VERSION "created by canmatrix"

NS_ :

BS_:

BU_: IPD

BO_ 591 ICBVC_BKPCANFD_50ms_FrP55: 12 Vector__XXX
 SG_ DrvrFtgLvl : 15|3@0+ (1,0) [0|7] "null" IPD
 SG_ ICMEyeOnRoad : 20|3@0+ (1,0) [0|7] "null" IPD
 SG_ DrvrDstrctnSts : 31|3@0+ (1,0) [0|7] "null" IPD
 SG_ ICMDrvrDstcnSts : 35|3@0+ (1,0) [0|7] "null" IPD
 SG_ ICMDrvrPrst : 60|3@0+ (1,0) [0|7] "null" IPD
 SG_ ICMDrvrFtgLvl : 63|3@0+ (1,0) [0|7] "null" IPD

BO_ 728 ICBVC_BKPCANFD_Event_FrS138: 24 Vector__XXX
 SG_ AIParkngReqICB : 183|8@0+ (1,0) [0|255] "null" IPD

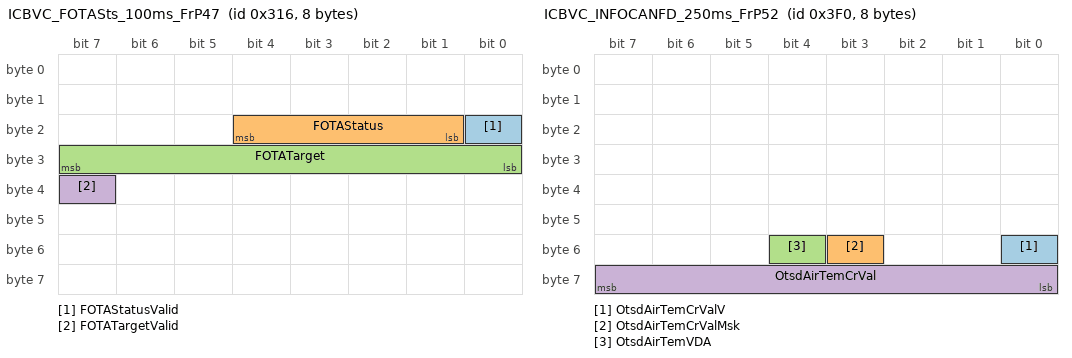
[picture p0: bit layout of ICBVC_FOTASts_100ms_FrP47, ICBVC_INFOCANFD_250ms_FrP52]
BO_ 790 ICBVC_FOTASts_100ms_FrP47: 8 Vector__XXX
 SG_ FOTAStatusValid : 16|1@0+ (1,0) [0|1] "null" IPD
 SG_ FOTAStatus : 20|4@0+ (1,0) [0|15] "null" IPD
 SG_ FOTATarget : 31|8@0+ (1,0) [0|255] "null" IPD
 SG_ FOTATargetValid : 39|1@0+ (1,0) [0|1] "null" IPD

BO_ 1008 ICBVC_INFOCANFD_250ms_FrP52: 8 Vector__XXX
 SG_ OtsdAirTemCrValV : 48|1@0+ (1,0) [0|1] "null" IPD
 SG_ OtsdAirTemCrValMsk : 51|1@0+ (1,0) [0|1] "null" IPD
 SG_ OtsdAirTemVDA : 52|1@0+ (1,0) [0|1] "null" Vector__XXX
 SG_ OtsdAirTemCrVal : 63|8@0+ (0.5,-40) [-40|87.5] "degreeCelsius" IPD

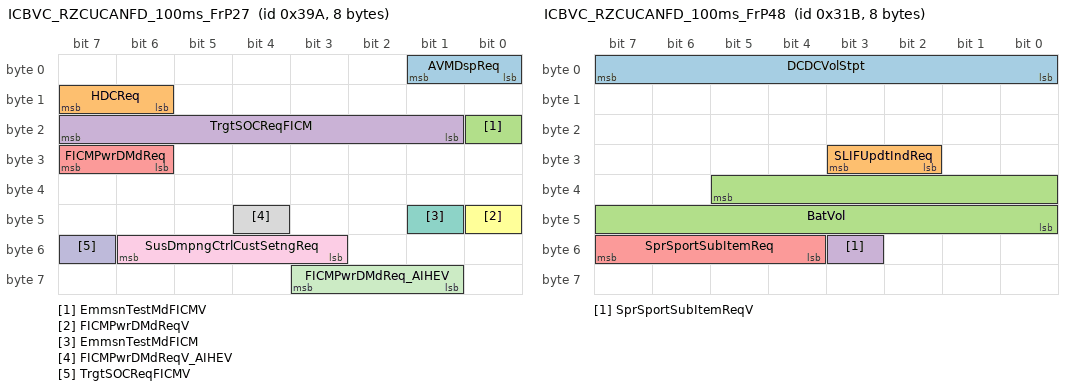
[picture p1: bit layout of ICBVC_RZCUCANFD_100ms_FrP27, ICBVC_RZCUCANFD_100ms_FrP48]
BO_ 922 ICBVC_RZCUCANFD_100ms_FrP27: 8 Vector__XXX
 SG_ AVMDspReq : 1|2@0+ (1,0) [0|3] "null" IPD
 SG_ HDCReq : 15|2@0+ (1,0) [0|3] "null" Vector__XXX
 SG_ EmmsnTestMdFICMV : 16|1@0+ (1,0) [0|1] "null" Vector__XXX
 SG_ TrgtSOCReqFICM : 23|7@0+ (1,0) [0|127] "null" Vector__XXX
 SG_ FICMPwrDMdReq : 31|2@0+ (1,0) [0|3] "null" Vector__XXX
 SG_ FICMPwrDMdReqV : 40|1@0+ (1,0) [0|1] "null" Vector__XXX
 SG_ EmmsnTestMdFICM : 41|1@0+ (1,0) [0|1] "null" Vector__XXX
 SG_ FICMPwrDMdReqV_AIHEV : 44|1@0+ (1,0) [0|1] "null" Vector__XXX
 SG_ SusDmpngCtrlCustSetngReq : 54|4@0+ (1,0) [0|15] "null" Vector__XXX
 SG_ TrgtSOCReqFICMV : 55|1@0+ (1,0) [0|1] "null" Vector__XXX
 SG_ FICMPwrDMdReq_AIHEV : 59|3@0+ (1,0) [0|7] "null" Vector__XXX

BO_ 795 ICBVC_RZCUCANFD_100ms_FrP48: 8 Vector__XXX
 SG_ DCDCVolStpt : 7|8@0+ (0.03125,8.5) [8.50000|16.46875] "V" Vector__XXX
 SG_ SLIFUpdtIndReq : 27|2@0+ (1,0) [0|3] "null" IPD
 SG_ BatVol : 37|14@0+ (0.00097656,3) [3.00000000|18.99898248] "V" Vector__XXX
 SG_ SprSportSubItemReqV : 51|1@0+ (1,0) [0|1] "null" Vector__XXX
 SG_ SprSportSubItemReq : 55|4@0+ (1,0) [0|15] "null" Vector__XXX

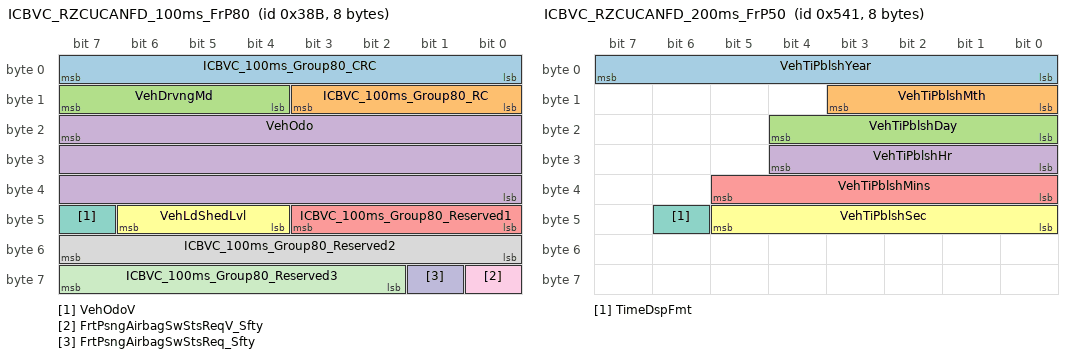
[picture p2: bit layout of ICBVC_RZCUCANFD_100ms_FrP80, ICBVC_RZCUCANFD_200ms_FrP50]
BO_ 907 ICBVC_RZCUCANFD_100ms_FrP80: 8 Vector__XXX
 SG_ ICBVC_100ms_Group80_CRC : 7|8@0+ (1,0) [0|255] "null" IPD
 SG_ ICBVC_100ms_Group80_RC : 11|4@0+ (1,0) [0|15] "null" IPD
 SG_ VehDrvngMd : 15|4@0+ (1,0) [0|15] "null" IPD
 SG_ VehOdo : 23|24@0+ (1,0) [0|16777215] "null" IPD
 SG_ ICBVC_100ms_Group80_Reserved1 : 43|4@0+ (1,0) [0|15] "null" IPD
 SG_ VehLdShedLvl : 46|3@0+ (1,0) [0|7] "null" IPD
 SG_ VehOdoV : 47|1@0+ (1,0) [0|1] "null" IPD
 SG_ ICBVC_100ms_Group80_Reserved2 : 55|8@0+ (1,0) [0|255] "null" IPD
 SG_ FrtPsngAirbagSwStsReqV_Sfty : 56|1@0+ (1,0) [0|1] "null" IPD
 SG_ FrtPsngAirbagSwStsReq_Sfty : 57|1@0+ (1,0) [0|1] "null" IPD
 SG_ ICBVC_100ms_Group80_Reserved3 : 63|6@0+ (1,0) [0|63] "null" IPD

BO_ 1345 ICBVC_RZCUCANFD_200ms_FrP50: 8 Vector__XXX
 SG_ VehTiPblshYear : 7|8@0+ (1,2000) [2000|2255] "year" IPD
 SG_ VehTiPblshMth : 11|4@0+ (1,0) [0|15] "null" IPD
 SG_ VehTiPblshDay : 20|5@0+ (1,0) [0|31] "days" IPD
 SG_ VehTiPblshHr : 28|5@0+ (1,0) [0|31] "hour" IPD
 SG_ VehTiPblshMins : 37|6@0+ (1,0) [0|63] "minute" IPD
 SG_ VehTiPblshSec : 45|6@0+ (1,0) [0|63] "second" IPD
 SG_ TimeDspFmt : 46|1@0+ (1,0) [0|1] "null" Vector__XXX

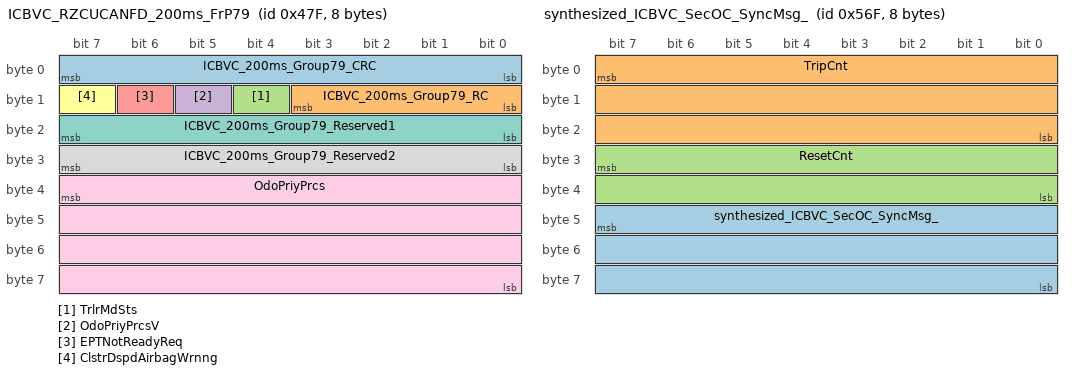
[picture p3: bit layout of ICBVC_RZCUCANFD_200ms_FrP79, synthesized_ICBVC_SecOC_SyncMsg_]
BO_ 1151 ICBVC_RZCUCANFD_200ms_FrP79: 8 Vector__XXX
 SG_ ICBVC_200ms_Group79_CRC : 7|8@0+ (1,0) [0|255] "null" IPD
 SG_ ICBVC_200ms_Group79_RC : 11|4@0+ (1,0) [0|15] "null" IPD
 SG_ TrlrMdSts : 12|1@0+ (1,0) [0|1] "null" IPD
 SG_ OdoPriyPrcsV : 13|1@0+ (1,0) [0|1] "null" IPD
 SG_ EPTNotReadyReq : 14|1@0+ (1,0) [0|1] "null" IPD
 SG_ ClstrDspdAirbagWrnng : 15|1@0+ (1,0) [0|1] "null" IPD
 SG_ ICBVC_200ms_Group79_Reserved1 : 23|8@0+ (1,0) [0|255] "null" IPD
 SG_ ICBVC_200ms_Group79_Reserved2 : 31|8@0+ (1,0) [0|255] "null" IPD
 SG_ OdoPriyPrcs : 39|32@0+ (0.1,0) [0|429496729.5] "null" IPD

BO_ 361 ICBVC_RZCUCANFD_20ms_FrP00: 8 Vector__XXX
 SG_ NFCAMAvlbly : 2|1@0+ (1,0) [0|1] "null" Vector__XXX
 SG_ SASAvlbly : 4|1@0+ (1,0) [0|1] "null" Vector__XXX
 SG_ SDMAvlbly : 5|1@0+ (1,0) [0|1] "null" IPD
 SG_ RHZCUAvlbly : 6|1@0+ (1,0) [0|1] "null" IPD
 SG_ LHZCUAvlbly : 7|1@0+ (1,0) [0|1] "null" IPD
 SG_ TC_ExtdAvlbly : 8|1@0+ (1,0) [0|1] "null" Vector__XXX
 SG_ IBS_SFAvlbly : 9|1@0+ (1,0) [0|1] "null" Vector__XXX
 SG_ EPSAvlbly : 10|1@0+ (1,0) [0|1] "null" IPD
 SG_ TC_PTAvlbly : 12|1@0+ (1,0) [0|1] "null" Vector__XXX
 SG_ PICU_PTAvlbly : 13|1@0+ (1,0) [0|1] "null" IPD
 SG_ LVBM_PTAvlbly : 14|1@0+ (1,0) [0|1] "null" Vector__XXX
 SG_ PEU_PTAvlbly : 16|1@0+ (1,0) [0|1] "null" Vector__XXX
 SG_ PEU_ERAvlbly : 17|1@0+ (1,0) [0|1] "null" Vector__XXX
 SG_ PICU_ExtdAvlbly : 18|1@0+ (1,0) [0|1] "null" Vector__XXX
 SG_ LHRDAAvlbly : 19|1@0+ (1,0) [0|1] "null" Vector__XXX
 SG_ IPD_PTAvlbly : 20|1@0+ (1,0) [0|1] "null" Vector__XXX
 SG_ RHMPWCAvlbly : 21|1@0+ (1,0) [0|1] "null" Vector__XXX
 SG_ ESS_PTAvlbly : 22|1@0+ (1,0) [0|1] "null" Vector__XXX
 SG_ CCU_ExtdAvlbly : 23|1@0+ (1,0) [0|1] "null" Vector__XXX
 SG_ ESS_ExtdAvlbly : 24|1@0+ (1,0) [0|1] "null" Vector__XXX
 SG_ CCU_PTAvlbly : 25|1@0+ (1,0) [0|1] "null" Vector__XXX
 SG_ IAMAvlbly : 26|1@0+ (1,0) [0|1] "null" IPD
 SG_ EAC_Avlbly : 27|1@0+ (1,0) [0|1] "null" Vector__XXX
 SG_ PEU_SFAvlbly : 30|1@0+ (1,0) [0|1] "null" Vector__XXX
 SG_ PEU_ExtdAvlbly : 31|1@0+ (1,0) [0|1] "null" Vector__XXX
 SG_ TDMAvlbly : 32|1@0+ (1,0) [0|1] "null" IPD
 SG_ IPD_SFAvlbly : 33|1@0+ (1,0) [0|1] "null" Vector__XXX
 SG_ SAC_ExtdAvlbly : 35|1@0+ (1,0) [0|1] "null" Vector__XXX
 SG_ SAC_PTAvlbly : 36|1@0+ (1,0) [0|1] "null" Vector__XXX
 SG_ CCEOPAvlbly : 38|1@0+ (1,0) [0|1] "null" Vector__XXX
 SG_ RZCU_BKBCANFDAvlbly : 39|1@0+ (1,0) [0|1] "null" IPD
 SG_ IPD_BKPCANFDAvlbly : 40|1@0+ (1,0) [0|1] "null" Vector__XXX
 SG_ IPD_CHCANFDAvlbly : 41|1@0+ (1,0) [0|1] "null" Vector__XXX
 SG_ IBS_CHAvlbly : 43|1@0+ (1,0) [0|1] "null" IPD
 SG_ FDRAvlbly : 44|1@0+ (1,0) [0|1] "null" Vector__XXX
 SG_ RHRDAAvlbly : 49|1@0+ (1,0) [0|1] "null" Vector__XXX
 SG_ FVCMAvlbly : 51|1@0+ (1,0) [0|1] "null" Vector__XXX
 SG_ TPMSAvlbly : 63|1@0+ (1,0) [0|1] "null" Vector__XXX

BO_ 497 ICBVC_RZCUCANFD_20ms_FrP03: 8 Vector__XXX
 SG_ ICBVC_20ms_Group03_CRC : 7|8@0+ (1,0) [0|255] "null" IPD
 SG_ ICBVC_20ms_Group03_RC : 11|4@0+ (1,0) [0|15] "null" IPD
 SG_ AMRPrtensonReq : 15|4@0+ (1,0) [0|15] "null" IPD
 SG_ ICBVC_20ms_Group03_Reserved2 : 19|4@0+ (1,0) [0|15] "null" IPD
 SG_ SysVolMdV : 20|1@0+ (1,0) [0|1] "null" IPD
 SG_ ICBVC_20ms_Group03_Reserved1 : 23|3@0+ (1,0) [0|7] "null" IPD
 SG_ ICBVC_20ms_Group03_Reserved3 : 27|4@0+ (1,0) [0|15] "null" IPD
 SG_ VehMd : 31|4@0+ (1,0) [0|15] "null" IPD
 SG_ SysVolV : 32|1@0+ (1,0) [0|1] "null" IPD
 SG_ SysPwrMdV : 33|1@0+ (1,0) [0|1] "null" IPD
 SG_ VehMdV : 34|1@0+ (1,0) [0|1] "null" IPD
 SG_ UsgMdV : 35|1@0+ (1,0) [0|1] "null" IPD
 SG_ UsgMd : 39|4@0+ (1,0) [0|15] "null" IPD
 SG_ SysVol : 47|8@0+ (0.1,3) [3|28.5] "V" IPD
 SG_ PwrMdMstrRunCrkA : 48|1@0+ (1,0) [0|1] "null" IPD
 SG_ SysPwrMd : 50|2@0+ (1,0) [0|3] "null" IPD
 SG_ PwrMdMstrAccryA : 51|1@0+ (1,0) [0|1] "null" IPD
 SG_ SysOpnlMd : 55|4@0+ (1,0) [0|15] "null" IPD
 SG_ ICBVC_20ms_Group03_Reserved4 : 60|5@0+ (1,0) [0|31] "null" IPD
 SG_ BPMMstrAvlbly : 61|1@0+ (1,0) [0|1] "null" IPD
 SG_ SysVolMd : 63|2@0+ (1,0) [0|3] "null" IPD

BO_ 60 ICBVC_SecOC_ComKeyReq: 8 Vector__XXX
 SG_ TripCntResetReq : 6|1@0+ (1,0) [0|1] "null" IPD
 SG_ ComKeyEnbReq : 7|1@0+ (1,0) [0|1] "null" IPD

BO_ 1391 synthesized_ICBVC_SecOC_SyncMsg_: 8 Vector__XXX
 SG_ synthesized_ICBVC_SecOC_SyncMsg_ : 47|24@0+ (1,0) [0|16777215] "Unitless" Vector__XXX
 SG_ TripCnt : 7|24@0+ (1,0) [0|16777215] "null" IPD
 SG_ ResetCnt : 31|16@0+ (1,0) [0|65535] "null" IPD

BO_ 815 ICB_BKBCANFD_100ms_FrP146: 8 Vector__XXX
 SG_ EMCLPwrSts : 12|1@0+ (1,0) [0|1] "null" Vector__XXX
 SG_ IMMPwrSts : 14|1@0+ (1,0) [0|1] "null" Vector__XXX
 SG_ ESCLPwrSts : 20|1@0+ (1,0) [0|1] "null" IPD
 SG_ BPEPSPwrSts : 25|1@0+ (1,0) [0|1] "null" Vector__XXX
 SG_ ARHUDPwrSts : 29|1@0+ (1,0) [0|1] "null" Vector__XXX
 SG_ LHAmbtLampPwrSts : 30|1@0+ (1,0) [0|1] "null" Vector__XXX
 SG_ OHCPwrSts : 31|1@0+ (1,0) [0|1] "null" Vector__XXX
 SG_ CnsoDspPwrSts : 33|1@0+ (1,0) [0|1] "null" Vector__XXX
 SG_ FLVntngMotPwrSts : 34|1@0+ (1,0) [0|1] "null" Vector__XXX
 SG_ FLSLMMPwrSts : 35|1@0+ (1,0) [0|1] "null" Vector__XXX
 SG_ USBHubPwrSts : 36|1@0+ (1,0) [0|1] "null" Vector__XXX
 SG_ DrvrDspPwrSts : 37|1@0+ (1,0) [0|1] "null" Vector__XXX
 SG_ SWSPwrSts : 38|1@0+ (1,0) [0|1] "null" Vector__XXX
 SG_ BrkSwPwrSts : 39|1@0+ (1,0) [0|1] "null" Vector__XXX
 SG_ HODMPwrSts : 40|1@0+ (1,0) [0|1] "null" Vector__XXX
 SG_ RLSSPwrSts : 42|1@0+ (1,0) [0|1] "null" Vector__XXX
 SG_ ETCMPwrSts : 43|1@0+ (1,0) [0|1] "null" Vector__XXX
 SG_ LHSWPwrSts : 44|1@0+ (1,0) [0|1] "null" IPD
 SG_ NFCAMPwrSts : 45|1@0+ (1,0) [0|1] "null" Vector__XXX
 SG_ NFCSMPwrSts : 46|1@0+ (1,0) [0|1] "null" Vector__XXX
 SG_ SACPwrSts : 49|1@0+ (1,0) [0|1] "null" Vector__XXX
 SG_ CnsoUSBPwrSts : 50|1@0+ (1,0) [0|1] "null" Vector__XXX
 SG_ RrPDCPwrSts : 51|1@0+ (1,0) [0|1] "null" Vector__XXX
 SG_ FrtPDCPwrSts : 52|1@0+ (1,0) [0|1] "null" Vector__XXX
 SG_ FVCMPwrSts : 55|1@0+ (1,0) [0|1] "null" Vector__XXX
 SG_ TPMSPwrSts : 57|1@0+ (1,0) [0|1] "null" Vector__XXX
 SG_ AIBOTPwrSts : 59|1@0+ (1,0) [0|1] "null" Vector__XXX
 SG_ IterMirPwrSts : 60|1@0+ (1,0) [0|1] "null" Vector__XXX
 SG_ IMSPwrSts : 61|1@0+ (1,0) [0|1] "null" Vector__XXX
 SG_ CPDPwrSts : 62|1@0+ (1,0) [0|1] "null" Vector__XXX
 SG_ DABMPwrSts : 63|1@0+ (1,0) [0|1] "null" Vector__XXX

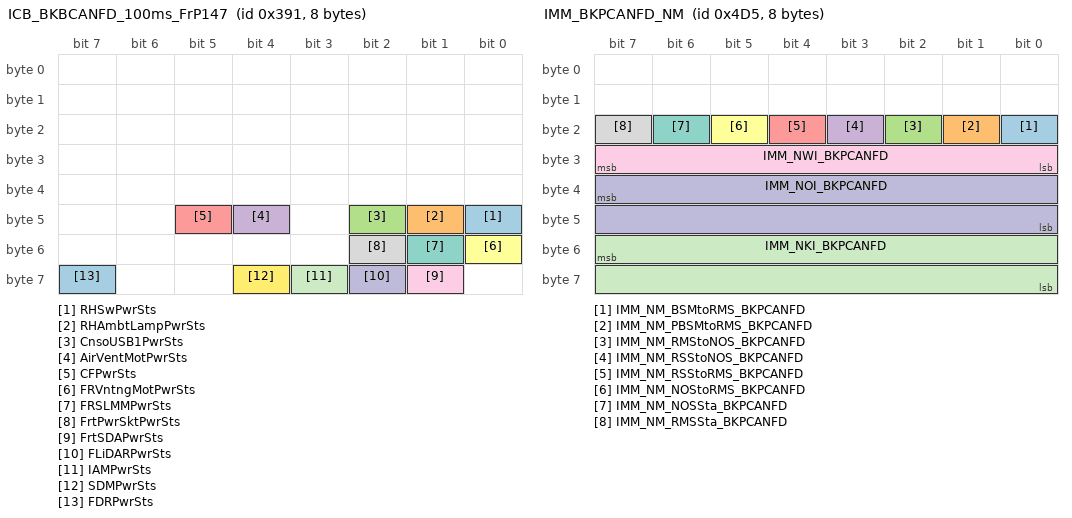
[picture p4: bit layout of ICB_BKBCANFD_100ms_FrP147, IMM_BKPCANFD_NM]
BO_ 913 ICB_BKBCANFD_100ms_FrP147: 8 Vector__XXX
 SG_ RHSwPwrSts : 40|1@0+ (1,0) [0|1] "null" Vector__XXX
 SG_ RHAmbtLampPwrSts : 41|1@0+ (1,0) [0|1] "null" Vector__XXX
 SG_ CnsoUSB1PwrSts : 42|1@0+ (1,0) [0|1] "null" Vector__XXX
 SG_ AirVentMotPwrSts : 44|1@0+ (1,0) [0|1] "null" Vector__XXX
 SG_ CFPwrSts : 45|1@0+ (1,0) [0|1] "null" Vector__XXX
 SG_ FRVntngMotPwrSts : 48|1@0+ (1,0) [0|1] "null" Vector__XXX
 SG_ FRSLMMPwrSts : 49|1@0+ (1,0) [0|1] "null" Vector__XXX
 SG_ FrtPwrSktPwrSts : 50|1@0+ (1,0) [0|1] "null" Vector__XXX
 SG_ FrtSDAPwrSts : 57|1@0+ (1,0) [0|1] "null" Vector__XXX
 SG_ FLiDARPwrSts : 58|1@0+ (1,0) [0|1] "null" IPD
 SG_ IAMPwrSts : 59|1@0+ (1,0) [0|1] "null" Vector__XXX
 SG_ SDMPwrSts : 60|1@0+ (1,0) [0|1] "null" Vector__XXX
 SG_ FDRPwrSts : 63|1@0+ (1,0) [0|1] "null" IPD

BO_ 902 ICB_BKBCANFD_100ms_FrP221: 24 Vector__XXX
 SG_ AVPMapRutMgIDtReq : 71|10@0+ (1,0) [0|1023] "null" IPD
 SG_ IPDPowerFailSwReq : 97|2@0+ (1,0) [0|3] "null" IPD
 SG_ RACtlReq : 111|3@0+ (1,0) [0|7] "null" IPD
 SG_ ShwrmComprEnbReq : 125|1@0+ (1,0) [0|1] "null" Vector__XXX
 SG_ SrfOpenSts : 140|3@0+ (1,0) [0|7] "null" Vector__XXX
 SG_ RainClsWndAppMsg : 183|3@0+ (1,0) [0|7] "null" Vector__XXX

BO_ 955 ICB_BKPCANFD_100ms_FrP159: 64 Vector__XXX
 SG_ ClstrDspdVehSpd_mph : 7|8@0+ (1,0) [0|255] "kph" IPD
 SG_ RrSsdPosCtrl : 15|8@0+ (1,0) [0|255] "null" Vector__XXX
 SG_ ACCTJAMdSwReq : 18|3@0+ (1,0) [0|7] "null" IPD
 SG_ FICMACLTemReq : 23|5@0+ (0.5,15.5) [15.5|31] "null" Vector__XXX
 SG_ SpdLmtOfstSetReq : 31|6@0+ (1,-20) [-20|43] "null" IPD
 SG_ ACCStsSwReq : 33|2@0+ (1,0) [0|3] "null" IPD
 SG_ ACCSpdLimtSwReq : 35|2@0+ (1,0) [0|3] "null" IPD
 SG_ ACCCurveSpdSwReq : 37|2@0+ (1,0) [0|3] "null" IPD
 SG_ ACCConfmSwReq : 39|2@0+ (1,0) [0|3] "null" IPD
 SG_ ACUserCustEcoSetngReqV : 40|1@0+ (1,0) [0|1] "null" Vector__XXX
 SG_ ACUserCustEcoSetngReq : 42|2@0+ (1,0) [0|3] "null" Vector__XXX
 SG_ ACUserCustAutoMdBlwrReqV : 43|1@0+ (1,0) [0|1] "null" Vector__XXX
 SG_ ACUserCustAutoMdBlwrReq : 45|2@0+ (1,0) [0|3] "null" Vector__XXX
 SG_ ACUserCustAftRunOnOffReqV : 46|1@0+ (1,0) [0|1] "null" Vector__XXX
 SG_ ACUserCustAftRunOnOffR : 47|1@0+ (1,0) [0|1] "null" Vector__XXX
 SG_ FICMACFrtBlwrSpdDecSwR : 49|2@0+ (1,0) [0|3] "null" Vector__XXX
 SG_ FICMACAutoSwReq : 51|2@0+ (1,0) [0|3] "null" Vector__XXX
 SG_ ADAudioSWReq : 55|2@0+ (1,0) [0|3] "null" IPD
 SG_ FICMACLTemDecSwReq : 57|2@0+ (1,0) [0|3] "null" Vector__XXX
 SG_ FICMACFrtBlwrSpdIncSwR : 59|2@0+ (1,0) [0|3] "null" Vector__XXX
 SG_ FICMACFrtBlwrLvlReq : 63|4@0+ (1,0) [0|15] "null" Vector__XXX
 SG_ FICMACOnOffSwReq : 65|2@0+ (1,0) [0|3] "null" Vector__XXX
 SG_ FICMACLTemIncSwReq : 67|2@0+ (1,0) [0|3] "null" Vector__XXX
 SG_ FICMACLAirMdReqV : 68|1@0+ (1,0) [0|1] "null" Vector__XXX
 SG_ FICMACLAirMdReq : 71|3@0+ (1,0) [0|7] "null" Vector__XXX
 SG_ FICMComprOnOffSwReq : 73|2@0+ (1,0) [0|3] "null" Vector__XXX
 SG_ FICMACSemiAutoSwReq : 75|2@0+ (1,0) [0|3] "null" Vector__XXX
 SG_ FICMACRcctnSwReq : 77|2@0+ (1,0) [0|3] "null" Vector__XXX
 SG_ FICMACRcctnMdReq : 79|2@0+ (1,0) [0|3] "null" Vector__XXX
 SG_ FICMHtdRrWndSwReq : 81|2@0+ (1,0) [0|3] "null" Vector__XXX
 SG_ FICMDfstOnSwReq : 83|2@0+ (1,0) [0|3] "null" Vector__XXX
 SG_ FICMACLTemV : 87|1@0+ (1,0) [0|1] "null" Vector__XXX
 SG_ TLRMdSwReq : 90|3@0+ (1,0) [0|7] "null" IPD
 SG_ TSRSwReq : 97|2@0+ (1,0) [0|3] "null" IPD
 SG_ NonDirectDMSSwReq : 99|2@0+ (1,0) [0|3] "null" IPD
 SG_ SpdLmtOfstSetNumReq : 103|4@0+ (1,0) [0|15] "null" IPD
 SG_ ILCSwReq : 108|2@0+ (1,0) [0|3] "null" IPD
 SG_ ASSInhBtnA : 109|1@0+ (1,0) [0|1] "null" Vector__XXX
 SG_ ClstrElecCsumpUnit : 114|3@0+ (1,0) [0|7] "null" Vector__XXX
 SG_ SpdLmtOfstSetPercReq : 127|3@0+ (1,0) [0|7] "null" IPD
 SG_ EBSBatSOFVol1 : 143|8@0+ (0.0625,0) [0.0000|15.9375] "null" Vector__XXX
 SG_ EBSBatSOFVol2 : 151|8@0+ (0.0625,0) [0.0000|15.9375] "null" Vector__XXX
 SG_ EBSBatSOFVol2Sts : 153|2@0+ (1,0) [0|3] "null" Vector__XXX
 SG_ GenrExctnCrnt : 159|6@0+ (0.125,0) [0.000|7.875] "null" Vector__XXX
 SG_ ASSStsFICM : 160|1@0+ (1,0) [0|1] "null" Vector__XXX
 SG_ EBSBatSOFVol1Sts : 162|2@0+ (1,0) [0|3] "null" Vector__XXX
 SG_ GenrExctnDutyCyc : 167|5@0+ (3.333,0) [0.000|103.323] "null" Vector__XXX
 SG_ IACCPreSpdLimtSwReq : 169|2@0+ (1,0) [0|3] "null" IPD
 SG_ PMDCIlgclIdficn : 170|1@0+ (1,0) [0|1] "null" Vector__XXX
 SG_ EBSBatIncnstncyFlag : 171|1@0+ (1,0) [0|1] "null" Vector__XXX
 SG_ ASSStsFICMV : 172|1@0+ (1,0) [0|1] "null" Vector__XXX
 SG_ PMDCIlgclCal : 173|1@0+ (1,0) [0|1] "null" Vector__XXX
 SG_ IdleBstLvl : 175|2@0+ (1,0) [0|3] "null" Vector__XXX
 SG_ ExtnlTstrDet : 176|1@0+ (1,0) [0|1] "null" Vector__XXX
 SG_ TiltSnsrSetngReq : 178|2@0+ (1,0) [0|3] "null" Vector__XXX
 SG_ RrSsdAppCtrl : 180|2@0+ (1,0) [0|3] "null" Vector__XXX
 SG_ IACCOvTSuppresSwReq : 183|3@0+ (1,0) [0|7] "null" IPD
 SG_ TrgtSOCReqAI : 185|10@0+ (0.1,0) [0|102.3] "null" Vector__XXX
 SG_ DMSHapticWrnngReq : 187|2@0+ (1,0) [0|3] "null" Vector__XXX
 SG_ DMSAdoWrnngReq : 189|2@0+ (1,0) [0|3] "null" Vector__XXX
 SG_ VolmcSnsrSetngReq : 191|2@0+ (1,0) [0|3] "null" Vector__XXX
 SG_ DMSDstrctnHptWrnngReq : 201|2@0+ (1,0) [0|3] "null" Vector__XXX
 SG_ DMSDstrctnAdoWrnngReq : 203|2@0+ (1,0) [0|3] "null" Vector__XXX
 SG_ DMSDstrctnSwReq : 205|2@0+ (1,0) [0|3] "null" Vector__XXX
 SG_ DMSSwReq : 207|2@0+ (1,0) [0|3] "null" Vector__XXX
 SG_ FICMInnrDschrgReq : 212|1@0+ (1,0) [0|1] "null" Vector__XXX
 SG_ OMSSwReq : 214|2@0+ (1,0) [0|3] "null" Vector__XXX
 SG_ TrgtSOCReqAIV : 215|1@0+ (1,0) [0|1] "null" Vector__XXX
 SG_ OMSBabyCareReq : 241|2@0+ (1,0) [0|3] "null" Vector__XXX
 SG_ OmsGesDetSwReq : 243|2@0+ (1,0) [0|3] "null" Vector__XXX
 SG_ OmsIlbRemSwReq : 245|2@0+ (1,0) [0|3] "null" Vector__XXX
 SG_ AIParkngSSPLotSw : 247|2@0+ (1,0) [0|3] "null" IPD
 SG_ TakeKeyOutRmndrPersSetReq : 322|2@0+ (1,0) [0|3] "null" Vector__XXX
 SG_ CmftUnlckPersSetReq : 324|2@0+ (1,0) [0|3] "null" Vector__XXX
 SG_ CmftLckPersSetReq : 326|2@0+ (1,0) [0|3] "null" Vector__XXX

BO_ 746 ICB_BKPCANFD_100ms_FrP82: 8 Vector__XXX
 SG_ FCTSysSelReq : 13|2@0+ (1,0) [0|3] "null" IPD

BO_ 1297 ICB_BKPCANFD_500ms_FrP229: 20 Vector__XXX
 SG_ NavCtryCode_ISO : 23|10@0+ (1,0) [0|1023] "null" IPD

BO_ 368 ICB_BKPCANFD_50ms_FrP158: 16 Vector__XXX
 SG_ ICBVC_50ms_Group158_CRC : 7|8@0+ (1,0) [0|255] "null" IPD
 SG_ ICBVC_50ms_Group158_RC : 11|4@0+ (1,0) [0|15] "null" IPD
 SG_ CCSpdDecAndIncVcCmd : 13|2@0+ (1,0) [0|3] "null" IPD
 SG_ CCDisDecAndIncVcCmd : 15|2@0+ (1,0) [0|3] "null" IPD
 SG_ ICBVC_50ms_Group158_Reserved1 : 19|4@0+ (1,0) [0|15] "null" IPD
 SG_ CCSwStsSetSwA : 20|1@0+ (1,0) [0|1] "null" IPD
 SG_ CCSwStsCCASwA : 21|1@0+ (1,0) [0|1] "null" IPD
 SG_ CCSpdVcCmdSwReq : 23|2@0+ (1,0) [0|3] "null" IPD
 SG_ CCSpdVcCmd : 31|8@0+ (1,0) [0|255] "null" IPD
 SG_ ICBVC_50ms_Group158_Reserved2 : 39|8@0+ (1,0) [0|255] "null" IPD
 SG_ ICBVC_50ms_Group158_Reserved3 : 44|5@0+ (1,0) [0|31] "null" IPD
 SG_ CCDisAdjtVcCmd : 47|3@0+ (1,0) [0|7] "null" IPD
 SG_ ICBVC_50ms_Group158_Reserved4 : 55|8@0+ (1,0) [0|255] "null" IPD
 SG_ ICBVC_50ms_Group158_Reserved5 : 63|8@0+ (1,0) [0|255] "null" IPD
 SG_ ICBVC_50ms_Group158_Reserved6 : 71|8@0+ (1,0) [0|255] "null" IPD
 SG_ ICBVC_50ms_Group158_Reserved7 : 79|8@0+ (1,0) [0|255] "null" IPD
 SG_ ICBVC_50ms_Group158_Reserved8 : 87|8@0+ (1,0) [0|255] "null" IPD
 SG_ ICBVC_50ms_Group158_Reserved9 : 95|8@0+ (1,0) [0|255] "null" IPD
 SG_ ICBVC_50ms_Group158_Reserved10 : 103|8@0+ (1,0) [0|255] "null" IPD
 SG_ ICBVC_50ms_Group158_Reserved11 : 111|8@0+ (1,0) [0|255] "null" IPD
 SG_ ICBVC_50ms_Group158_Reserved12 : 119|8@0+ (1,0) [0|255] "null" IPD
 SG_ ICBVC_50ms_Group158_Reserved13 : 127|8@0+ (1,0) [0|255] "null" IPD

BO_ 1389 ICB_CONNCANFD_Event_FrS67: 16 Vector__XXX
 SG_ IdentityChlg : 71|64@0+ (1,0) [0|18446744073709551615] "null" IPD

BO_ 1111 ICB_ZONE_BDCAN_100ms_FrP00: 32 Vector__XXX
 SG_ ICCPCBTemp1 : 7|8@0+ (1,-40) [-40|215] "" Vector__XXX
 SG_ ICCPCBTemp2 : 15|8@0+ (1,-40) [-40|215] "" Vector__XXX
 SG_ ICCPCBTemp3 : 23|8@0+ (1,-40) [-40|215] "" Vector__XXX
 SG_ ICCPCBTemp4 : 31|8@0+ (1,-40) [-40|215] "" Vector__XXX
 SG_ ICCPCBTemp5 : 39|8@0+ (1,-40) [-40|215] "" Vector__XXX
 SG_ ICCThermalCoolingLvl : 47|4@0+ (1,0) [0|15] "null" Vector__XXX
 SG_ FICMV2XEnEnbReq : 81|2@0+ (1,0) [0|3] "null" Vector__XXX
 SG_ ElecPwrDistbnScene : 95|64@0+ (1,0) [0|18446744073709551615] "null" IPD
 SG_ AltngChrgCrntReq : 159|8@0+ (1,0) [0|255] "null" Vector__XXX
 SG_ DschrgTrgtSOCVal : 167|7@0+ (1,0) [0|127] "null" Vector__XXX

BO_ 527 IMM_BKPCANFD_50ms_FrP02: 24 Vector__XXX
 SG_ IMM_50ms_Group02_CRC : 7|8@0+ (1,0) [0|255] "null" IPD
 SG_ IMM_50ms_Group02_RC : 11|4@0+ (1,0) [0|15] "null" IPD
 SG_ IMM_50ms_Group02_Reserved1 : 15|4@0+ (1,0) [0|15] "null" IPD
 SG_ DrvrDstcnStsINST_IMM : 19|4@0+ (1,0) [0|15] "null" IPD
 SG_ ILBRReq_IMM : 23|4@0+ (1,0) [0|15] "null" IPD
 SG_ DrvrAbnormBehvor_IMM : 27|4@0+ (1,0) [0|15] "null" IPD
 SG_ DMSSts_IMM : 31|4@0+ (1,0) [0|15] "null" IPD
 SG_ IMM_50ms_Group02_Reserved2 : 33|2@0+ (1,0) [0|3] "null" IPD
 SG_ SpfngDet_IMM : 35|2@0+ (1,0) [0|3] "null" IPD
 SG_ DrvrDstcnSts_IMM : 39|4@0+ (1,0) [0|15] "null" IPD
 SG_ OMSSts_IMM : 42|3@0+ (1,0) [0|7] "null" IPD
 SG_ DrvrFtgLvlINST_IMM : 47|5@0+ (1,0) [0|31] "null" IPD
 SG_ IMM_50ms_Group02_Reserved3 : 50|3@0+ (1,0) [0|7] "null" IPD
 SG_ DrvrFtgLvl_IMM : 55|5@0+ (1,0) [0|31] "null" IPD
 SG_ DrvrPrst_IMM : 58|3@0+ (1,0) [0|7] "null" IPD
 SG_ DrvrGazeRgn_IMM : 63|5@0+ (1,0) [0|31] "null" IPD
 SG_ IMM_50ms_Group02_Reserved4 : 71|8@0+ (1,0) [0|255] "null" IPD
 SG_ EyeOpenStatus_IMM : 73|2@0+ (1,0) [0|3] "null" IPD
 SG_ IMM_50ms_Group02_Reserved5 : 79|6@0+ (1,0) [0|63] "null" IPD
 SG_ IMM_50ms_Group02_Reserved6 : 80|1@0+ (1,0) [0|1] "null" IPD
 SG_ RightEyeOccludeStatus_IMM : 82|2@0+ (1,0) [0|3] "null" IPD
 SG_ LeftEyeOccludeStatus_IMM : 84|2@0+ (1,0) [0|3] "null" IPD
 SG_ EyeOnRoad_IMM : 87|3@0+ (1,0) [0|7] "null" IPD
 SG_ DrvrFtgConf_IMM : 95|8@0+ (0.01,0) [0.00|2.55] "null" IPD
 SG_ DrvrDstcnConf_IMM : 103|8@0+ (0.01,0) [0.00|2.55] "null" IPD
 SG_ DrvrAbnormConf_IMM : 111|8@0+ (0.01,0) [0.00|2.55] "null" IPD
 SG_ EyeGazepitch_IMM : 119|8@0- (1,0) [-128|127] "null" IPD
 SG_ EyeGazeyaw_IMM : 127|8@0- (1,0) [-128|127] "null" IPD
 SG_ EyeOpenDegree_IMM : 135|8@0+ (0.01,0) [0.00|2.55] "null" IPD
 SG_ IMM_50ms_Group02_Reserved143 : 143|8@0+ (1,0) [0|255] "null" IPD
 SG_ IMM_50ms_Group02_Reserved151 : 151|8@0+ (1,0) [0|255] "null" IPD
 SG_ IMM_50ms_Group02_Reserved159 : 159|8@0+ (1,0) [0|255] "null" IPD
 SG_ IMM_50ms_Group02_Reserved7 : 163|4@0+ (1,0) [0|15] "null" IPD
 SG_ MouthOccludeStatus_IMM : 165|2@0+ (1,0) [0|3] "null" IPD
 SG_ YawnStatus_IMM : 167|2@0+ (1,0) [0|3] "null" IPD
 SG_ IMM_50ms_Group02_Reserved8 : 175|8@0+ (1,0) [0|255] "null" IPD
 SG_ IMM_50ms_Group02_Reserved9 : 183|8@0+ (1,0) [0|255] "null" IPD
 SG_ IMM_50ms_Group02_Reserved10 : 191|8@0+ (1,0) [0|255] "null" IPD

BO_ 657 IMM_BKPCANFD_50ms_FrP04: 64 Vector__XXX
 SG_ DMSCameraFps_IMM : 7|8@0+ (1,0) [0|255] "null" IPD

BO_ 1237 IMM_BKPCANFD_NM: 8 Vector__XXX
 SG_ IMM_NM_BSMtoRMS_BKPCANFD : 16|1@0+ (1,0) [0|1] "null" Vector__XXX
 SG_ IMM_NM_PBSMtoRMS_BKPCANFD : 17|1@0+ (1,0) [0|1] "null" Vector__XXX
 SG_ IMM_NM_RMStoNOS_BKPCANFD : 18|1@0+ (1,0) [0|1] "null" Vector__XXX
 SG_ IMM_NM_RSStoNOS_BKPCANFD : 19|1@0+ (1,0) [0|1] "null" Vector__XXX
 SG_ IMM_NM_RSStoRMS_BKPCANFD : 20|1@0+ (1,0) [0|1] "null" Vector__XXX
 SG_ IMM_NM_NOStoRMS_BKPCANFD : 21|1@0+ (1,0) [0|1] "null" Vector__XXX
 SG_ IMM_NM_NOSSta_BKPCANFD : 22|1@0+ (1,0) [0|1] "null" Vector__XXX
 SG_ IMM_NM_RMSSta_BKPCANFD : 23|1@0+ (1,0) [0|1] "null" Vector__XXX
 SG_ IMM_NWI_BKPCANFD : 31|8@0+ (1,0) [0|255] "null" Vector__XXX
 SG_ IMM_NOI_BKPCANFD : 39|16@0+ (1,0) [0|65535] "null" Vector__XXX
 SG_ IMM_NKI_BKPCANFD : 55|16@0+ (1,0) [0|65535] "null" Vector__XXX

BO_ 1767 IPD_BKBCANFD_EvtInfo: 64 IPD
 SG_ EvtPotclSigIPD1 : 7|64@0+ (1,0) [0|18446744073709551615] "null" Vector__XXX
 SG_ EvtPotclSigIPD2 : 71|64@0+ (1,0) [0|18446744073709551615] "null" Vector__XXX
 SG_ EvtPotclSigIPD3 : 135|64@0+ (1,0) [0|18446744073709551615] "null" Vector__XXX
 SG_ EvtPotclSigIPD4 : 199|64@0+ (1,0) [0|18446744073709551615] "null" Vector__XXX
 SG_ EvtPotclSigIPD5 : 263|64@0+ (1,0) [0|18446744073709551615] "null" Vector__XXX
 SG_ EvtPotclSigIPD6 : 327|64@0+ (1,0) [0|18446744073709551615] "null" Vector__XXX
 SG_ EvtPotclSigIPD7 : 391|64@0+ (1,0) [0|18446744073709551615] "null" Vector__XXX
 SG_ EvtPotclSigIPD8 : 455|64@0+ (1,0) [0|18446744073709551615] "null" Vector__XXX

CM_ SG_ 1391 synthesized_ICBVC_SecOC_SyncMsg_ "Truncated Auth-Info";

BA_DEF_ BO_ "FrameTriggeringName" STRING;
BA_DEF_ BO_ "GenMsgCycleTime" INT 0 65535;
BA_DEF_ BO_ "GenMsgDelayTime" INT 0 65535;
BA_DEF_ BO_ "GenMsgSendType" ENUM  "cyclicX","spontanX","cyclicIfActiveX","spontanWithDelay","cyclicAndSpontanX","cyclicAndSpontanWithDelay","spontanWithRepitition","cyclicIfActiveAndSpontanWD","cyclicIfActiveFast","cyclicWithRepeatOnDemand","none";
BA_DEF_ BO_ "GenMsgStartValue" STRING;
BA_DEF_ BO_ "PduName" STRING;
BA_DEF_ BO_ "SystemMessageLongSymbol" STRING;
BA_DEF_ BO_ "VFrameFormat" ENUM  "StandardCAN","ExtendedCAN","reserved","reserved","reserved","reserved","reserved","reserved","reserved","reserved","reserved","reserved","reserved","reserved","StandardCAN_FD","ExtendedCAN_FD";
BA_DEF_ SG_ "CompuMethodName" STRING;
BA_DEF_ SG_ "GenSigStartValue" FLOAT 0 100000000000;
BA_DEF_ SG_ "ISignalName" STRING;
BA_DEF_ SG_ "LongName" STRING;
BA_DEF_ SG_ "SysSignalName" STRING;
BA_DEF_ SG_ "SystemSignalLongSymbol" STRING;
BA_ "FrameTriggeringName" BO_ 591 "ICBVC_BKPCANFD_50ms_FrP55";
BA_ "GenMsgCycleTime" BO_ 591 50;
BA_ "GenMsgSendType" BO_ 591 0;
BA_ "GenMsgStartValue" BO_ 591 "000000000000000000000000";
BA_ "PduName" BO_ 591 "ICBVC_50ms_PDU55";
BA_ "VFrameFormat" BO_ 591 14;
BA_ "FrameTriggeringName" BO_ 728 "ICBVC_BKPCANFD_Event_FrS138";
BA_ "GenMsgSendType" BO_ 728 1;
BA_ "GenMsgStartValue" BO_ 728 "000000000000000000000000000000000000000000000000";
BA_ "PduName" BO_ 728 "ICBVC_Sporadic_PDU138";
BA_ "VFrameFormat" BO_ 728 14;
BA_ "FrameTriggeringName" BO_ 790 "ICBVC_FOTASts_100ms_FrP47";
BA_ "GenMsgCycleTime" BO_ 790 100;
BA_ "GenMsgSendType" BO_ 790 0;
BA_ "GenMsgStartValue" BO_ 790 "0000010080000000";
BA_ "PduName" BO_ 790 "ICBVC_100ms_PDU47";
BA_ "VFrameFormat" BO_ 790 14;
BA_ "FrameTriggeringName" BO_ 1008 "ICBVC_INFOCANFD_250ms_FrP52";
BA_ "GenMsgCycleTime" BO_ 1008 250;
BA_ "GenMsgSendType" BO_ 1008 0;
BA_ "GenMsgStartValue" BO_ 1008 "0000000000000100";
BA_ "PduName" BO_ 1008 "ICBVC_250ms_PDU52";
BA_ "VFrameFormat" BO_ 1008 14;
BA_ "FrameTriggeringName" BO_ 922 "ICBVC_RZCUCANFD_100ms_FrP27";
BA_ "GenMsgCycleTime" BO_ 922 100;
BA_ "GenMsgSendType" BO_ 922 0;
BA_ "GenMsgStartValue" BO_ 922 "0000010000110000";
BA_ "PduName" BO_ 922 "ICBVC_100ms_PDU27";
BA_ "VFrameFormat" BO_ 922 14;
BA_ "FrameTriggeringName" BO_ 795 "ICBVC_RZCUCANFD_100ms_FrP48";
BA_ "GenMsgCycleTime" BO_ 795 100;
BA_ "GenMsgSendType" BO_ 795 0;
BA_ "GenMsgStartValue" BO_ 795 "fe00000000000000";
BA_ "PduName" BO_ 795 "ICBVC_100ms_PDU48";
BA_ "VFrameFormat" BO_ 795 14;
BA_ "FrameTriggeringName" BO_ 907 "ICBVC_RZCUCANFD_100ms_FrP80";
BA_ "GenMsgCycleTime" BO_ 907 100;
BA_ "GenMsgSendType" BO_ 907 0;
BA_ "GenMsgStartValue" BO_ 907 "00300000008ffffc";
BA_ "PduName" BO_ 907 "ICBVC_100ms_PDU80";
BA_ "VFrameFormat" BO_ 907 14;
BA_ "FrameTriggeringName" BO_ 1345 "ICBVC_RZCUCANFD_200ms_FrP50";
BA_ "GenMsgCycleTime" BO_ 1345 200;
BA_ "GenMsgSendType" BO_ 1345 0;
BA_ "GenMsgStartValue" BO_ 1345 "1300000000000000";
BA_ "PduName" BO_ 1345 "ICBVC_200ms_PDU50";
BA_ "VFrameFormat" BO_ 1345 14;
BA_ "FrameTriggeringName" BO_ 1151 "ICBVC_RZCUCANFD_200ms_FrP79";
BA_ "GenMsgCycleTime" BO_ 1151 200;
BA_ "GenMsgSendType" BO_ 1151 0;
BA_ "GenMsgStartValue" BO_ 1151 "0020ffff00000000";
BA_ "PduName" BO_ 1151 "ICBVC_200ms_PDU79";
BA_ "VFrameFormat" BO_ 1151 14;
BA_ "FrameTriggeringName" BO_ 361 "ICBVC_RZCUCANFD_20ms_FrP00";
BA_ "GenMsgCycleTime" BO_ 361 20;
BA_ "GenMsgSendType" BO_ 361 0;
BA_ "GenMsgStartValue" BO_ 361 "0000000000000000";
BA_ "PduName" BO_ 361 "ICBVC_20ms_PDU00";
BA_ "VFrameFormat" BO_ 361 14;
BA_ "FrameTriggeringName" BO_ 497 "ICBVC_RZCUCANFD_20ms_FrP03";
BA_ "GenMsgCycleTime" BO_ 497 20;
BA_ "GenMsgSendType" BO_ 497 0;
BA_ "GenMsgStartValue" BO_ 497 "0000ff0f1200001f";
BA_ "PduName" BO_ 497 "ICBVC_20ms_PDU03";
BA_ "VFrameFormat" BO_ 497 14;
BA_ "FrameTriggeringName" BO_ 60 "ICBVC_SecOC_ComKeyReq";
BA_ "GenMsgSendType" BO_ 60 1;
BA_ "GenMsgStartValue" BO_ 60 "0000000000000000";
BA_ "PduName" BO_ 60 "ICBVC_SecOCComKeyReq_PDU01";
BA_ "VFrameFormat" BO_ 60 14;
BA_ "FrameTriggeringName" BO_ 1391 "ICBVC_SecOC_SyncMsg";
BA_ "GenMsgDelayTime" BO_ 1391 5;
BA_ "GenMsgSendType" BO_ 1391 1;
BA_ "GenMsgStartValue" BO_ 1391 "0000010001000000";
BA_ "PduName" BO_ 1391 "ICBVC_SecOC_SyncMsg";
BA_ "SystemMessageLongSymbol" BO_ 1391 "synthesized_ICBVC_SecOC_SyncMsg_BKPCANFD";
BA_ "VFrameFormat" BO_ 1391 14;
BA_ "FrameTriggeringName" BO_ 815 "ICB_BKBCANFD_100ms_FrP146";
BA_ "GenMsgCycleTime" BO_ 815 100;
BA_ "GenMsgSendType" BO_ 815 0;
BA_ "GenMsgStartValue" BO_ 815 "0000000000000000";
BA_ "PduName" BO_ 815 "ICB_100ms_PDU146";
BA_ "VFrameFormat" BO_ 815 14;
BA_ "FrameTriggeringName" BO_ 913 "ICB_BKBCANFD_100ms_FrP147";
BA_ "GenMsgCycleTime" BO_ 913 100;
BA_ "GenMsgSendType" BO_ 913 0;
BA_ "GenMsgStartValue" BO_ 913 "0000000000000000";
BA_ "PduName" BO_ 913 "ICB_100ms_PDU147";
BA_ "VFrameFormat" BO_ 913 14;
BA_ "FrameTriggeringName" BO_ 902 "ICB_BKBCANFD_100ms_FrP221";
BA_ "GenMsgCycleTime" BO_ 902 100;
BA_ "GenMsgSendType" BO_ 902 0;
BA_ "GenMsgStartValue" BO_ 902 "000000000000000000000000000000000018000000000000";
BA_ "PduName" BO_ 902 "ICB_100ms_PDU221";
BA_ "VFrameFormat" BO_ 902 14;
BA_ "FrameTriggeringName" BO_ 955 "ICB_BKPCANFD_100ms_FrP159";
BA_ "GenMsgCycleTime" BO_ 955 100;
BA_ "GenMsgSendType" BO_ 955 0;
BA_ "GenMsgStartValue" BO_ 955 "00fff85000590000f0c0800000000000008898224c10000000008000000000000000000000000000000000000000000000000000000000000000000000000000";
BA_ "PduName" BO_ 955 "ICB_100ms_PDU159";
BA_ "VFrameFormat" BO_ 955 14;
BA_ "FrameTriggeringName" BO_ 746 "ICB_BKPCANFD_100ms_FrP82";
BA_ "GenMsgCycleTime" BO_ 746 100;
BA_ "GenMsgSendType" BO_ 746 0;
BA_ "GenMsgStartValue" BO_ 746 "0000000000000000";
BA_ "PduName" BO_ 746 "ICB_100ms_PDU82";
BA_ "VFrameFormat" BO_ 746 14;
BA_ "FrameTriggeringName" BO_ 1297 "ICB_BKPCANFD_500ms_FrP229";
BA_ "GenMsgCycleTime" BO_ 1297 500;
BA_ "GenMsgSendType" BO_ 1297 0;
BA_ "GenMsgStartValue" BO_ 1297 "0000000000000000000000000000000000000000";
BA_ "PduName" BO_ 1297 "ICB_500ms_PDU229";
BA_ "VFrameFormat" BO_ 1297 14;
BA_ "FrameTriggeringName" BO_ 368 "ICB_BKPCANFD_50ms_FrP158";
BA_ "GenMsgCycleTime" BO_ 368 50;
BA_ "GenMsgSendType" BO_ 368 0;
BA_ "GenMsgStartValue" BO_ 368 "00000f00ff1fffffffffffffffffffff";
BA_ "PduName" BO_ 368 "ICBVC_50ms_PDU158";
BA_ "VFrameFormat" BO_ 368 14;
BA_ "FrameTriggeringName" BO_ 1389 "ICB_CONNCANFD_Event_FrS67";
BA_ "GenMsgSendType" BO_ 1389 1;
BA_ "GenMsgStartValue" BO_ 1389 "00000000000000000000000000000000";
BA_ "PduName" BO_ 1389 "ICB_Sporadic_PDU67";
BA_ "VFrameFormat" BO_ 1389 14;
BA_ "FrameTriggeringName" BO_ 1111 "ICB_ZONE_BDCAN_100ms_FrP00";
BA_ "GenMsgCycleTime" BO_ 1111 100;
BA_ "GenMsgSendType" BO_ 1111 0;
BA_ "GenMsgStartValue" BO_ 1111 "ffffffffff100000000000000000000000000020000000000000000000000000";
BA_ "PduName" BO_ 1111 "ICB_ZONE_100ms_PDU00";
BA_ "VFrameFormat" BO_ 1111 14;
BA_ "FrameTriggeringName" BO_ 527 "IMM_BKPCANFD_50ms_FrP02";
BA_ "GenMsgCycleTime" BO_ 527 50;
BA_ "GenMsgSendType" BO_ 527 0;
BA_ "GenMsgStartValue" BO_ 527 "00f0000003000700fffc01000000000000ffffff0fffffff";
BA_ "PduName" BO_ 527 "IMM_50ms_PDU02";
BA_ "VFrameFormat" BO_ 527 14;
BA_ "FrameTriggeringName" BO_ 657 "IMM_BKPCANFD_50ms_FrP04";
BA_ "GenMsgCycleTime" BO_ 657 50;
BA_ "GenMsgSendType" BO_ 657 0;
BA_ "GenMsgStartValue" BO_ 657 "00000000000000000000000000000000000000000000000000000000000000000000000000000000000000000000000000000000000000000000000000000000";
BA_ "PduName" BO_ 657 "IMM_50ms_PDU04";
BA_ "VFrameFormat" BO_ 657 14;
BA_ "FrameTriggeringName" BO_ 1237 "IMM_BKPCANFD_NM";
BA_ "GenMsgSendType" BO_ 1237 1;
BA_ "GenMsgStartValue" BO_ 1237 "0000000000000000";
BA_ "PduName" BO_ 1237 "NmPDU_BKPCANFD_IMM";
BA_ "VFrameFormat" BO_ 1237 14;
BA_ "FrameTriggeringName" BO_ 1767 "IPD_BKBCANFD_EvtInfo";
BA_ "GenMsgSendType" BO_ 1767 1;
BA_ "GenMsgStartValue" BO_ 1767 "00000000000000000000000000000000000000000000000000000000000000000000000000000000000000000000000000000000000000000000000000000000";
BA_ "PduName" BO_ 1767 "IPD_BKBCANFD_EvtInfo";
BA_ "VFrameFormat" BO_ 1767 14;
BA_ "CompuMethodName" SG_ 591 DrvrFtgLvl "DrvrFtgLvl";
BA_ "ISignalName" SG_ 591 DrvrFtgLvl "IDrvrFtgLvl";
BA_ "SysSignalName" SG_ 591 DrvrFtgLvl "DrvrFtgLvl";
BA_ "CompuMethodName" SG_ 591 ICMEyeOnRoad "ICMEyeOnRoad";
BA_ "ISignalName" SG_ 591 ICMEyeOnRoad "IICMEyeOnRoad";
BA_ "SysSignalName" SG_ 591 ICMEyeOnRoad "ICMEyeOnRoad";
BA_ "CompuMethodName" SG_ 591 DrvrDstrctnSts "DrvrDstrctnSts";
BA_ "ISignalName" SG_ 591 DrvrDstrctnSts "IDrvrDstrctnSts";
BA_ "LongName" SG_ 591 DrvrDstrctnSts "Driver Distraction Status";
BA_ "SysSignalName" SG_ 591 DrvrDstrctnSts "DrvrDstrctnSts";
BA_ "CompuMethodName" SG_ 591 ICMDrvrDstcnSts "ICMDrvrDstcnSts";
BA_ "ISignalName" SG_ 591 ICMDrvrDstcnSts "IICMDrvrDstcnSts";
BA_ "SysSignalName" SG_ 591 ICMDrvrDstcnSts "ICMDrvrDstcnSts";
BA_ "CompuMethodName" SG_ 591 ICMDrvrPrst "ICMDrvrPrst";
BA_ "ISignalName" SG_ 591 ICMDrvrPrst "IICMDrvrPrst";
BA_ "SysSignalName" SG_ 591 ICMDrvrPrst "ICMDrvrPrst";
BA_ "CompuMethodName" SG_ 591 ICMDrvrFtgLvl "ICMDrvrFtgLvl";
BA_ "ISignalName" SG_ 591 ICMDrvrFtgLvl "IICMDrvrFtgLvl";
BA_ "SysSignalName" SG_ 591 ICMDrvrFtgLvl "ICMDrvrFtgLvl";
BA_ "CompuMethodName" SG_ 728 AIParkngReqICB "AIParkngReqICB";
BA_ "ISignalName" SG_ 728 AIParkngReqICB "IAIParkngReqICB";
BA_ "LongName" SG_ 728 AIParkngReqICB "AIParking Function Request";
BA_ "SysSignalName" SG_ 728 AIParkngReqICB "AIParkngReqICB";
BA_ "CompuMethodName" SG_ 790 FOTAStatusValid "FOTAStatusValid";
BA_ "GenSigStartValue" SG_ 790 FOTAStatusValid 1;
BA_ "ISignalName" SG_ 790 FOTAStatusValid "IFOTAStatusValid";
BA_ "LongName" SG_ 790 FOTAStatusValid "The Valid Of Firmware Over The Air Status";
BA_ "SysSignalName" SG_ 790 FOTAStatusValid "FOTAStatusValid";
BA_ "CompuMethodName" SG_ 790 FOTAStatus "FOTAStatus";
BA_ "ISignalName" SG_ 790 FOTAStatus "IFOTAStatus";
BA_ "LongName" SG_ 790 FOTAStatus "Firmware Over The Air Status";
BA_ "SysSignalName" SG_ 790 FOTAStatus "FOTAStatus";
BA_ "CompuMethodName" SG_ 790 FOTATarget "FOTATarget";
BA_ "ISignalName" SG_ 790 FOTATarget "IFOTATarget";
BA_ "LongName" SG_ 790 FOTATarget "Firmware Over The Air Target";
BA_ "SysSignalName" SG_ 790 FOTATarget "FOTATarget";
BA_ "CompuMethodName" SG_ 790 FOTATargetValid "FOTATargetValid";
BA_ "GenSigStartValue" SG_ 790 FOTATargetValid 1;
BA_ "ISignalName" SG_ 790 FOTATargetValid "IFOTATargetValid";
BA_ "LongName" SG_ 790 FOTATargetValid "The Target Valid Of Firmware Over The Air Status";
BA_ "SysSignalName" SG_ 790 FOTATargetValid "FOTATargetValid";
BA_ "CompuMethodName" SG_ 1008 OtsdAirTemCrValV "OtsdAirTemCrValV";
BA_ "GenSigStartValue" SG_ 1008 OtsdAirTemCrValV 1;
BA_ "ISignalName" SG_ 1008 OtsdAirTemCrValV "IOtsdAirTemCrValV";
BA_ "LongName" SG_ 1008 OtsdAirTemCrValV "Outside_Air_Temperature_Corrected_Value_Validity";
BA_ "SysSignalName" SG_ 1008 OtsdAirTemCrValV "OtsdAirTemCrValV";
BA_ "CompuMethodName" SG_ 1008 OtsdAirTemCrValMsk "OtsdAirTemCrValMsk";
BA_ "ISignalName" SG_ 1008 OtsdAirTemCrValMsk "IOtsdAirTemCrValMsk";
BA_ "LongName" SG_ 1008 OtsdAirTemCrValMsk "Outside_Air_Temperature_Corrected_Value_Mask";
BA_ "SysSignalName" SG_ 1008 OtsdAirTemCrValMsk "OtsdAirTemCrValMsk";
BA_ "CompuMethodName" SG_ 1008 OtsdAirTemVDA "OtsdAirTemVDA";
BA_ "ISignalName" SG_ 1008 OtsdAirTemVDA "IOtsdAirTemVDA";
BA_ "SysSignalName" SG_ 1008 OtsdAirTemVDA "OtsdAirTemVDA";
BA_ "CompuMethodName" SG_ 1008 OtsdAirTemCrVal "OtsdAirTemCrVal";
BA_ "ISignalName" SG_ 1008 OtsdAirTemCrVal "IOtsdAirTemCrVal";
BA_ "LongName" SG_ 1008 OtsdAirTemCrVal "Outside_Air_Temperature_Corrected_Value";
BA_ "SysSignalName" SG_ 1008 OtsdAirTemCrVal "OtsdAirTemCrVal";
BA_ "CompuMethodName" SG_ 922 AVMDspReq "AVMDspReq";
BA_ "ISignalName" SG_ 922 AVMDspReq "IAVMDspReq";
BA_ "LongName" SG_ 922 AVMDspReq "Around_View_Monitor_Display_Request";
BA_ "SysSignalName" SG_ 922 AVMDspReq "AVMDspReq";
BA_ "CompuMethodName" SG_ 922 HDCReq "HDCReq";
BA_ "ISignalName" SG_ 922 HDCReq "IHDCReq";
BA_ "LongName" SG_ 922 HDCReq "Hill Descent Control Request";
BA_ "SysSignalName" SG_ 922 HDCReq "HDCReq";
BA_ "CompuMethodName" SG_ 922 EmmsnTestMdFICMV "EmmsnTestMdFICMV";
BA_ "GenSigStartValue" SG_ 922 EmmsnTestMdFICMV 1;
BA_ "ISignalName" SG_ 922 EmmsnTestMdFICMV "IEmmsnTestMdFICMV";
BA_ "LongName" SG_ 922 EmmsnTestMdFICMV "Emission Test Mode Front Infotainment Control Module Valid";
BA_ "SysSignalName" SG_ 922 EmmsnTestMdFICMV "EmmsnTestMdFICMV";
BA_ "CompuMethodName" SG_ 922 TrgtSOCReqFICM "TrgtSOCReqFICM";
BA_ "ISignalName" SG_ 922 TrgtSOCReqFICM "ITrgtSOCReqFICM";
BA_ "LongName" SG_ 922 TrgtSOCReqFICM "Target Soc Request";
BA_ "SysSignalName" SG_ 922 TrgtSOCReqFICM "TrgtSOCReqFICM";
BA_ "CompuMethodName" SG_ 922 FICMPwrDMdReq "FICMPwrDMdReq";
BA_ "ISignalName" SG_ 922 FICMPwrDMdReq "IFICMPwrDMdReq";
BA_ "LongName" SG_ 922 FICMPwrDMdReq "Front Infotainment Control Module Power Distribution Mode Request";
BA_ "SysSignalName" SG_ 922 FICMPwrDMdReq "FICMPwrDMdReq";
BA_ "CompuMethodName" SG_ 922 FICMPwrDMdReqV "FICMPwrDMdReqV";
BA_ "GenSigStartValue" SG_ 922 FICMPwrDMdReqV 1;
BA_ "ISignalName" SG_ 922 FICMPwrDMdReqV "IFICMPwrDMdReqV";
BA_ "LongName" SG_ 922 FICMPwrDMdReqV "Front Infotainment Control Module Power Distribution Mode Request Validity";
BA_ "SysSignalName" SG_ 922 FICMPwrDMdReqV "FICMPwrDMdReqV";
BA_ "CompuMethodName" SG_ 922 EmmsnTestMdFICM "EmmsnTestMdFICM";
BA_ "ISignalName" SG_ 922 EmmsnTestMdFICM "IEmmsnTestMdFICM";
BA_ "LongName" SG_ 922 EmmsnTestMdFICM "Emission Test Mode Front Infotainment Control Module";
BA_ "SysSignalName" SG_ 922 EmmsnTestMdFICM "EmmsnTestMdFICM";
BA_ "CompuMethodName" SG_ 922 FICMPwrDMdReqV_AIHEV "FICMPwrDMdReqV_AIHEV";
BA_ "GenSigStartValue" SG_ 922 FICMPwrDMdReqV_AIHEV 1;
BA_ "ISignalName" SG_ 922 FICMPwrDMdReqV_AIHEV "IFICMPwrDMdReqV_AIHEV";
BA_ "LongName" SG_ 922 FICMPwrDMdReqV_AIHEV "Front Infotainment Control Module Power Distribution Mode Request Validity";
BA_ "SysSignalName" SG_ 922 FICMPwrDMdReqV_AIHEV "FICMPwrDMdReqV_AIHEV";
BA_ "CompuMethodName" SG_ 922 SusDmpngCtrlCustSetngReq "SusDmpngCtrlCustSetngReq";
BA_ "ISignalName" SG_ 922 SusDmpngCtrlCustSetngReq "ISusDmpngCtrlCustSetngReq";
BA_ "LongName" SG_ 922 SusDmpngCtrlCustSetngReq "Suspension Damping Control Customization Setting Request";
BA_ "SysSignalName" SG_ 922 SusDmpngCtrlCustSetngReq "SusDmpngCtrlCustSetngReq";
BA_ "CompuMethodName" SG_ 922 TrgtSOCReqFICMV "TrgtSOCReqFICMV";
BA_ "ISignalName" SG_ 922 TrgtSOCReqFICMV "ITrgtSOCReqFICMV";
BA_ "LongName" SG_ 922 TrgtSOCReqFICMV "Target Soc Request Valid";
BA_ "SysSignalName" SG_ 922 TrgtSOCReqFICMV "TrgtSOCReqFICMV";
BA_ "CompuMethodName" SG_ 922 FICMPwrDMdReq_AIHEV "FICMPwrDMdReq_AIHEV";
BA_ "ISignalName" SG_ 922 FICMPwrDMdReq_AIHEV "IFICMPwrDMdReq_AIHEV";
BA_ "LongName" SG_ 922 FICMPwrDMdReq_AIHEV "Front Infotainment Control Module Power Distribution Mode Request";
BA_ "SysSignalName" SG_ 922 FICMPwrDMdReq_AIHEV "FICMPwrDMdReq_AIHEV";
BA_ "CompuMethodName" SG_ 795 DCDCVolStpt "DCDCVolStpt";
BA_ "GenSigStartValue" SG_ 795 DCDCVolStpt 254;
BA_ "ISignalName" SG_ 795 DCDCVolStpt "IDCDCVolStpt";
BA_ "LongName" SG_ 795 DCDCVolStpt "Direct_Current_Direct_Current_Voltage_Setpoint";
BA_ "SysSignalName" SG_ 795 DCDCVolStpt "DCDCVolStpt";
BA_ "CompuMethodName" SG_ 795 SLIFUpdtIndReq "SLIFUpdtIndReq";
BA_ "ISignalName" SG_ 795 SLIFUpdtIndReq "ISLIFUpdtIndReq";
BA_ "LongName" SG_ 795 SLIFUpdtIndReq "Speed Limit Information Function Update Indication Request";
BA_ "SysSignalName" SG_ 795 SLIFUpdtIndReq "SLIFUpdtIndReq";
BA_ "CompuMethodName" SG_ 795 BatVol "BatVol";
BA_ "ISignalName" SG_ 795 BatVol "IBatVol";
BA_ "LongName" SG_ 795 BatVol "Battery Voltage";
BA_ "SysSignalName" SG_ 795 BatVol "BatVol";
BA_ "CompuMethodName" SG_ 795 SprSportSubItemReqV "SprSportSubItemReqV";
BA_ "ISignalName" SG_ 795 SprSportSubItemReqV "ISprSportSubItemReqV";
BA_ "SysSignalName" SG_ 795 SprSportSubItemReqV "SprSportSubItemReqV";
BA_ "CompuMethodName" SG_ 795 SprSportSubItemReq "SprSportSubItemReq";
BA_ "ISignalName" SG_ 795 SprSportSubItemReq "ISprSportSubItemReq";
BA_ "SysSignalName" SG_ 795 SprSportSubItemReq "SprSportSubItemReq";
BA_ "CompuMethodName" SG_ 907 ICBVC_100ms_Group80_CRC "ICBVC_100ms_Group80_CRC";
BA_ "ISignalName" SG_ 907 ICBVC_100ms_Group80_CRC "IICBVC_100ms_Group80_CRC";
BA_ "LongName" SG_ 907 ICBVC_100ms_Group80_CRC "ICBVC_100ms_Group80_CRC";
BA_ "SysSignalName" SG_ 907 ICBVC_100ms_Group80_CRC "ICBVC_100ms_Group80_CRC";
BA_ "CompuMethodName" SG_ 907 ICBVC_100ms_Group80_RC "ICBVC_100ms_Group80_RC";
BA_ "ISignalName" SG_ 907 ICBVC_100ms_Group80_RC "IICBVC_100ms_Group80_RC";
BA_ "LongName" SG_ 907 ICBVC_100ms_Group80_RC "ICBVC_100ms_Group80_RC";
BA_ "SysSignalName" SG_ 907 ICBVC_100ms_Group80_RC "ICBVC_100ms_Group80_RC";
BA_ "CompuMethodName" SG_ 907 VehDrvngMd "VehDrvngMd";
BA_ "GenSigStartValue" SG_ 907 VehDrvngMd 3;
BA_ "ISignalName" SG_ 907 VehDrvngMd "IVehDrvngMd";
BA_ "SysSignalName" SG_ 907 VehDrvngMd "VehDrvngMd";
BA_ "CompuMethodName" SG_ 907 VehOdo "VehOdo";
BA_ "ISignalName" SG_ 907 VehOdo "IVehOdo";
BA_ "LongName" SG_ 907 VehOdo "Vehicle_Odometer";
BA_ "SysSignalName" SG_ 907 VehOdo "VehOdo";
BA_ "CompuMethodName" SG_ 907 ICBVC_100ms_Group80_Reserved1 "ICBVC_100ms_Group80_Reserved1";
BA_ "GenSigStartValue" SG_ 907 ICBVC_100ms_Group80_Reserved1 15;
BA_ "ISignalName" SG_ 907 ICBVC_100ms_Group80_Reserved1 "IICBVC_100ms_Group80_Reserved1";
BA_ "SysSignalName" SG_ 907 ICBVC_100ms_Group80_Reserved1 "ICBVC_100ms_Group80_Reserved1";
BA_ "CompuMethodName" SG_ 907 VehLdShedLvl "VehLdShedLvl";
BA_ "ISignalName" SG_ 907 VehLdShedLvl "IVehLdShedLvl";
BA_ "LongName" SG_ 907 VehLdShedLvl "Vehicle_Load_Shed_Level";
BA_ "SysSignalName" SG_ 907 VehLdShedLvl "VehLdShedLvl";
BA_ "CompuMethodName" SG_ 907 VehOdoV "VehOdoV";
BA_ "GenSigStartValue" SG_ 907 VehOdoV 1;
BA_ "ISignalName" SG_ 907 VehOdoV "IVehOdoV";
BA_ "LongName" SG_ 907 VehOdoV "Vehicle_Odometer_Validity";
BA_ "SysSignalName" SG_ 907 VehOdoV "VehOdoV";
BA_ "CompuMethodName" SG_ 907 ICBVC_100ms_Group80_Reserved2 "ICBVC_100ms_Group80_Reserved2";
BA_ "GenSigStartValue" SG_ 907 ICBVC_100ms_Group80_Reserved2 255;
BA_ "ISignalName" SG_ 907 ICBVC_100ms_Group80_Reserved2 "IICBVC_100ms_Group80_Reserved2";
BA_ "SysSignalName" SG_ 907 ICBVC_100ms_Group80_Reserved2 "ICBVC_100ms_Group80_Reserved2";
BA_ "CompuMethodName" SG_ 907 FrtPsngAirbagSwStsReqV_Sfty "FrtPsngAirbagSwStsReqV_Sfty";
BA_ "ISignalName" SG_ 907 FrtPsngAirbagSwStsReqV_Sfty "IFrtPsngAirbagSwStsReqV_Sfty";
BA_ "LongName" SG_ 907 FrtPsngAirbagSwStsReqV_Sfty "Front Passenger Airbag Switch Status Request Validity";
BA_ "SysSignalName" SG_ 907 FrtPsngAirbagSwStsReqV_Sfty "FrtPsngAirbagSwStsReqV_Sfty";
BA_ "CompuMethodName" SG_ 907 FrtPsngAirbagSwStsReq_Sfty "FrtPsngAirbagSwStsReq_Sfty";
BA_ "ISignalName" SG_ 907 FrtPsngAirbagSwStsReq_Sfty "IFrtPsngAirbagSwStsReq_Sfty";
BA_ "LongName" SG_ 907 FrtPsngAirbagSwStsReq_Sfty "Front Passenger Airbag Switch Status Request";
BA_ "SysSignalName" SG_ 907 FrtPsngAirbagSwStsReq_Sfty "FrtPsngAirbagSwStsReq_Sfty";
BA_ "CompuMethodName" SG_ 907 ICBVC_100ms_Group80_Reserved3 "ICBVC_100ms_Group80_Reserved3";
BA_ "GenSigStartValue" SG_ 907 ICBVC_100ms_Group80_Reserved3 63;
BA_ "ISignalName" SG_ 907 ICBVC_100ms_Group80_Reserved3 "IICBVC_100ms_Group80_Reserved3";
BA_ "SysSignalName" SG_ 907 ICBVC_100ms_Group80_Reserved3 "ICBVC_100ms_Group80_Reserved3";
BA_ "CompuMethodName" SG_ 1345 VehTiPblshYear "VehTiPblshYear";
BA_ "GenSigStartValue" SG_ 1345 VehTiPblshYear 19;
BA_ "ISignalName" SG_ 1345 VehTiPblshYear "IVehTiPblshYear";
BA_ "LongName" SG_ 1345 VehTiPblshYear "Vehicle Time Publish Year";
BA_ "SysSignalName" SG_ 1345 VehTiPblshYear "VehTiPblshYear";
BA_ "CompuMethodName" SG_ 1345 VehTiPblshMth "VehTiPblshMth";
BA_ "ISignalName" SG_ 1345 VehTiPblshMth "IVehTiPblshMth";
BA_ "LongName" SG_ 1345 VehTiPblshMth "Vehicle Time Publish Month";
BA_ "SysSignalName" SG_ 1345 VehTiPblshMth "VehTiPblshMth";
BA_ "CompuMethodName" SG_ 1345 VehTiPblshDay "VehTiPblshDay";
BA_ "ISignalName" SG_ 1345 VehTiPblshDay "IVehTiPblshDay";
BA_ "LongName" SG_ 1345 VehTiPblshDay "Vehicle Time Publish Day";
BA_ "SysSignalName" SG_ 1345 VehTiPblshDay "VehTiPblshDay";
BA_ "CompuMethodName" SG_ 1345 VehTiPblshHr "VehTiPblshHr";
BA_ "ISignalName" SG_ 1345 VehTiPblshHr "IVehTiPblshHr";
BA_ "LongName" SG_ 1345 VehTiPblshHr "Vehicle Time Publish Hour";
BA_ "SysSignalName" SG_ 1345 VehTiPblshHr "VehTiPblshHr";
BA_ "CompuMethodName" SG_ 1345 VehTiPblshMins "VehTiPblshMins";
BA_ "ISignalName" SG_ 1345 VehTiPblshMins "IVehTiPblshMins";
BA_ "LongName" SG_ 1345 VehTiPblshMins "Vehicle Time Publish Minute";
BA_ "SysSignalName" SG_ 1345 VehTiPblshMins "VehTiPblshMins";
BA_ "CompuMethodName" SG_ 1345 VehTiPblshSec "VehTiPblshSec";
BA_ "ISignalName" SG_ 1345 VehTiPblshSec "IVehTiPblshSec";
BA_ "LongName" SG_ 1345 VehTiPblshSec "Vehicle Time Publish Second";
BA_ "SysSignalName" SG_ 1345 VehTiPblshSec "VehTiPblshSec";
BA_ "CompuMethodName" SG_ 1345 TimeDspFmt "TimeDspFmt";
BA_ "ISignalName" SG_ 1345 TimeDspFmt "ITimeDspFmt";
BA_ "SysSignalName" SG_ 1345 TimeDspFmt "TimeDspFmt";
BA_ "CompuMethodName" SG_ 1151 ICBVC_200ms_Group79_CRC "ICBVC_200ms_Group79_CRC";
BA_ "ISignalName" SG_ 1151 ICBVC_200ms_Group79_CRC "IICBVC_200ms_Group79_CRC";
BA_ "LongName" SG_ 1151 ICBVC_200ms_Group79_CRC "ICBVC_200ms_Group79_CRC";
BA_ "SysSignalName" SG_ 1151 ICBVC_200ms_Group79_CRC "ICBVC_200ms_Group79_CRC";
BA_ "CompuMethodName" SG_ 1151 ICBVC_200ms_Group79_RC "ICBVC_200ms_Group79_RC";
BA_ "ISignalName" SG_ 1151 ICBVC_200ms_Group79_RC "IICBVC_200ms_Group79_RC";
BA_ "LongName" SG_ 1151 ICBVC_200ms_Group79_RC "ICBVC_200ms_Group79_RC";
BA_ "SysSignalName" SG_ 1151 ICBVC_200ms_Group79_RC "ICBVC_200ms_Group79_RC";
BA_ "CompuMethodName" SG_ 1151 TrlrMdSts "TrlrMdSts";
BA_ "ISignalName" SG_ 1151 TrlrMdSts "ITrlrMdSts";
BA_ "SysSignalName" SG_ 1151 TrlrMdSts "TrlrMdSts";
BA_ "CompuMethodName" SG_ 1151 OdoPriyPrcsV "OdoPriyPrcsV";
BA_ "GenSigStartValue" SG_ 1151 OdoPriyPrcsV 1;
BA_ "ISignalName" SG_ 1151 OdoPriyPrcsV "IOdoPriyPrcsV";
BA_ "LongName" SG_ 1151 OdoPriyPrcsV "Odometer Primary Precision Validity";
BA_ "SysSignalName" SG_ 1151 OdoPriyPrcsV "OdoPriyPrcsV";
BA_ "CompuMethodName" SG_ 1151 EPTNotReadyReq "EPTNotReadyReq";
BA_ "ISignalName" SG_ 1151 EPTNotReadyReq "IEPTNotReadyReq";
BA_ "LongName" SG_ 1151 EPTNotReadyReq "Electric Powertrain Not Ready Request";
BA_ "SysSignalName" SG_ 1151 EPTNotReadyReq "EPTNotReadyReq";
BA_ "CompuMethodName" SG_ 1151 ClstrDspdAirbagWrnng "ClstrDspdAirbagWrnng";
BA_ "ISignalName" SG_ 1151 ClstrDspdAirbagWrnng "IClstrDspdAirbagWrnng";
BA_ "LongName" SG_ 1151 ClstrDspdAirbagWrnng "Cluster Displayed Airbag Warning";
BA_ "SysSignalName" SG_ 1151 ClstrDspdAirbagWrnng "ClstrDspdAirbagWrnng";
BA_ "CompuMethodName" SG_ 1151 ICBVC_200ms_Group79_Reserved1 "ICBVC_200ms_Group79_Reserved1";
BA_ "GenSigStartValue" SG_ 1151 ICBVC_200ms_Group79_Reserved1 255;
BA_ "ISignalName" SG_ 1151 ICBVC_200ms_Group79_Reserved1 "IICBVC_200ms_Group79_Reserved1";
BA_ "SysSignalName" SG_ 1151 ICBVC_200ms_Group79_Reserved1 "ICBVC_200ms_Group79_Reserved1";
BA_ "CompuMethodName" SG_ 1151 ICBVC_200ms_Group79_Reserved2 "ICBVC_200ms_Group79_Reserved2";
BA_ "GenSigStartValue" SG_ 1151 ICBVC_200ms_Group79_Reserved2 255;
BA_ "ISignalName" SG_ 1151 ICBVC_200ms_Group79_Reserved2 "IICBVC_200ms_Group79_Reserved2";
BA_ "SysSignalName" SG_ 1151 ICBVC_200ms_Group79_Reserved2 "ICBVC_200ms_Group79_Reserved2";
BA_ "CompuMethodName" SG_ 1151 OdoPriyPrcs "OdoPriyPrcs";
BA_ "ISignalName" SG_ 1151 OdoPriyPrcs "IOdoPriyPrcs";
BA_ "LongName" SG_ 1151 OdoPriyPrcs "Odometer Primary Precision";
BA_ "SysSignalName" SG_ 1151 OdoPriyPrcs "OdoPriyPrcs";
BA_ "CompuMethodName" SG_ 361 NFCAMAvlbly "NFCAMAvlbly";
BA_ "ISignalName" SG_ 361 NFCAMAvlbly "INFCAMAvlbly";
BA_ "LongName" SG_ 361 NFCAMAvlbly "NFCAM LHBDCANFD Availability";
BA_ "SysSignalName" SG_ 361 NFCAMAvlbly "NFCAMAvlbly";
BA_ "CompuMethodName" SG_ 361 SASAvlbly "SASAvlbly";
BA_ "ISignalName" SG_ 361 SASAvlbly "ISASAvlbly";
BA_ "SysSignalName" SG_ 361 SASAvlbly "SASAvlbly";
BA_ "CompuMethodName" SG_ 361 SDMAvlbly "SDMAvlbly";
BA_ "ISignalName" SG_ 361 SDMAvlbly "ISDMAvlbly";
BA_ "LongName" SG_ 361 SDMAvlbly "SDM CHCANFD Availability";
BA_ "SysSignalName" SG_ 361 SDMAvlbly "SDMAvlbly";
BA_ "CompuMethodName" SG_ 361 RHZCUAvlbly "RHZCUAvlbly";
BA_ "ISignalName" SG_ 361 RHZCUAvlbly "IRHZCUAvlbly";
BA_ "LongName" SG_ 361 RHZCUAvlbly "RHZCU BKBCANFD Availability";
BA_ "SysSignalName" SG_ 361 RHZCUAvlbly "RHZCUAvlbly";
BA_ "CompuMethodName" SG_ 361 LHZCUAvlbly "LHZCUAvlbly";
BA_ "ISignalName" SG_ 361 LHZCUAvlbly "ILHZCUAvlbly";
BA_ "LongName" SG_ 361 LHZCUAvlbly "LHZCU BKBCANFD Availability";
BA_ "SysSignalName" SG_ 361 LHZCUAvlbly "LHZCUAvlbly";
BA_ "CompuMethodName" SG_ 361 TC_ExtdAvlbly "TC_ExtdAvlbly";
BA_ "ISignalName" SG_ 361 TC_ExtdAvlbly "ITC_ExtdAvlbly";
BA_ "LongName" SG_ 361 TC_ExtdAvlbly "TC PTEXTDCAN Availability";
BA_ "SysSignalName" SG_ 361 TC_ExtdAvlbly "TC_ExtdAvlbly";
BA_ "CompuMethodName" SG_ 361 IBS_SFAvlbly "IBS_SFAvlbly";
BA_ "ISignalName" SG_ 361 IBS_SFAvlbly "IIBS_SFAvlbly";
BA_ "LongName" SG_ 361 IBS_SFAvlbly "IBS SFCANFD Availability";
BA_ "SysSignalName" SG_ 361 IBS_SFAvlbly "IBS_SFAvlbly";
BA_ "CompuMethodName" SG_ 361 EPSAvlbly "EPSAvlbly";
BA_ "ISignalName" SG_ 361 EPSAvlbly "IEPSAvlbly";
BA_ "LongName" SG_ 361 EPSAvlbly "EPS Availability";
BA_ "SysSignalName" SG_ 361 EPSAvlbly "EPSAvlbly";
BA_ "CompuMethodName" SG_ 361 TC_PTAvlbly "TC_PTAvlbly";
BA_ "ISignalName" SG_ 361 TC_PTAvlbly "ITC_PTAvlbly";
BA_ "LongName" SG_ 361 TC_PTAvlbly "TC PTCANFD Availability";
BA_ "SysSignalName" SG_ 361 TC_PTAvlbly "TC_PTAvlbly";
BA_ "CompuMethodName" SG_ 361 PICU_PTAvlbly "PICU_PTAvlbly";
BA_ "ISignalName" SG_ 361 PICU_PTAvlbly "IPICU_PTAvlbly";
BA_ "LongName" SG_ 361 PICU_PTAvlbly "PICU PTCANFD Availability";
BA_ "SysSignalName" SG_ 361 PICU_PTAvlbly "PICU_PTAvlbly";
BA_ "CompuMethodName" SG_ 361 LVBM_PTAvlbly "LVBM_PTAvlbly";
BA_ "ISignalName" SG_ 361 LVBM_PTAvlbly "ILVBM_PTAvlbly";
BA_ "LongName" SG_ 361 LVBM_PTAvlbly "LVBM PTCANFD Availability";
BA_ "SysSignalName" SG_ 361 LVBM_PTAvlbly "LVBM_PTAvlbly";
BA_ "CompuMethodName" SG_ 361 PEU_PTAvlbly "PEU_PTAvlbly";
BA_ "ISignalName" SG_ 361 PEU_PTAvlbly "IPEU_PTAvlbly";
BA_ "LongName" SG_ 361 PEU_PTAvlbly "PEU PTCANFD Availability";
BA_ "SysSignalName" SG_ 361 PEU_PTAvlbly "PEU_PTAvlbly";
BA_ "CompuMethodName" SG_ 361 PEU_ERAvlbly "PEU_ERAvlbly";
BA_ "ISignalName" SG_ 361 PEU_ERAvlbly "IPEU_ERAvlbly";
BA_ "LongName" SG_ 361 PEU_ERAvlbly "PEU ERCANFD Availability";
BA_ "SysSignalName" SG_ 361 PEU_ERAvlbly "PEU_ERAvlbly";
BA_ "CompuMethodName" SG_ 361 PICU_ExtdAvlbly "PICU_ExtdAvlbly";
BA_ "ISignalName" SG_ 361 PICU_ExtdAvlbly "IPICU_ExtdAvlbly";
BA_ "LongName" SG_ 361 PICU_ExtdAvlbly "PICU PTCANFD Availability";
BA_ "SysSignalName" SG_ 361 PICU_ExtdAvlbly "PICU_ExtdAvlbly";
BA_ "CompuMethodName" SG_ 361 LHRDAAvlbly "LHRDAAvlbly";
BA_ "ISignalName" SG_ 361 LHRDAAvlbly "ILHRDAAvlbly";
BA_ "LongName" SG_ 361 LHRDAAvlbly "LHRDA BKPCANFD Avlbly";
BA_ "SysSignalName" SG_ 361 LHRDAAvlbly "LHRDAAvlbly";
BA_ "CompuMethodName" SG_ 361 IPD_PTAvlbly "IPD_PTAvlbly";
BA_ "ISignalName" SG_ 361 IPD_PTAvlbly "IIPD_PTAvlbly";
BA_ "LongName" SG_ 361 IPD_PTAvlbly "IPD PTCANFD Availability";
BA_ "SysSignalName" SG_ 361 IPD_PTAvlbly "IPD_PTAvlbly";
BA_ "CompuMethodName" SG_ 361 RHMPWCAvlbly "RHMPWCAvlbly";
BA_ "ISignalName" SG_ 361 RHMPWCAvlbly "IRHMPWCAvlbly";
BA_ "LongName" SG_ 361 RHMPWCAvlbly "RHMPWC Availability";
BA_ "SysSignalName" SG_ 361 RHMPWCAvlbly "RHMPWCAvlbly";
BA_ "CompuMethodName" SG_ 361 ESS_PTAvlbly "ESS_PTAvlbly";
BA_ "ISignalName" SG_ 361 ESS_PTAvlbly "IESS_PTAvlbly";
BA_ "LongName" SG_ 361 ESS_PTAvlbly "ESS Availability";
BA_ "SysSignalName" SG_ 361 ESS_PTAvlbly "ESS_PTAvlbly";
BA_ "CompuMethodName" SG_ 361 CCU_ExtdAvlbly "CCU_ExtdAvlbly";
BA_ "ISignalName" SG_ 361 CCU_ExtdAvlbly "ICCU_ExtdAvlbly";
BA_ "LongName" SG_ 361 CCU_ExtdAvlbly "CCU Availability";
BA_ "SysSignalName" SG_ 361 CCU_ExtdAvlbly "CCU_ExtdAvlbly";
BA_ "CompuMethodName" SG_ 361 ESS_ExtdAvlbly "ESS_ExtdAvlbly";
BA_ "ISignalName" SG_ 361 ESS_ExtdAvlbly "IESS_ExtdAvlbly";
BA_ "LongName" SG_ 361 ESS_ExtdAvlbly "ESS Availability";
BA_ "SysSignalName" SG_ 361 ESS_ExtdAvlbly "ESS_ExtdAvlbly";
BA_ "CompuMethodName" SG_ 361 CCU_PTAvlbly "CCU_PTAvlbly";
BA_ "ISignalName" SG_ 361 CCU_PTAvlbly "ICCU_PTAvlbly";
BA_ "LongName" SG_ 361 CCU_PTAvlbly "CCU Availability";
BA_ "SysSignalName" SG_ 361 CCU_PTAvlbly "CCU_PTAvlbly";
BA_ "CompuMethodName" SG_ 361 IAMAvlbly "IAMAvlbly";
BA_ "ISignalName" SG_ 361 IAMAvlbly "IIAMAvlbly";
BA_ "LongName" SG_ 361 IAMAvlbly "IAM CONNCANFD Availability";
BA_ "SysSignalName" SG_ 361 IAMAvlbly "IAMAvlbly";
BA_ "CompuMethodName" SG_ 361 EAC_Avlbly "EAC_Avlbly";
BA_ "ISignalName" SG_ 361 EAC_Avlbly "IEAC_Avlbly";
BA_ "LongName" SG_ 361 EAC_Avlbly "EAC RHBDCAN Availability";
BA_ "SysSignalName" SG_ 361 EAC_Avlbly "EAC_Avlbly";
BA_ "CompuMethodName" SG_ 361 PEU_SFAvlbly "PEU_SFAvlbly";
BA_ "ISignalName" SG_ 361 PEU_SFAvlbly "IPEU_SFAvlbly";
BA_ "LongName" SG_ 361 PEU_SFAvlbly "PEU SFCANFD Availability";
BA_ "SysSignalName" SG_ 361 PEU_SFAvlbly "PEU_SFAvlbly";
BA_ "CompuMethodName" SG_ 361 PEU_ExtdAvlbly "PEU_ExtdAvlbly";
BA_ "ISignalName" SG_ 361 PEU_ExtdAvlbly "IPEU_ExtdAvlbly";
BA_ "LongName" SG_ 361 PEU_ExtdAvlbly "PEU Availability";
BA_ "SysSignalName" SG_ 361 PEU_ExtdAvlbly "PEU_ExtdAvlbly";
BA_ "CompuMethodName" SG_ 361 TDMAvlbly "TDMAvlbly";
BA_ "ISignalName" SG_ 361 TDMAvlbly "ITDMAvlbly";
BA_ "LongName" SG_ 361 TDMAvlbly "TDM Availability";
BA_ "SysSignalName" SG_ 361 TDMAvlbly "TDMAvlbly";
BA_ "CompuMethodName" SG_ 361 IPD_SFAvlbly "IPD_SFAvlbly";
BA_ "ISignalName" SG_ 361 IPD_SFAvlbly "IIPD_SFAvlbly";
BA_ "LongName" SG_ 361 IPD_SFAvlbly "IPD SFCANFD Availability";
BA_ "SysSignalName" SG_ 361 IPD_SFAvlbly "IPD_SFAvlbly";
BA_ "CompuMethodName" SG_ 361 SAC_ExtdAvlbly "SAC_ExtdAvlbly";
BA_ "ISignalName" SG_ 361 SAC_ExtdAvlbly "ISAC_ExtdAvlbly";
BA_ "LongName" SG_ 361 SAC_ExtdAvlbly "SAC Availability";
BA_ "SysSignalName" SG_ 361 SAC_ExtdAvlbly "SAC_ExtdAvlbly";
BA_ "CompuMethodName" SG_ 361 SAC_PTAvlbly "SAC_PTAvlbly";
BA_ "ISignalName" SG_ 361 SAC_PTAvlbly "ISAC_PTAvlbly";
BA_ "LongName" SG_ 361 SAC_PTAvlbly "SAC Availability";
BA_ "SysSignalName" SG_ 361 SAC_PTAvlbly "SAC_PTAvlbly";
BA_ "CompuMethodName" SG_ 361 CCEOPAvlbly "CCEOPAvlbly";
BA_ "ISignalName" SG_ 361 CCEOPAvlbly "ICCEOPAvlbly";
BA_ "LongName" SG_ 361 CCEOPAvlbly "CCU Availability";
BA_ "SysSignalName" SG_ 361 CCEOPAvlbly "CCEOPAvlbly";
BA_ "CompuMethodName" SG_ 361 RZCU_BKBCANFDAvlbly "RZCU_BKBCANFDAvlbly";
BA_ "ISignalName" SG_ 361 RZCU_BKBCANFDAvlbly "IRZCU_BKBCANFDAvlbly";
BA_ "LongName" SG_ 361 RZCU_BKBCANFDAvlbly "RZCU BKBCANFD  Availability";
BA_ "SysSignalName" SG_ 361 RZCU_BKBCANFDAvlbly "RZCU_BKBCANFDAvlbly";
BA_ "CompuMethodName" SG_ 361 IPD_BKPCANFDAvlbly "IPD_BKPCANFDAvlbly";
BA_ "ISignalName" SG_ 361 IPD_BKPCANFDAvlbly "IIPD_BKPCANFDAvlbly";
BA_ "LongName" SG_ 361 IPD_BKPCANFDAvlbly "ICBAD  BKPCANFD Availability";
BA_ "SysSignalName" SG_ 361 IPD_BKPCANFDAvlbly "IPD_BKPCANFDAvlbly";
BA_ "CompuMethodName" SG_ 361 IPD_CHCANFDAvlbly "IPD_CHCANFDAvlbly";
BA_ "ISignalName" SG_ 361 IPD_CHCANFDAvlbly "IIPD_CHCANFDAvlbly";
BA_ "LongName" SG_ 361 IPD_CHCANFDAvlbly "IPD CHCANFD Availability";
BA_ "SysSignalName" SG_ 361 IPD_CHCANFDAvlbly "IPD_CHCANFDAvlbly";
BA_ "CompuMethodName" SG_ 361 IBS_CHAvlbly "IBS_CHAvlbly";
BA_ "ISignalName" SG_ 361 IBS_CHAvlbly "IIBS_CHAvlbly";
BA_ "LongName" SG_ 361 IBS_CHAvlbly "IBS Availability";
BA_ "SysSignalName" SG_ 361 IBS_CHAvlbly "IBS_CHAvlbly";
BA_ "CompuMethodName" SG_ 361 FDRAvlbly "FDRAvlbly";
BA_ "ISignalName" SG_ 361 FDRAvlbly "IFDRAvlbly";
BA_ "LongName" SG_ 361 FDRAvlbly "FDR Availability";
BA_ "SysSignalName" SG_ 361 FDRAvlbly "FDRAvlbly";
BA_ "CompuMethodName" SG_ 361 RHRDAAvlbly "RHRDAAvlbly";
BA_ "ISignalName" SG_ 361 RHRDAAvlbly "IRHRDAAvlbly";
BA_ "LongName" SG_ 361 RHRDAAvlbly "RHRDA BKPCANFD Avlbly";
BA_ "SysSignalName" SG_ 361 RHRDAAvlbly "RHRDAAvlbly";
BA_ "CompuMethodName" SG_ 361 FVCMAvlbly "FVCMAvlbly";
BA_ "ISignalName" SG_ 361 FVCMAvlbly "IFVCMAvlbly";
BA_ "LongName" SG_ 361 FVCMAvlbly "FVCM BKPCANFD Availability";
BA_ "SysSignalName" SG_ 361 FVCMAvlbly "FVCMAvlbly";
BA_ "CompuMethodName" SG_ 361 TPMSAvlbly "TPMSAvlbly";
BA_ "ISignalName" SG_ 361 TPMSAvlbly "ITPMSAvlbly";
BA_ "LongName" SG_ 361 TPMSAvlbly "TPMS LHBDEXTDCAN Availability";
BA_ "SysSignalName" SG_ 361 TPMSAvlbly "TPMSAvlbly";
BA_ "CompuMethodName" SG_ 497 ICBVC_20ms_Group03_CRC "ICBVC_20ms_Group03_CRC";
BA_ "ISignalName" SG_ 497 ICBVC_20ms_Group03_CRC "IICBVC_20ms_Group03_CRC";
BA_ "LongName" SG_ 497 ICBVC_20ms_Group03_CRC "ICBVC_20ms_Group03_CRC";
BA_ "SysSignalName" SG_ 497 ICBVC_20ms_Group03_CRC "ICBVC_20ms_Group03_CRC";
BA_ "CompuMethodName" SG_ 497 ICBVC_20ms_Group03_RC "ICBVC_20ms_Group03_RC";
BA_ "ISignalName" SG_ 497 ICBVC_20ms_Group03_RC "IICBVC_20ms_Group03_RC";
BA_ "LongName" SG_ 497 ICBVC_20ms_Group03_RC "ICBVC_20ms_Group03_RC";
BA_ "SysSignalName" SG_ 497 ICBVC_20ms_Group03_RC "ICBVC_20ms_Group03_RC";
BA_ "CompuMethodName" SG_ 497 AMRPrtensonReq "AMRPrtensonReq";
BA_ "ISignalName" SG_ 497 AMRPrtensonReq "IAMRPrtensonReq";
BA_ "LongName" SG_ 497 AMRPrtensonReq "AMR_Pretension_Request";
BA_ "SysSignalName" SG_ 497 AMRPrtensonReq "AMRPrtensonReq";
BA_ "CompuMethodName" SG_ 497 ICBVC_20ms_Group03_Reserved2 "ICBVC_20ms_Group03_Reserved2";
BA_ "GenSigStartValue" SG_ 497 ICBVC_20ms_Group03_Reserved2 15;
BA_ "ISignalName" SG_ 497 ICBVC_20ms_Group03_Reserved2 "IICBVC_20ms_Group03_Reserved2";
BA_ "SysSignalName" SG_ 497 ICBVC_20ms_Group03_Reserved2 "ICBVC_20ms_Group03_Reserved2";
BA_ "CompuMethodName" SG_ 497 SysVolMdV "SysVolMdV";
BA_ "GenSigStartValue" SG_ 497 SysVolMdV 1;
BA_ "ISignalName" SG_ 497 SysVolMdV "ISysVolMdV";
BA_ "LongName" SG_ 497 SysVolMdV "System Voltage Mode Validity";
BA_ "SysSignalName" SG_ 497 SysVolMdV "SysVolMdV";
BA_ "CompuMethodName" SG_ 497 ICBVC_20ms_Group03_Reserved1 "ICBVC_20ms_Group03_Reserved1";
BA_ "GenSigStartValue" SG_ 497 ICBVC_20ms_Group03_Reserved1 7;
BA_ "ISignalName" SG_ 497 ICBVC_20ms_Group03_Reserved1 "IICBVC_20ms_Group03_Reserved1";
BA_ "SysSignalName" SG_ 497 ICBVC_20ms_Group03_Reserved1 "ICBVC_20ms_Group03_Reserved1";
BA_ "CompuMethodName" SG_ 497 ICBVC_20ms_Group03_Reserved3 "ICBVC_20ms_Group03_Reserved3";
BA_ "GenSigStartValue" SG_ 497 ICBVC_20ms_Group03_Reserved3 15;
BA_ "ISignalName" SG_ 497 ICBVC_20ms_Group03_Reserved3 "IICBVC_20ms_Group03_Reserved3";
BA_ "SysSignalName" SG_ 497 ICBVC_20ms_Group03_Reserved3 "ICBVC_20ms_Group03_Reserved3";
BA_ "CompuMethodName" SG_ 497 VehMd "VehMd";
BA_ "ISignalName" SG_ 497 VehMd "IVehMd";
BA_ "LongName" SG_ 497 VehMd "Vehicle Mode";
BA_ "SysSignalName" SG_ 497 VehMd "VehMd";
BA_ "CompuMethodName" SG_ 497 SysVolV "SysVolV";
BA_ "ISignalName" SG_ 497 SysVolV "ISysVolV";
BA_ "LongName" SG_ 497 SysVolV "System_Voltage_Validity";
BA_ "SysSignalName" SG_ 497 SysVolV "SysVolV";
BA_ "CompuMethodName" SG_ 497 SysPwrMdV "SysPwrMdV";
BA_ "GenSigStartValue" SG_ 497 SysPwrMdV 1;
BA_ "ISignalName" SG_ 497 SysPwrMdV "ISysPwrMdV";
BA_ "LongName" SG_ 497 SysPwrMdV "System Power Mode Validity";
BA_ "SysSignalName" SG_ 497 SysPwrMdV "SysPwrMdV";
BA_ "CompuMethodName" SG_ 497 VehMdV "VehMdV";
BA_ "ISignalName" SG_ 497 VehMdV "IVehMdV";
BA_ "LongName" SG_ 497 VehMdV "Vehicle Mode Validity";
BA_ "SysSignalName" SG_ 497 VehMdV "VehMdV";
BA_ "CompuMethodName" SG_ 497 UsgMdV "UsgMdV";
BA_ "ISignalName" SG_ 497 UsgMdV "IUsgMdV";
BA_ "LongName" SG_ 497 UsgMdV "Usage Mode Validity";
BA_ "SysSignalName" SG_ 497 UsgMdV "UsgMdV";
BA_ "CompuMethodName" SG_ 497 UsgMd "UsgMd";
BA_ "GenSigStartValue" SG_ 497 UsgMd 1;
BA_ "ISignalName" SG_ 497 UsgMd "IUsgMd";
BA_ "LongName" SG_ 497 UsgMd "Usage Mode";
BA_ "SysSignalName" SG_ 497 UsgMd "UsgMd";
BA_ "CompuMethodName" SG_ 497 SysVol "SysVol";
BA_ "ISignalName" SG_ 497 SysVol "ISysVol";
BA_ "LongName" SG_ 497 SysVol "System_Voltage";
BA_ "SysSignalName" SG_ 497 SysVol "SysVol";
BA_ "CompuMethodName" SG_ 497 PwrMdMstrRunCrkA "PwrMdMstrRunCrkA";
BA_ "ISignalName" SG_ 497 PwrMdMstrRunCrkA "IPwrMdMstrRunCrkA";
BA_ "LongName" SG_ 497 PwrMdMstrRunCrkA "Power_Mode_Master_Run_Crank_Active";
BA_ "SysSignalName" SG_ 497 PwrMdMstrRunCrkA "PwrMdMstrRunCrkA";
BA_ "CompuMethodName" SG_ 497 SysPwrMd "SysPwrMd";
BA_ "ISignalName" SG_ 497 SysPwrMd "ISysPwrMd";
BA_ "LongName" SG_ 497 SysPwrMd "System Power Mode";
BA_ "SysSignalName" SG_ 497 SysPwrMd "SysPwrMd";
BA_ "CompuMethodName" SG_ 497 PwrMdMstrAccryA "PwrMdMstrAccryA";
BA_ "ISignalName" SG_ 497 PwrMdMstrAccryA "IPwrMdMstrAccryA";
BA_ "LongName" SG_ 497 PwrMdMstrAccryA "Power_Mode_Master_Accessory_Active";
BA_ "SysSignalName" SG_ 497 PwrMdMstrAccryA "PwrMdMstrAccryA";
BA_ "CompuMethodName" SG_ 497 SysOpnlMd "SysOpnlMd";
BA_ "ISignalName" SG_ 497 SysOpnlMd "ISysOpnlMd";
BA_ "LongName" SG_ 497 SysOpnlMd "System Operational Mode";
BA_ "SysSignalName" SG_ 497 SysOpnlMd "SysOpnlMd";
BA_ "CompuMethodName" SG_ 497 ICBVC_20ms_Group03_Reserved4 "ICBVC_20ms_Group03_Reserved4";
BA_ "GenSigStartValue" SG_ 497 ICBVC_20ms_Group03_Reserved4 31;
BA_ "ISignalName" SG_ 497 ICBVC_20ms_Group03_Reserved4 "IICBVC_20ms_Group03_Reserved4";
BA_ "SysSignalName" SG_ 497 ICBVC_20ms_Group03_Reserved4 "ICBVC_20ms_Group03_Reserved4";
BA_ "CompuMethodName" SG_ 497 BPMMstrAvlbly "BPMMstrAvlbly";
BA_ "ISignalName" SG_ 497 BPMMstrAvlbly "IBPMMstrAvlbly";
BA_ "LongName" SG_ 497 BPMMstrAvlbly "Backup_Power_Mode_Master_Availability";
BA_ "SysSignalName" SG_ 497 BPMMstrAvlbly "BPMMstrAvlbly";
BA_ "CompuMethodName" SG_ 497 SysVolMd "SysVolMd";
BA_ "ISignalName" SG_ 497 SysVolMd "ISysVolMd";
BA_ "LongName" SG_ 497 SysVolMd "System Voltage Mode";
BA_ "SysSignalName" SG_ 497 SysVolMd "SysVolMd";
BA_ "CompuMethodName" SG_ 60 TripCntResetReq "TripCntResetReq";
BA_ "ISignalName" SG_ 60 TripCntResetReq "ITripCntResetReq";
BA_ "LongName" SG_ 60 TripCntResetReq "Trip Counter Reset Request";
BA_ "SysSignalName" SG_ 60 TripCntResetReq "TripCntResetReq";
BA_ "CompuMethodName" SG_ 60 ComKeyEnbReq "ComKeyEnbReq";
BA_ "ISignalName" SG_ 60 ComKeyEnbReq "IComKeyEnbReq";
BA_ "LongName" SG_ 60 ComKeyEnbReq "Communication Key Enable Request";
BA_ "SysSignalName" SG_ 60 ComKeyEnbReq "ComKeyEnbReq";
BA_ "SystemSignalLongSymbol" SG_ 1391 synthesized_ICBVC_SecOC_SyncMsg_ "synthesized_ICBVC_SecOC_SyncMsg_BKPCANFD_AuthInfo";
BA_ "CompuMethodName" SG_ 1391 TripCnt "TripCnt";
BA_ "GenSigStartValue" SG_ 1391 TripCnt 1;
BA_ "ISignalName" SG_ 1391 TripCnt "ITripCnt";
BA_ "LongName" SG_ 1391 TripCnt "Trip Counter";
BA_ "SysSignalName" SG_ 1391 TripCnt "TripCnt";
BA_ "CompuMethodName" SG_ 1391 ResetCnt "ResetCnt";
BA_ "GenSigStartValue" SG_ 1391 ResetCnt 1;
BA_ "ISignalName" SG_ 1391 ResetCnt "IResetCnt";
BA_ "LongName" SG_ 1391 ResetCnt "Reset Counter";
BA_ "SysSignalName" SG_ 1391 ResetCnt "ResetCnt";
BA_ "CompuMethodName" SG_ 815 EMCLPwrSts "EMCLPwrSts";
BA_ "ISignalName" SG_ 815 EMCLPwrSts "IEMCLPwrSts";
BA_ "LongName" SG_ 815 EMCLPwrSts "EMCL Power Status";
BA_ "SysSignalName" SG_ 815 EMCLPwrSts "EMCLPwrSts";
BA_ "CompuMethodName" SG_ 815 IMMPwrSts "IMMPwrSts";
BA_ "ISignalName" SG_ 815 IMMPwrSts "IIMMPwrSts";
BA_ "LongName" SG_ 815 IMMPwrSts "IMM Power Status";
BA_ "SysSignalName" SG_ 815 IMMPwrSts "IMMPwrSts";
BA_ "CompuMethodName" SG_ 815 ESCLPwrSts "ESCLPwrSts";
BA_ "ISignalName" SG_ 815 ESCLPwrSts "IESCLPwrSts";
BA_ "LongName" SG_ 815 ESCLPwrSts "ESCL Power Status";
BA_ "SysSignalName" SG_ 815 ESCLPwrSts "ESCLPwrSts";
BA_ "CompuMethodName" SG_ 815 BPEPSPwrSts "BPEPSPwrSts";
BA_ "ISignalName" SG_ 815 BPEPSPwrSts "IBPEPSPwrSts";
BA_ "LongName" SG_ 815 BPEPSPwrSts "BPEPS Power Status";
BA_ "SysSignalName" SG_ 815 BPEPSPwrSts "BPEPSPwrSts";
BA_ "CompuMethodName" SG_ 815 ARHUDPwrSts "ARHUDPwrSts";
BA_ "ISignalName" SG_ 815 ARHUDPwrSts "IARHUDPwrSts";
BA_ "LongName" SG_ 815 ARHUDPwrSts "ARHUD Power Status";
BA_ "SysSignalName" SG_ 815 ARHUDPwrSts "ARHUDPwrSts";
BA_ "CompuMethodName" SG_ 815 LHAmbtLampPwrSts "LHAmbtLampPwrSts";
BA_ "ISignalName" SG_ 815 LHAmbtLampPwrSts "ILHAmbtLampPwrSts";
BA_ "LongName" SG_ 815 LHAmbtLampPwrSts "LHAmbtLamp Power Status";
BA_ "SysSignalName" SG_ 815 LHAmbtLampPwrSts "LHAmbtLampPwrSts";
BA_ "CompuMethodName" SG_ 815 OHCPwrSts "OHCPwrSts";
BA_ "ISignalName" SG_ 815 OHCPwrSts "IOHCPwrSts";
BA_ "LongName" SG_ 815 OHCPwrSts "OHC Power Status";
BA_ "SysSignalName" SG_ 815 OHCPwrSts "OHCPwrSts";
BA_ "CompuMethodName" SG_ 815 CnsoDspPwrSts "CnsoDspPwrSts";
BA_ "ISignalName" SG_ 815 CnsoDspPwrSts "ICnsoDspPwrSts";
BA_ "LongName" SG_ 815 CnsoDspPwrSts "CnsoDsp Power Status";
BA_ "SysSignalName" SG_ 815 CnsoDspPwrSts "CnsoDspPwrSts";
BA_ "CompuMethodName" SG_ 815 FLVntngMotPwrSts "FLVntngMotPwrSts";
BA_ "ISignalName" SG_ 815 FLVntngMotPwrSts "IFLVntngMotPwrSts";
BA_ "LongName" SG_ 815 FLVntngMotPwrSts "FLVntngMot Power Status";
BA_ "SysSignalName" SG_ 815 FLVntngMotPwrSts "FLVntngMotPwrSts";
BA_ "CompuMethodName" SG_ 815 FLSLMMPwrSts "FLSLMMPwrSts";
BA_ "ISignalName" SG_ 815 FLSLMMPwrSts "IFLSLMMPwrSts";
BA_ "LongName" SG_ 815 FLSLMMPwrSts "FLSLMM Power Status";
BA_ "SysSignalName" SG_ 815 FLSLMMPwrSts "FLSLMMPwrSts";
BA_ "CompuMethodName" SG_ 815 USBHubPwrSts "USBHubPwrSts";
BA_ "ISignalName" SG_ 815 USBHubPwrSts "IUSBHubPwrSts";
BA_ "LongName" SG_ 815 USBHubPwrSts "USBHub Power Status";
BA_ "SysSignalName" SG_ 815 USBHubPwrSts "USBHubPwrSts";
BA_ "CompuMethodName" SG_ 815 DrvrDspPwrSts "DrvrDspPwrSts";
BA_ "ISignalName" SG_ 815 DrvrDspPwrSts "IDrvrDspPwrSts";
BA_ "LongName" SG_ 815 DrvrDspPwrSts "DrvrDsp Power Status";
BA_ "SysSignalName" SG_ 815 DrvrDspPwrSts "DrvrDspPwrSts";
BA_ "CompuMethodName" SG_ 815 SWSPwrSts "SWSPwrSts";
BA_ "ISignalName" SG_ 815 SWSPwrSts "ISWSPwrSts";
BA_ "LongName" SG_ 815 SWSPwrSts "LHSWS Power Status";
BA_ "SysSignalName" SG_ 815 SWSPwrSts "SWSPwrSts";
BA_ "CompuMethodName" SG_ 815 BrkSwPwrSts "BrkSwPwrSts";
BA_ "ISignalName" SG_ 815 BrkSwPwrSts "IBrkSwPwrSts";
BA_ "LongName" SG_ 815 BrkSwPwrSts "BrkSw Power Status";
BA_ "SysSignalName" SG_ 815 BrkSwPwrSts "BrkSwPwrSts";
BA_ "CompuMethodName" SG_ 815 HODMPwrSts "HODMPwrSts";
BA_ "ISignalName" SG_ 815 HODMPwrSts "IHODMPwrSts";
BA_ "LongName" SG_ 815 HODMPwrSts "HODM Power Status";
BA_ "SysSignalName" SG_ 815 HODMPwrSts "HODMPwrSts";
BA_ "CompuMethodName" SG_ 815 RLSSPwrSts "RLSSPwrSts";
BA_ "ISignalName" SG_ 815 RLSSPwrSts "IRLSSPwrSts";
BA_ "LongName" SG_ 815 RLSSPwrSts "RLSS Power Status";
BA_ "SysSignalName" SG_ 815 RLSSPwrSts "RLSSPwrSts";
BA_ "CompuMethodName" SG_ 815 ETCMPwrSts "ETCMPwrSts";
BA_ "ISignalName" SG_ 815 ETCMPwrSts "IETCMPwrSts";
BA_ "LongName" SG_ 815 ETCMPwrSts "ETCM  Power Status";
BA_ "SysSignalName" SG_ 815 ETCMPwrSts "ETCMPwrSts";
BA_ "CompuMethodName" SG_ 815 LHSWPwrSts "LHSWPwrSts";
BA_ "ISignalName" SG_ 815 LHSWPwrSts "ILHSWPwrSts";
BA_ "LongName" SG_ 815 LHSWPwrSts "LHSW Power Status";
BA_ "SysSignalName" SG_ 815 LHSWPwrSts "LHSWPwrSts";
BA_ "CompuMethodName" SG_ 815 NFCAMPwrSts "NFCAMPwrSts";
BA_ "ISignalName" SG_ 815 NFCAMPwrSts "INFCAMPwrSts";
BA_ "LongName" SG_ 815 NFCAMPwrSts "NFCAM Power Status";
BA_ "SysSignalName" SG_ 815 NFCAMPwrSts "NFCAMPwrSts";
BA_ "CompuMethodName" SG_ 815 NFCSMPwrSts "NFCSMPwrSts";
BA_ "ISignalName" SG_ 815 NFCSMPwrSts "INFCSMPwrSts";
BA_ "LongName" SG_ 815 NFCSMPwrSts "NFCSM Power Status";
BA_ "SysSignalName" SG_ 815 NFCSMPwrSts "NFCSMPwrSts";
BA_ "CompuMethodName" SG_ 815 SACPwrSts "SACPwrSts";
BA_ "ISignalName" SG_ 815 SACPwrSts "ISACPwrSts";
BA_ "LongName" SG_ 815 SACPwrSts "SAC Power Status";
BA_ "SysSignalName" SG_ 815 SACPwrSts "SACPwrSts";
BA_ "CompuMethodName" SG_ 815 CnsoUSBPwrSts "CnsoUSBPwrSts";
BA_ "ISignalName" SG_ 815 CnsoUSBPwrSts "ICnsoUSBPwrSts";
BA_ "LongName" SG_ 815 CnsoUSBPwrSts "CnsoUSB Power Status";
BA_ "SysSignalName" SG_ 815 CnsoUSBPwrSts "CnsoUSBPwrSts";
BA_ "CompuMethodName" SG_ 815 RrPDCPwrSts "RrPDCPwrSts";
BA_ "ISignalName" SG_ 815 RrPDCPwrSts "IRrPDCPwrSts";
BA_ "LongName" SG_ 815 RrPDCPwrSts "RrPDC Power Status";
BA_ "SysSignalName" SG_ 815 RrPDCPwrSts "RrPDCPwrSts";
BA_ "CompuMethodName" SG_ 815 FrtPDCPwrSts "FrtPDCPwrSts";
BA_ "ISignalName" SG_ 815 FrtPDCPwrSts "IFrtPDCPwrSts";
BA_ "LongName" SG_ 815 FrtPDCPwrSts "FrtPDC Power Status";
BA_ "SysSignalName" SG_ 815 FrtPDCPwrSts "FrtPDCPwrSts";
BA_ "CompuMethodName" SG_ 815 FVCMPwrSts "FVCMPwrSts";
BA_ "ISignalName" SG_ 815 FVCMPwrSts "IFVCMPwrSts";
BA_ "LongName" SG_ 815 FVCMPwrSts "FVCM Power Status";
BA_ "SysSignalName" SG_ 815 FVCMPwrSts "FVCMPwrSts";
BA_ "CompuMethodName" SG_ 815 TPMSPwrSts "TPMSPwrSts";
BA_ "ISignalName" SG_ 815 TPMSPwrSts "ITPMSPwrSts";
BA_ "LongName" SG_ 815 TPMSPwrSts "TPMS Power Status";
BA_ "SysSignalName" SG_ 815 TPMSPwrSts "TPMSPwrSts";
BA_ "CompuMethodName" SG_ 815 AIBOTPwrSts "AIBOTPwrSts";
BA_ "ISignalName" SG_ 815 AIBOTPwrSts "IAIBOTPwrSts";
BA_ "LongName" SG_ 815 AIBOTPwrSts "AIBOT Power Status";
BA_ "SysSignalName" SG_ 815 AIBOTPwrSts "AIBOTPwrSts";
BA_ "CompuMethodName" SG_ 815 IterMirPwrSts "IterMirPwrSts";
BA_ "ISignalName" SG_ 815 IterMirPwrSts "IIterMirPwrSts";
BA_ "LongName" SG_ 815 IterMirPwrSts "IterMir Power Status";
BA_ "SysSignalName" SG_ 815 IterMirPwrSts "IterMirPwrSts";
BA_ "CompuMethodName" SG_ 815 IMSPwrSts "IMSPwrSts";
BA_ "ISignalName" SG_ 815 IMSPwrSts "IIMSPwrSts";
BA_ "LongName" SG_ 815 IMSPwrSts "IMS Power Status";
BA_ "SysSignalName" SG_ 815 IMSPwrSts "IMSPwrSts";
BA_ "CompuMethodName" SG_ 815 CPDPwrSts "CPDPwrSts";
BA_ "ISignalName" SG_ 815 CPDPwrSts "ICPDPwrSts";
BA_ "LongName" SG_ 815 CPDPwrSts "CPD Power Status";
BA_ "SysSignalName" SG_ 815 CPDPwrSts "CPDPwrSts";
BA_ "CompuMethodName" SG_ 815 DABMPwrSts "DABMPwrSts";
BA_ "ISignalName" SG_ 815 DABMPwrSts "IDABMPwrSts";
BA_ "LongName" SG_ 815 DABMPwrSts "DABM Power Status";
BA_ "SysSignalName" SG_ 815 DABMPwrSts "DABMPwrSts";
BA_ "CompuMethodName" SG_ 913 RHSwPwrSts "RHSwPwrSts";
BA_ "ISignalName" SG_ 913 RHSwPwrSts "IRHSwPwrSts";
BA_ "LongName" SG_ 913 RHSwPwrSts "RHSw Power Status";
BA_ "SysSignalName" SG_ 913 RHSwPwrSts "RHSwPwrSts";
BA_ "CompuMethodName" SG_ 913 RHAmbtLampPwrSts "RHAmbtLampPwrSts";
BA_ "ISignalName" SG_ 913 RHAmbtLampPwrSts "IRHAmbtLampPwrSts";
BA_ "LongName" SG_ 913 RHAmbtLampPwrSts "RHAmbtLamp Power Status";
BA_ "SysSignalName" SG_ 913 RHAmbtLampPwrSts "RHAmbtLampPwrSts";
BA_ "CompuMethodName" SG_ 913 CnsoUSB1PwrSts "CnsoUSB1PwrSts";
BA_ "ISignalName" SG_ 913 CnsoUSB1PwrSts "ICnsoUSB1PwrSts";
BA_ "LongName" SG_ 913 CnsoUSB1PwrSts "CnsoUSB1 Power Status";
BA_ "SysSignalName" SG_ 913 CnsoUSB1PwrSts "CnsoUSB1PwrSts";
BA_ "CompuMethodName" SG_ 913 AirVentMotPwrSts "AirVentMotPwrSts";
BA_ "ISignalName" SG_ 913 AirVentMotPwrSts "IAirVentMotPwrSts";
BA_ "LongName" SG_ 913 AirVentMotPwrSts "AirVentMot Power Status";
BA_ "SysSignalName" SG_ 913 AirVentMotPwrSts "AirVentMotPwrSts";
BA_ "CompuMethodName" SG_ 913 CFPwrSts "CFPwrSts";
BA_ "ISignalName" SG_ 913 CFPwrSts "ICFPwrSts";
BA_ "LongName" SG_ 913 CFPwrSts "CF Power Status";
BA_ "SysSignalName" SG_ 913 CFPwrSts "CFPwrSts";
BA_ "CompuMethodName" SG_ 913 FRVntngMotPwrSts "FRVntngMotPwrSts";
BA_ "ISignalName" SG_ 913 FRVntngMotPwrSts "IFRVntngMotPwrSts";
BA_ "LongName" SG_ 913 FRVntngMotPwrSts "FRVntngMot Power Status";
BA_ "SysSignalName" SG_ 913 FRVntngMotPwrSts "FRVntngMotPwrSts";
BA_ "CompuMethodName" SG_ 913 FRSLMMPwrSts "FRSLMMPwrSts";
BA_ "ISignalName" SG_ 913 FRSLMMPwrSts "IFRSLMMPwrSts";
BA_ "LongName" SG_ 913 FRSLMMPwrSts "FRSLMM Power Status";
BA_ "SysSignalName" SG_ 913 FRSLMMPwrSts "FRSLMMPwrSts";
BA_ "CompuMethodName" SG_ 913 FrtPwrSktPwrSts "FrtPwrSktPwrSts";
BA_ "ISignalName" SG_ 913 FrtPwrSktPwrSts "IFrtPwrSktPwrSts";
BA_ "LongName" SG_ 913 FrtPwrSktPwrSts "FrtPwrSkt Power Status";
BA_ "SysSignalName" SG_ 913 FrtPwrSktPwrSts "FrtPwrSktPwrSts";
BA_ "CompuMethodName" SG_ 913 FrtSDAPwrSts "FrtSDAPwrSts";
BA_ "ISignalName" SG_ 913 FrtSDAPwrSts "IFrtSDAPwrSts";
BA_ "LongName" SG_ 913 FrtSDAPwrSts "FrtSDA Power Status";
BA_ "SysSignalName" SG_ 913 FrtSDAPwrSts "FrtSDAPwrSts";
BA_ "CompuMethodName" SG_ 913 FLiDARPwrSts "FLiDARPwrSts";
BA_ "ISignalName" SG_ 913 FLiDARPwrSts "IFLiDARPwrSts";
BA_ "LongName" SG_ 913 FLiDARPwrSts "FLiDAR Power Status";
BA_ "SysSignalName" SG_ 913 FLiDARPwrSts "FLiDARPwrSts";
BA_ "CompuMethodName" SG_ 913 IAMPwrSts "IAMPwrSts";
BA_ "ISignalName" SG_ 913 IAMPwrSts "IIAMPwrSts";
BA_ "LongName" SG_ 913 IAMPwrSts "IAM Power Status";
BA_ "SysSignalName" SG_ 913 IAMPwrSts "IAMPwrSts";
BA_ "CompuMethodName" SG_ 913 SDMPwrSts "SDMPwrSts";
BA_ "ISignalName" SG_ 913 SDMPwrSts "ISDMPwrSts";
BA_ "LongName" SG_ 913 SDMPwrSts "SDM Power Status";
BA_ "SysSignalName" SG_ 913 SDMPwrSts "SDMPwrSts";
BA_ "CompuMethodName" SG_ 913 FDRPwrSts "FDRPwrSts";
BA_ "ISignalName" SG_ 913 FDRPwrSts "IFDRPwrSts";
BA_ "LongName" SG_ 913 FDRPwrSts "FDR Power Status";
BA_ "SysSignalName" SG_ 913 FDRPwrSts "FDRPwrSts";
BA_ "CompuMethodName" SG_ 902 AVPMapRutMgIDtReq "AVPMapRutMgIDtReq";
BA_ "ISignalName" SG_ 902 AVPMapRutMgIDtReq "IAVPMapRutMgIDtReq";
BA_ "LongName" SG_ 902 AVPMapRutMgIDtReq "AVP_Map_Route_Management_ID_Requst";
BA_ "SysSignalName" SG_ 902 AVPMapRutMgIDtReq "AVPMapRutMgIDtReq";
BA_ "CompuMethodName" SG_ 902 IPDPowerFailSwReq "IPDPowerFailSwReq";
BA_ "ISignalName" SG_ 902 IPDPowerFailSwReq "IIPDPowerFailSwReq";
BA_ "LongName" SG_ 902 IPDPowerFailSwReq "IPD_Power_Faile_Switch_Request";
BA_ "SysSignalName" SG_ 902 IPDPowerFailSwReq "IPDPowerFailSwReq";
BA_ "CompuMethodName" SG_ 902 RACtlReq "RACtlReq";
BA_ "ISignalName" SG_ 902 RACtlReq "IRACtlReq";
BA_ "LongName" SG_ 902 RACtlReq "Reverse Assist Contro Requst";
BA_ "SysSignalName" SG_ 902 RACtlReq "RACtlReq";
BA_ "CompuMethodName" SG_ 902 ShwrmComprEnbReq "ShwrmComprEnbReq";
BA_ "ISignalName" SG_ 902 ShwrmComprEnbReq "IShwrmComprEnbReq";
BA_ "LongName" SG_ 902 ShwrmComprEnbReq "Showroom_Compressor_Enable_Request";
BA_ "SysSignalName" SG_ 902 ShwrmComprEnbReq "ShwrmComprEnbReq";
BA_ "CompuMethodName" SG_ 902 SrfOpenSts "SrfOpenSts";
BA_ "GenSigStartValue" SG_ 902 SrfOpenSts 6;
BA_ "ISignalName" SG_ 902 SrfOpenSts "ISrfOpenSts";
BA_ "LongName" SG_ 902 SrfOpenSts "Sunroof Open Status";
BA_ "SysSignalName" SG_ 902 SrfOpenSts "SrfOpenSts";
BA_ "CompuMethodName" SG_ 902 RainClsWndAppMsg "RainClsWndAppMsg";
BA_ "ISignalName" SG_ 902 RainClsWndAppMsg "IRainClsWndAppMsg";
BA_ "LongName" SG_ 902 RainClsWndAppMsg "Rain Close Window App reminder msg";
BA_ "SysSignalName" SG_ 902 RainClsWndAppMsg "RainClsWndAppMsg";
BA_ "CompuMethodName" SG_ 955 ClstrDspdVehSpd_mph "ClstrDspdVehSpd_mph";
BA_ "ISignalName" SG_ 955 ClstrDspdVehSpd_mph "IClstrDspdVehSpd_mph";
BA_ "LongName" SG_ 955 ClstrDspdVehSpd_mph "Cluster Displayed Vehicle Speed_mph";
BA_ "SysSignalName" SG_ 955 ClstrDspdVehSpd_mph "ClstrDspdVehSpd_mph";
BA_ "CompuMethodName" SG_ 955 RrSsdPosCtrl "RrSsdPosCtrl";
BA_ "GenSigStartValue" SG_ 955 RrSsdPosCtrl 255;
BA_ "ISignalName" SG_ 955 RrSsdPosCtrl "IRrSsdPosCtrl";
BA_ "LongName" SG_ 955 RrSsdPosCtrl "Rear_Sunshade_Position_Control";
BA_ "SysSignalName" SG_ 955 RrSsdPosCtrl "RrSsdPosCtrl";
BA_ "CompuMethodName" SG_ 955 ACCTJAMdSwReq "ACCTJAMdSwReq";
BA_ "ISignalName" SG_ 955 ACCTJAMdSwReq "IACCTJAMdSwReq";
BA_ "LongName" SG_ 955 ACCTJAMdSwReq "Adaptive_Cruise_Control_Traffic_Jam_Assist_Mode_Switch_Request";
BA_ "SysSignalName" SG_ 955 ACCTJAMdSwReq "ACCTJAMdSwReq";
BA_ "CompuMethodName" SG_ 955 FICMACLTemReq "FICMACLTemReq";
BA_ "GenSigStartValue" SG_ 955 FICMACLTemReq 31;
BA_ "ISignalName" SG_ 955 FICMACLTemReq "IFICMACLTemReq";
BA_ "LongName" SG_ 955 FICMACLTemReq "Front Infotainment Control Module Air Conditioning Left Temperature Request";
BA_ "SysSignalName" SG_ 955 FICMACLTemReq "FICMACLTemReq";
BA_ "CompuMethodName" SG_ 955 SpdLmtOfstSetReq "SpdLmtOfstSetReq";
BA_ "GenSigStartValue" SG_ 955 SpdLmtOfstSetReq 20;
BA_ "ISignalName" SG_ 955 SpdLmtOfstSetReq "ISpdLmtOfstSetReq";
BA_ "LongName" SG_ 955 SpdLmtOfstSetReq "Speed Limit Offset Set Request";
BA_ "SysSignalName" SG_ 955 SpdLmtOfstSetReq "SpdLmtOfstSetReq";
BA_ "CompuMethodName" SG_ 955 ACCStsSwReq "ACCStsSwReq";
BA_ "ISignalName" SG_ 955 ACCStsSwReq "IACCStsSwReq";
BA_ "LongName" SG_ 955 ACCStsSwReq "ACC status switch request";
BA_ "SysSignalName" SG_ 955 ACCStsSwReq "ACCStsSwReq";
BA_ "CompuMethodName" SG_ 955 ACCSpdLimtSwReq "ACCSpdLimtSwReq";
BA_ "ISignalName" SG_ 955 ACCSpdLimtSwReq "IACCSpdLimtSwReq";
BA_ "LongName" SG_ 955 ACCSpdLimtSwReq "ACC speed limit swtich request";
BA_ "SysSignalName" SG_ 955 ACCSpdLimtSwReq "ACCSpdLimtSwReq";
BA_ "CompuMethodName" SG_ 955 ACCCurveSpdSwReq "ACCCurveSpdSwReq";
BA_ "ISignalName" SG_ 955 ACCCurveSpdSwReq "IACCCurveSpdSwReq";
BA_ "LongName" SG_ 955 ACCCurveSpdSwReq "ACC curve speed switch request";
BA_ "SysSignalName" SG_ 955 ACCCurveSpdSwReq "ACCCurveSpdSwReq";
BA_ "CompuMethodName" SG_ 955 ACCConfmSwReq "ACCConfmSwReq";
BA_ "ISignalName" SG_ 955 ACCConfmSwReq "IACCConfmSwReq";
BA_ "LongName" SG_ 955 ACCConfmSwReq "ACC confirm  switch request";
BA_ "SysSignalName" SG_ 955 ACCConfmSwReq "ACCConfmSwReq";
BA_ "CompuMethodName" SG_ 955 ACUserCustEcoSetngReqV "ACUserCustEcoSetngReqV";
BA_ "GenSigStartValue" SG_ 955 ACUserCustEcoSetngReqV 1;
BA_ "ISignalName" SG_ 955 ACUserCustEcoSetngReqV "IACUserCustEcoSetngReqV";
BA_ "LongName" SG_ 955 ACUserCustEcoSetngReqV "Air Conditioning User Customization Economy Setting Request Validity";
BA_ "SysSignalName" SG_ 955 ACUserCustEcoSetngReqV "ACUserCustEcoSetngReqV";
BA_ "CompuMethodName" SG_ 955 ACUserCustEcoSetngReq "ACUserCustEcoSetngReq";
BA_ "ISignalName" SG_ 955 ACUserCustEcoSetngReq "IACUserCustEcoSetngReq";
BA_ "LongName" SG_ 955 ACUserCustEcoSetngReq "Air Conditioning User Customization Economy Setting Request";
BA_ "SysSignalName" SG_ 955 ACUserCustEcoSetngReq "ACUserCustEcoSetngReq";
BA_ "CompuMethodName" SG_ 955 ACUserCustAutoMdBlwrReqV "ACUserCustAutoMdBlwrReqV";
BA_ "GenSigStartValue" SG_ 955 ACUserCustAutoMdBlwrReqV 1;
BA_ "ISignalName" SG_ 955 ACUserCustAutoMdBlwrReqV "IACUserCustAutoMdBlwrReqV";
BA_ "LongName" SG_ 955 ACUserCustAutoMdBlwrReqV "Air Conditioning User Customization Auto Mode Blower Request Validity";
BA_ "SysSignalName" SG_ 955 ACUserCustAutoMdBlwrReqV "ACUserCustAutoMdBlwrReqV";
BA_ "CompuMethodName" SG_ 955 ACUserCustAutoMdBlwrReq "ACUserCustAutoMdBlwrReq";
BA_ "GenSigStartValue" SG_ 955 ACUserCustAutoMdBlwrReq 1;
BA_ "ISignalName" SG_ 955 ACUserCustAutoMdBlwrReq "IACUserCustAutoMdBlwrReq";
BA_ "LongName" SG_ 955 ACUserCustAutoMdBlwrReq "Air Conditioning User Customization Auto Mode Blower Request";
BA_ "SysSignalName" SG_ 955 ACUserCustAutoMdBlwrReq "ACUserCustAutoMdBlwrReq";
BA_ "CompuMethodName" SG_ 955 ACUserCustAftRunOnOffReqV "ACUserCustAftRunOnOffReqV";
BA_ "GenSigStartValue" SG_ 955 ACUserCustAftRunOnOffReqV 1;
BA_ "ISignalName" SG_ 955 ACUserCustAftRunOnOffReqV "IACUserCustAftRunOnOffReqV";
BA_ "LongName" SG_ 955 ACUserCustAftRunOnOffReqV "Air Conditioning User Customization After Run On Off Request Validity";
BA_ "SysSignalName" SG_ 955 ACUserCustAftRunOnOffReqV "ACUserCustAftRunOnOffReqV";
BA_ "CompuMethodName" SG_ 955 ACUserCustAftRunOnOffR "ACUserCustAftRunOnOffR";
BA_ "ISignalName" SG_ 955 ACUserCustAftRunOnOffR "IACUserCustAftRunOnOffR";
BA_ "LongName" SG_ 955 ACUserCustAftRunOnOffR "Air Conditioning User Customization After Run On Off Request";
BA_ "SysSignalName" SG_ 955 ACUserCustAftRunOnOffR "ACUserCustAftRunOnOffR";
BA_ "CompuMethodName" SG_ 955 FICMACFrtBlwrSpdDecSwR "FICMACFrtBlwrSpdDecSwR";
BA_ "ISignalName" SG_ 955 FICMACFrtBlwrSpdDecSwR "IFICMACFrtBlwrSpdDecSwR";
BA_ "LongName" SG_ 955 FICMACFrtBlwrSpdDecSwR "Front Infotainment Control Module Air Conditioning Front Blower Speed Decrease Switch Request";
BA_ "SysSignalName" SG_ 955 FICMACFrtBlwrSpdDecSwR "FICMACFrtBlwrSpdDecSwR";
BA_ "CompuMethodName" SG_ 955 FICMACAutoSwReq "FICMACAutoSwReq";
BA_ "ISignalName" SG_ 955 FICMACAutoSwReq "IFICMACAutoSwReq";
BA_ "LongName" SG_ 955 FICMACAutoSwReq "Front Infotainment Control Module Air Conditioning Auto Swtich Request";
BA_ "SysSignalName" SG_ 955 FICMACAutoSwReq "FICMACAutoSwReq";
BA_ "CompuMethodName" SG_ 955 ADAudioSWReq "ADAudioSWReq";
BA_ "ISignalName" SG_ 955 ADAudioSWReq "IADAudioSWReq";
BA_ "LongName" SG_ 955 ADAudioSWReq "AD audio switch request";
BA_ "SysSignalName" SG_ 955 ADAudioSWReq "ADAudioSWReq";
BA_ "CompuMethodName" SG_ 955 FICMACLTemDecSwReq "FICMACLTemDecSwReq";
BA_ "ISignalName" SG_ 955 FICMACLTemDecSwReq "IFICMACLTemDecSwReq";
BA_ "LongName" SG_ 955 FICMACLTemDecSwReq "Front Infotainment Control Module Air Conditioning Left Temperature Decrease Switch Request";
BA_ "SysSignalName" SG_ 955 FICMACLTemDecSwReq "FICMACLTemDecSwReq";
BA_ "CompuMethodName" SG_ 955 FICMACFrtBlwrSpdIncSwR "FICMACFrtBlwrSpdIncSwR";
BA_ "ISignalName" SG_ 955 FICMACFrtBlwrSpdIncSwR "IFICMACFrtBlwrSpdIncSwR";
BA_ "LongName" SG_ 955 FICMACFrtBlwrSpdIncSwR "Front Infotainment Control Module Air Conditioning Front Blower Speed Increase Switch Request";
BA_ "SysSignalName" SG_ 955 FICMACFrtBlwrSpdIncSwR "FICMACFrtBlwrSpdIncSwR";
BA_ "CompuMethodName" SG_ 955 FICMACFrtBlwrLvlReq "FICMACFrtBlwrLvlReq";
BA_ "ISignalName" SG_ 955 FICMACFrtBlwrLvlReq "IFICMACFrtBlwrLvlReq";
BA_ "LongName" SG_ 955 FICMACFrtBlwrLvlReq "Front Infotainment Control Module Air Conditioning Front Blower Level Request";
BA_ "SysSignalName" SG_ 955 FICMACFrtBlwrLvlReq "FICMACFrtBlwrLvlReq";
BA_ "CompuMethodName" SG_ 955 FICMACOnOffSwReq "FICMACOnOffSwReq";
BA_ "ISignalName" SG_ 955 FICMACOnOffSwReq "IFICMACOnOffSwReq";
BA_ "LongName" SG_ 955 FICMACOnOffSwReq "Front Infotainment Control Module Air Conditioning On Off Switch Request";
BA_ "SysSignalName" SG_ 955 FICMACOnOffSwReq "FICMACOnOffSwReq";
BA_ "CompuMethodName" SG_ 955 FICMACLTemIncSwReq "FICMACLTemIncSwReq";
BA_ "ISignalName" SG_ 955 FICMACLTemIncSwReq "IFICMACLTemIncSwReq";
BA_ "LongName" SG_ 955 FICMACLTemIncSwReq "Front Infotainment Control Module Air Conditioning Left Temperature Increase Switch Request";
BA_ "SysSignalName" SG_ 955 FICMACLTemIncSwReq "FICMACLTemIncSwReq";
BA_ "CompuMethodName" SG_ 955 FICMACLAirMdReqV "FICMACLAirMdReqV";
BA_ "GenSigStartValue" SG_ 955 FICMACLAirMdReqV 1;
BA_ "ISignalName" SG_ 955 FICMACLAirMdReqV "IFICMACLAirMdReqV";
BA_ "LongName" SG_ 955 FICMACLAirMdReqV "Front Infotainment Control Module Air Conditioning Left Air Mode Request Validity";
BA_ "SysSignalName" SG_ 955 FICMACLAirMdReqV "FICMACLAirMdReqV";
BA_ "CompuMethodName" SG_ 955 FICMACLAirMdReq "FICMACLAirMdReq";
BA_ "GenSigStartValue" SG_ 955 FICMACLAirMdReq 7;
BA_ "ISignalName" SG_ 955 FICMACLAirMdReq "IFICMACLAirMdReq";
BA_ "LongName" SG_ 955 FICMACLAirMdReq "Front Infotainment Control Module Air Conditioning Left Air Mode Request";
BA_ "SysSignalName" SG_ 955 FICMACLAirMdReq "FICMACLAirMdReq";
BA_ "CompuMethodName" SG_ 955 FICMComprOnOffSwReq "FICMComprOnOffSwReq";
BA_ "ISignalName" SG_ 955 FICMComprOnOffSwReq "IFICMComprOnOffSwReq";
BA_ "LongName" SG_ 955 FICMComprOnOffSwReq "Front Infotainment Control Module Compressor On Off Switch Request";
BA_ "SysSignalName" SG_ 955 FICMComprOnOffSwReq "FICMComprOnOffSwReq";
BA_ "CompuMethodName" SG_ 955 FICMACSemiAutoSwReq "FICMACSemiAutoSwReq";
BA_ "ISignalName" SG_ 955 FICMACSemiAutoSwReq "IFICMACSemiAutoSwReq";
BA_ "LongName" SG_ 955 FICMACSemiAutoSwReq "Front Infotainment Control Module Air Conditioning Semi Auto Switch Request";
BA_ "SysSignalName" SG_ 955 FICMACSemiAutoSwReq "FICMACSemiAutoSwReq";
BA_ "CompuMethodName" SG_ 955 FICMACRcctnSwReq "FICMACRcctnSwReq";
BA_ "ISignalName" SG_ 955 FICMACRcctnSwReq "IFICMACRcctnSwReq";
BA_ "LongName" SG_ 955 FICMACRcctnSwReq "Front Infotainment Control Module Air Conditioning Recirculation Switch Request";
BA_ "SysSignalName" SG_ 955 FICMACRcctnSwReq "FICMACRcctnSwReq";
BA_ "CompuMethodName" SG_ 955 FICMACRcctnMdReq "FICMACRcctnMdReq";
BA_ "GenSigStartValue" SG_ 955 FICMACRcctnMdReq 3;
BA_ "ISignalName" SG_ 955 FICMACRcctnMdReq "IFICMACRcctnMdReq";
BA_ "LongName" SG_ 955 FICMACRcctnMdReq "Front Infotainment Control Module Air Conditioning Recirculation Mode Request";
BA_ "SysSignalName" SG_ 955 FICMACRcctnMdReq "FICMACRcctnMdReq";
BA_ "CompuMethodName" SG_ 955 FICMHtdRrWndSwReq "FICMHtdRrWndSwReq";
BA_ "ISignalName" SG_ 955 FICMHtdRrWndSwReq "IFICMHtdRrWndSwReq";
BA_ "LongName" SG_ 955 FICMHtdRrWndSwReq "Front Infotainment Control Module Heated Rear Window Switch Request";
BA_ "SysSignalName" SG_ 955 FICMHtdRrWndSwReq "FICMHtdRrWndSwReq";
BA_ "CompuMethodName" SG_ 955 FICMDfstOnSwReq "FICMDfstOnSwReq";
BA_ "ISignalName" SG_ 955 FICMDfstOnSwReq "IFICMDfstOnSwReq";
BA_ "LongName" SG_ 955 FICMDfstOnSwReq "Front Infotainment Control Module Defrost On Switch Request";
BA_ "SysSignalName" SG_ 955 FICMDfstOnSwReq "FICMDfstOnSwReq";
BA_ "CompuMethodName" SG_ 955 FICMACLTemV "FICMACLTemV";
BA_ "GenSigStartValue" SG_ 955 FICMACLTemV 1;
BA_ "ISignalName" SG_ 955 FICMACLTemV "IFICMACLTemV";
BA_ "LongName" SG_ 955 FICMACLTemV "Front Infotainment Control Module Air Conditioning Left Temperature Validity";
BA_ "SysSignalName" SG_ 955 FICMACLTemV "FICMACLTemV";
BA_ "CompuMethodName" SG_ 955 TLRMdSwReq "TLRMdSwReq";
BA_ "ISignalName" SG_ 955 TLRMdSwReq "ITLRMdSwReq";
BA_ "LongName" SG_ 955 TLRMdSwReq "Traffic_lights_recognition_Mode_Switch_Display_Request";
BA_ "SysSignalName" SG_ 955 TLRMdSwReq "TLRMdSwReq";
BA_ "CompuMethodName" SG_ 955 TSRSwReq "TSRSwReq";
BA_ "ISignalName" SG_ 955 TSRSwReq "ITSRSwReq";
BA_ "LongName" SG_ 955 TSRSwReq "TSR_Switch_Request_Response";
BA_ "SysSignalName" SG_ 955 TSRSwReq "TSRSwReq";
BA_ "CompuMethodName" SG_ 955 NonDirectDMSSwReq "NonDirectDMSSwReq";
BA_ "ISignalName" SG_ 955 NonDirectDMSSwReq "INonDirectDMSSwReq";
BA_ "LongName" SG_ 955 NonDirectDMSSwReq "Non-directional_Driver_Monitor_System_Switch_Request";
BA_ "SysSignalName" SG_ 955 NonDirectDMSSwReq "NonDirectDMSSwReq";
BA_ "CompuMethodName" SG_ 955 SpdLmtOfstSetNumReq "SpdLmtOfstSetNumReq";
BA_ "ISignalName" SG_ 955 SpdLmtOfstSetNumReq "ISpdLmtOfstSetNumReq";
BA_ "LongName" SG_ 955 SpdLmtOfstSetNumReq "Speed Limit Offset Set Number_Request";
BA_ "SysSignalName" SG_ 955 SpdLmtOfstSetNumReq "SpdLmtOfstSetNumReq";
BA_ "CompuMethodName" SG_ 955 ILCSwReq "ILCSwReq";
BA_ "ISignalName" SG_ 955 ILCSwReq "IILCSwReq";
BA_ "LongName" SG_ 955 ILCSwReq "Intelligent_Lateral_Control_Switch_Request";
BA_ "SysSignalName" SG_ 955 ILCSwReq "ILCSwReq";
BA_ "CompuMethodName" SG_ 955 ASSInhBtnA "ASSInhBtnA";
BA_ "ISignalName" SG_ 955 ASSInhBtnA "IASSInhBtnA";
BA_ "LongName" SG_ 955 ASSInhBtnA "Auto Stop Start Inhibit Button Active";
BA_ "SysSignalName" SG_ 955 ASSInhBtnA "ASSInhBtnA";
BA_ "CompuMethodName" SG_ 955 ClstrElecCsumpUnit "ClstrElecCsumpUnit";
BA_ "ISignalName" SG_ 955 ClstrElecCsumpUnit "IClstrElecCsumpUnit";
BA_ "LongName" SG_ 955 ClstrElecCsumpUnit "Cluster Electricity Consumption Unit";
BA_ "SysSignalName" SG_ 955 ClstrElecCsumpUnit "ClstrElecCsumpUnit";
BA_ "CompuMethodName" SG_ 955 SpdLmtOfstSetPercReq "SpdLmtOfstSetPercReq";
BA_ "ISignalName" SG_ 955 SpdLmtOfstSetPercReq "ISpdLmtOfstSetPercReq";
BA_ "LongName" SG_ 955 SpdLmtOfstSetPercReq "Speed Limit Offset Set Percent_Request";
BA_ "SysSignalName" SG_ 955 SpdLmtOfstSetPercReq "SpdLmtOfstSetPercReq";
BA_ "CompuMethodName" SG_ 955 EBSBatSOFVol1 "EBSBatSOFVol1";
BA_ "GenSigStartValue" SG_ 955 EBSBatSOFVol1 136;
BA_ "ISignalName" SG_ 955 EBSBatSOFVol1 "IEBSBatSOFVol1";
BA_ "LongName" SG_ 955 EBSBatSOFVol1 "Electronic Battery State Of Function Voltage1 Battery voltage at cranking peak";
BA_ "SysSignalName" SG_ 955 EBSBatSOFVol1 "EBSBatSOFVol1";
BA_ "CompuMethodName" SG_ 955 EBSBatSOFVol2 "EBSBatSOFVol2";
BA_ "GenSigStartValue" SG_ 955 EBSBatSOFVol2 152;
BA_ "ISignalName" SG_ 955 EBSBatSOFVol2 "IEBSBatSOFVol2";
BA_ "LongName" SG_ 955 EBSBatSOFVol2 "Electronic Battery State Of Function Voltage2 Battery voltage after acranking peak";
BA_ "SysSignalName" SG_ 955 EBSBatSOFVol2 "EBSBatSOFVol2";
BA_ "CompuMethodName" SG_ 955 EBSBatSOFVol2Sts "EBSBatSOFVol2Sts";
BA_ "GenSigStartValue" SG_ 955 EBSBatSOFVol2Sts 2;
BA_ "ISignalName" SG_ 955 EBSBatSOFVol2Sts "IEBSBatSOFVol2Sts";
BA_ "LongName" SG_ 955 EBSBatSOFVol2Sts "Electronic Battery State Of Function Voltage2 Status";
BA_ "SysSignalName" SG_ 955 EBSBatSOFVol2Sts "EBSBatSOFVol2Sts";
BA_ "CompuMethodName" SG_ 955 GenrExctnCrnt "GenrExctnCrnt";
BA_ "GenSigStartValue" SG_ 955 GenrExctnCrnt 8;
BA_ "ISignalName" SG_ 955 GenrExctnCrnt "IGenrExctnCrnt";
BA_ "LongName" SG_ 955 GenrExctnCrnt "Generator Excitation Current";
BA_ "SysSignalName" SG_ 955 GenrExctnCrnt "GenrExctnCrnt";
BA_ "CompuMethodName" SG_ 955 ASSStsFICM "ASSStsFICM";
BA_ "ISignalName" SG_ 955 ASSStsFICM "IASSStsFICM";
BA_ "LongName" SG_ 955 ASSStsFICM "Auto Stop Start Status Ficm";
BA_ "SysSignalName" SG_ 955 ASSStsFICM "ASSStsFICM";
BA_ "CompuMethodName" SG_ 955 EBSBatSOFVol1Sts "EBSBatSOFVol1Sts";
BA_ "GenSigStartValue" SG_ 955 EBSBatSOFVol1Sts 2;
BA_ "ISignalName" SG_ 955 EBSBatSOFVol1Sts "IEBSBatSOFVol1Sts";
BA_ "LongName" SG_ 955 EBSBatSOFVol1Sts "Electronic Battery State Of Function Voltage1 Status";
BA_ "SysSignalName" SG_ 955 EBSBatSOFVol1Sts "EBSBatSOFVol1Sts";
BA_ "CompuMethodName" SG_ 955 GenrExctnDutyCyc "GenrExctnDutyCyc";
BA_ "GenSigStartValue" SG_ 955 GenrExctnDutyCyc 9;
BA_ "ISignalName" SG_ 955 GenrExctnDutyCyc "IGenrExctnDutyCyc";
BA_ "LongName" SG_ 955 GenrExctnDutyCyc "Generator Excitation Duty Cycle";
BA_ "SysSignalName" SG_ 955 GenrExctnDutyCyc "GenrExctnDutyCyc";
BA_ "CompuMethodName" SG_ 955 IACCPreSpdLimtSwReq "IACCPreSpdLimtSwReq";
BA_ "ISignalName" SG_ 955 IACCPreSpdLimtSwReq "IIACCPreSpdLimtSwReq";
BA_ "LongName" SG_ 955 IACCPreSpdLimtSwReq "Intelligent ACC prediction speed limit request";
BA_ "SysSignalName" SG_ 955 IACCPreSpdLimtSwReq "IACCPreSpdLimtSwReq";
BA_ "CompuMethodName" SG_ 955 PMDCIlgclIdficn "PMDCIlgclIdficn";
BA_ "ISignalName" SG_ 955 PMDCIlgclIdficn "IPMDCIlgclIdficn";
BA_ "LongName" SG_ 955 PMDCIlgclIdficn "Power Management Direct Current Converter Illogical Identification";
BA_ "SysSignalName" SG_ 955 PMDCIlgclIdficn "PMDCIlgclIdficn";
BA_ "CompuMethodName" SG_ 955 EBSBatIncnstncyFlag "EBSBatIncnstncyFlag";
BA_ "ISignalName" SG_ 955 EBSBatIncnstncyFlag "IEBSBatIncnstncyFlag";
BA_ "LongName" SG_ 955 EBSBatIncnstncyFlag "Electronic Battery Inconsistency";
BA_ "SysSignalName" SG_ 955 EBSBatIncnstncyFlag "EBSBatIncnstncyFlag";
BA_ "CompuMethodName" SG_ 955 ASSStsFICMV "ASSStsFICMV";
BA_ "GenSigStartValue" SG_ 955 ASSStsFICMV 1;
BA_ "ISignalName" SG_ 955 ASSStsFICMV "IASSStsFICMV";
BA_ "LongName" SG_ 955 ASSStsFICMV "Auto Stop Start Status Ficm Validity";
BA_ "SysSignalName" SG_ 955 ASSStsFICMV "ASSStsFICMV";
BA_ "CompuMethodName" SG_ 955 PMDCIlgclCal "PMDCIlgclCal";
BA_ "ISignalName" SG_ 955 PMDCIlgclCal "IPMDCIlgclCal";
BA_ "LongName" SG_ 955 PMDCIlgclCal "Power Management Direct Current Converter Illogical Calibration";
BA_ "SysSignalName" SG_ 955 PMDCIlgclCal "PMDCIlgclCal";
BA_ "CompuMethodName" SG_ 955 IdleBstLvl "IdleBstLvl";
BA_ "ISignalName" SG_ 955 IdleBstLvl "IIdleBstLvl";
BA_ "LongName" SG_ 955 IdleBstLvl "Idle Boost Level";
BA_ "SysSignalName" SG_ 955 IdleBstLvl "IdleBstLvl";
BA_ "CompuMethodName" SG_ 955 ExtnlTstrDet "ExtnlTstrDet";
BA_ "ISignalName" SG_ 955 ExtnlTstrDet "IExtnlTstrDet";
BA_ "LongName" SG_ 955 ExtnlTstrDet "External_Tester_Detected";
BA_ "SysSignalName" SG_ 955 ExtnlTstrDet "ExtnlTstrDet";
BA_ "CompuMethodName" SG_ 955 TiltSnsrSetngReq "TiltSnsrSetngReq";
BA_ "ISignalName" SG_ 955 TiltSnsrSetngReq "ITiltSnsrSetngReq";
BA_ "LongName" SG_ 955 TiltSnsrSetngReq "Tilt Sensor Setting Request";
BA_ "SysSignalName" SG_ 955 TiltSnsrSetngReq "TiltSnsrSetngReq";
BA_ "CompuMethodName" SG_ 955 RrSsdAppCtrl "RrSsdAppCtrl";
BA_ "ISignalName" SG_ 955 RrSsdAppCtrl "IRrSsdAppCtrl";
BA_ "LongName" SG_ 955 RrSsdAppCtrl "Rear_Sunshade_Application_Control";
BA_ "SysSignalName" SG_ 955 RrSsdAppCtrl "RrSsdAppCtrl";
BA_ "CompuMethodName" SG_ 955 IACCOvTSuppresSwReq "IACCOvTSuppresSwReq";
BA_ "ISignalName" SG_ 955 IACCOvTSuppresSwReq "IIACCOvTSuppresSwReq";
BA_ "LongName" SG_ 955 IACCOvTSuppresSwReq "Intelligent ACC Overtaking Suppres Switch Reqest";
BA_ "SysSignalName" SG_ 955 IACCOvTSuppresSwReq "IACCOvTSuppresSwReq";
BA_ "CompuMethodName" SG_ 955 TrgtSOCReqAI "TrgtSOCReqAI";
BA_ "ISignalName" SG_ 955 TrgtSOCReqAI "ITrgtSOCReqAI";
BA_ "LongName" SG_ 955 TrgtSOCReqAI "Target Soc Request AI";
BA_ "SysSignalName" SG_ 955 TrgtSOCReqAI "TrgtSOCReqAI";
BA_ "CompuMethodName" SG_ 955 DMSHapticWrnngReq "DMSHapticWrnngReq";
BA_ "ISignalName" SG_ 955 DMSHapticWrnngReq "IDMSHapticWrnngReq";
BA_ "LongName" SG_ 955 DMSHapticWrnngReq "Driver Monitor System Haptic Warning Request";
BA_ "SysSignalName" SG_ 955 DMSHapticWrnngReq "DMSHapticWrnngReq";
BA_ "CompuMethodName" SG_ 955 DMSAdoWrnngReq "DMSAdoWrnngReq";
BA_ "ISignalName" SG_ 955 DMSAdoWrnngReq "IDMSAdoWrnngReq";
BA_ "LongName" SG_ 955 DMSAdoWrnngReq "Driver Monitor System Audio Warning Request";
BA_ "SysSignalName" SG_ 955 DMSAdoWrnngReq "DMSAdoWrnngReq";
BA_ "CompuMethodName" SG_ 955 VolmcSnsrSetngReq "VolmcSnsrSetngReq";
BA_ "ISignalName" SG_ 955 VolmcSnsrSetngReq "IVolmcSnsrSetngReq";
BA_ "LongName" SG_ 955 VolmcSnsrSetngReq "Volumetric Sensor Setting Request";
BA_ "SysSignalName" SG_ 955 VolmcSnsrSetngReq "VolmcSnsrSetngReq";
BA_ "CompuMethodName" SG_ 955 DMSDstrctnHptWrnngReq "DMSDstrctnHptWrnngReq";
BA_ "ISignalName" SG_ 955 DMSDstrctnHptWrnngReq "IDMSDstrctnHptWrnngReq";
BA_ "LongName" SG_ 955 DMSDstrctnHptWrnngReq "Driver Monitor System Distraction Haptic Warning Request";
BA_ "SysSignalName" SG_ 955 DMSDstrctnHptWrnngReq "DMSDstrctnHptWrnngReq";
BA_ "CompuMethodName" SG_ 955 DMSDstrctnAdoWrnngReq "DMSDstrctnAdoWrnngReq";
BA_ "ISignalName" SG_ 955 DMSDstrctnAdoWrnngReq "IDMSDstrctnAdoWrnngReq";
BA_ "LongName" SG_ 955 DMSDstrctnAdoWrnngReq "Driver Monitor System Distraction Audio Warning Request";
BA_ "SysSignalName" SG_ 955 DMSDstrctnAdoWrnngReq "DMSDstrctnAdoWrnngReq";
BA_ "CompuMethodName" SG_ 955 DMSDstrctnSwReq "DMSDstrctnSwReq";
BA_ "ISignalName" SG_ 955 DMSDstrctnSwReq "IDMSDstrctnSwReq";
BA_ "LongName" SG_ 955 DMSDstrctnSwReq "Driver Monitor System Distraction Switch Request";
BA_ "SysSignalName" SG_ 955 DMSDstrctnSwReq "DMSDstrctnSwReq";
BA_ "CompuMethodName" SG_ 955 DMSSwReq "DMSSwReq";
BA_ "ISignalName" SG_ 955 DMSSwReq "IDMSSwReq";
BA_ "LongName" SG_ 955 DMSSwReq "Driver Monitor System Switch Request";
BA_ "SysSignalName" SG_ 955 DMSSwReq "DMSSwReq";
BA_ "CompuMethodName" SG_ 955 FICMInnrDschrgReq "FICMInnrDschrgReq";
BA_ "ISignalName" SG_ 955 FICMInnrDschrgReq "IFICMInnrDschrgReq";
BA_ "LongName" SG_ 955 FICMInnrDschrgReq "FICM Inner Discharge Request";
BA_ "SysSignalName" SG_ 955 FICMInnrDschrgReq "FICMInnrDschrgReq";
BA_ "CompuMethodName" SG_ 955 OMSSwReq "OMSSwReq";
BA_ "ISignalName" SG_ 955 OMSSwReq "IOMSSwReq";
BA_ "LongName" SG_ 955 OMSSwReq "Occupant Monitor System Switch Request";
BA_ "SysSignalName" SG_ 955 OMSSwReq "OMSSwReq";
BA_ "CompuMethodName" SG_ 955 TrgtSOCReqAIV "TrgtSOCReqAIV";
BA_ "GenSigStartValue" SG_ 955 TrgtSOCReqAIV 1;
BA_ "ISignalName" SG_ 955 TrgtSOCReqAIV "ITrgtSOCReqAIV";
BA_ "LongName" SG_ 955 TrgtSOCReqAIV "Target Soc Request AI Validity";
BA_ "SysSignalName" SG_ 955 TrgtSOCReqAIV "TrgtSOCReqAIV";
BA_ "CompuMethodName" SG_ 955 OMSBabyCareReq "OMSBabyCareReq";
BA_ "ISignalName" SG_ 955 OMSBabyCareReq "IOMSBabyCareReq";
BA_ "LongName" SG_ 955 OMSBabyCareReq "Occupant Monitor System Baby Care Request";
BA_ "SysSignalName" SG_ 955 OMSBabyCareReq "OMSBabyCareReq";
BA_ "CompuMethodName" SG_ 955 OmsGesDetSwReq "OmsGesDetSwReq";
BA_ "ISignalName" SG_ 955 OmsGesDetSwReq "IOmsGesDetSwReq";
BA_ "LongName" SG_ 955 OmsGesDetSwReq "Occupant Monitor System Gesture Detect Switch Request";
BA_ "SysSignalName" SG_ 955 OmsGesDetSwReq "OmsGesDetSwReq";
BA_ "CompuMethodName" SG_ 955 OmsIlbRemSwReq "OmsIlbRemSwReq";
BA_ "ISignalName" SG_ 955 OmsIlbRemSwReq "IOmsIlbRemSwReq";
BA_ "LongName" SG_ 955 OmsIlbRemSwReq "Occupant Monitor Item Left Behind Reminder Switch Request";
BA_ "SysSignalName" SG_ 955 OmsIlbRemSwReq "OmsIlbRemSwReq";
BA_ "CompuMethodName" SG_ 955 AIParkngSSPLotSw "AIParkngSSPLotSw";
BA_ "ISignalName" SG_ 955 AIParkngSSPLotSw "IAIParkngSSPLotSw";
BA_ "LongName" SG_ 955 AIParkngSSPLotSw "Ai Parking Silent Search Parking Slot Switch Set";
BA_ "SysSignalName" SG_ 955 AIParkngSSPLotSw "AIParkngSSPLotSw";
BA_ "CompuMethodName" SG_ 955 TakeKeyOutRmndrPersSetReq "TakeKeyOutRmndrPersSetReq";
BA_ "ISignalName" SG_ 955 TakeKeyOutRmndrPersSetReq "ITakeKeyOutRmndrPersSetReq";
BA_ "LongName" SG_ 955 TakeKeyOutRmndrPersSetReq "Take Key Out Reminder Personalization Setting Request";
BA_ "SysSignalName" SG_ 955 TakeKeyOutRmndrPersSetReq "TakeKeyOutRmndrPersSetReq";
BA_ "CompuMethodName" SG_ 955 CmftUnlckPersSetReq "CmftUnlckPersSetReq";
BA_ "ISignalName" SG_ 955 CmftUnlckPersSetReq "ICmftUnlckPersSetReq";
BA_ "LongName" SG_ 955 CmftUnlckPersSetReq "Comfort Unlock Personalization Setting Request";
BA_ "SysSignalName" SG_ 955 CmftUnlckPersSetReq "CmftUnlckPersSetReq";
BA_ "CompuMethodName" SG_ 955 CmftLckPersSetReq "CmftLckPersSetReq";
BA_ "ISignalName" SG_ 955 CmftLckPersSetReq "ICmftLckPersSetReq";
BA_ "LongName" SG_ 955 CmftLckPersSetReq "Comfort Lock Personalization Setting Request";
BA_ "SysSignalName" SG_ 955 CmftLckPersSetReq "CmftLckPersSetReq";
BA_ "CompuMethodName" SG_ 746 FCTSysSelReq "FCTSysSelReq";
BA_ "ISignalName" SG_ 746 FCTSysSelReq "IFCTSysSelReq";
BA_ "LongName" SG_ 746 FCTSysSelReq "FCTA/B Switch Select Request";
BA_ "SysSignalName" SG_ 746 FCTSysSelReq "FCTSysSelReq";
BA_ "CompuMethodName" SG_ 1297 NavCtryCode_ISO "NavCtryCode_ISO";
BA_ "ISignalName" SG_ 1297 NavCtryCode_ISO "INavCtryCode_ISO";
BA_ "LongName" SG_ 1297 NavCtryCode_ISO "Navigation Country Code iso";
BA_ "SysSignalName" SG_ 1297 NavCtryCode_ISO "NavCtryCode_ISO";
BA_ "CompuMethodName" SG_ 368 ICBVC_50ms_Group158_CRC "ICBVC_50ms_Group158_CRC";
BA_ "ISignalName" SG_ 368 ICBVC_50ms_Group158_CRC "IICBVC_50ms_Group158_CRC";
BA_ "SysSignalName" SG_ 368 ICBVC_50ms_Group158_CRC "ICBVC_50ms_Group158_CRC";
BA_ "CompuMethodName" SG_ 368 ICBVC_50ms_Group158_RC "ICBVC_50ms_Group158_RC";
BA_ "ISignalName" SG_ 368 ICBVC_50ms_Group158_RC "IICBVC_50ms_Group158_RC";
BA_ "SysSignalName" SG_ 368 ICBVC_50ms_Group158_RC "ICBVC_50ms_Group158_RC";
BA_ "CompuMethodName" SG_ 368 CCSpdDecAndIncVcCmd "CCSpdDecAndIncVcCmd";
BA_ "ISignalName" SG_ 368 CCSpdDecAndIncVcCmd "ICCSpdDecAndIncVcCmd";
BA_ "LongName" SG_ 368 CCSpdDecAndIncVcCmd "Cruise_Control_Speed_Decrease_And_Increase_Voice_Command";
BA_ "SysSignalName" SG_ 368 CCSpdDecAndIncVcCmd "CCSpdDecAndIncVcCmd";
BA_ "CompuMethodName" SG_ 368 CCDisDecAndIncVcCmd "CCDisDecAndIncVcCmd";
BA_ "ISignalName" SG_ 368 CCDisDecAndIncVcCmd "ICCDisDecAndIncVcCmd";
BA_ "LongName" SG_ 368 CCDisDecAndIncVcCmd "Cruise_Control_Distance_Decrease_And_Increase_Voice_Command";
BA_ "SysSignalName" SG_ 368 CCDisDecAndIncVcCmd "CCDisDecAndIncVcCmd";
BA_ "CompuMethodName" SG_ 368 ICBVC_50ms_Group158_Reserved1 "ICBVC_50ms_Group158_Reserved1";
BA_ "GenSigStartValue" SG_ 368 ICBVC_50ms_Group158_Reserved1 15;
BA_ "ISignalName" SG_ 368 ICBVC_50ms_Group158_Reserved1 "IICBVC_50ms_Group158_Reserved1";
BA_ "SysSignalName" SG_ 368 ICBVC_50ms_Group158_Reserved1 "ICBVC_50ms_Group158_Reserved1";
BA_ "CompuMethodName" SG_ 368 CCSwStsSetSwA "CCSwStsSetSwA";
BA_ "ISignalName" SG_ 368 CCSwStsSetSwA "ICCSwStsSetSwA";
BA_ "LongName" SG_ 368 CCSwStsSetSwA "Cruise Control Switch Status Set Switch Active";
BA_ "SysSignalName" SG_ 368 CCSwStsSetSwA "CCSwStsSetSwA";
BA_ "CompuMethodName" SG_ 368 CCSwStsCCASwA "CCSwStsCCASwA";
BA_ "ISignalName" SG_ 368 CCSwStsCCASwA "ICCSwStsCCASwA";
BA_ "LongName" SG_ 368 CCSwStsCCASwA "Cruise_Control_Switch_Status_Cruise_Control_Active_Switch_Active";
BA_ "SysSignalName" SG_ 368 CCSwStsCCASwA "CCSwStsCCASwA";
BA_ "CompuMethodName" SG_ 368 CCSpdVcCmdSwReq "CCSpdVcCmdSwReq";
BA_ "ISignalName" SG_ 368 CCSpdVcCmdSwReq "ICCSpdVcCmdSwReq";
BA_ "LongName" SG_ 368 CCSpdVcCmdSwReq "Cruise_Control_Speed_Voice_Command_Switch_Request";
BA_ "SysSignalName" SG_ 368 CCSpdVcCmdSwReq "CCSpdVcCmdSwReq";
BA_ "CompuMethodName" SG_ 368 CCSpdVcCmd "CCSpdVcCmd";
BA_ "ISignalName" SG_ 368 CCSpdVcCmd "ICCSpdVcCmd";
BA_ "LongName" SG_ 368 CCSpdVcCmd "Cruise_Control_Speed_Voice_Command";
BA_ "SysSignalName" SG_ 368 CCSpdVcCmd "CCSpdVcCmd";
BA_ "CompuMethodName" SG_ 368 ICBVC_50ms_Group158_Reserved2 "ICBVC_50ms_Group158_Reserved2";
BA_ "GenSigStartValue" SG_ 368 ICBVC_50ms_Group158_Reserved2 255;
BA_ "ISignalName" SG_ 368 ICBVC_50ms_Group158_Reserved2 "IICBVC_50ms_Group158_Reserved2";
BA_ "SysSignalName" SG_ 368 ICBVC_50ms_Group158_Reserved2 "ICBVC_50ms_Group158_Reserved2";
BA_ "CompuMethodName" SG_ 368 ICBVC_50ms_Group158_Reserved3 "ICBVC_50ms_Group158_Reserved3";
BA_ "GenSigStartValue" SG_ 368 ICBVC_50ms_Group158_Reserved3 31;
BA_ "ISignalName" SG_ 368 ICBVC_50ms_Group158_Reserved3 "IICBVC_50ms_Group158_Reserved3";
BA_ "SysSignalName" SG_ 368 ICBVC_50ms_Group158_Reserved3 "ICBVC_50ms_Group158_Reserved3";
BA_ "CompuMethodName" SG_ 368 CCDisAdjtVcCmd "CCDisAdjtVcCmd";
BA_ "ISignalName" SG_ 368 CCDisAdjtVcCmd "ICCDisAdjtVcCmd";
BA_ "LongName" SG_ 368 CCDisAdjtVcCmd "Cruise_Control_Distance_Adjust_Voice_Command";
BA_ "SysSignalName" SG_ 368 CCDisAdjtVcCmd "CCDisAdjtVcCmd";
BA_ "CompuMethodName" SG_ 368 ICBVC_50ms_Group158_Reserved4 "ICBVC_50ms_Group158_Reserved4";
BA_ "GenSigStartValue" SG_ 368 ICBVC_50ms_Group158_Reserved4 255;
BA_ "ISignalName" SG_ 368 ICBVC_50ms_Group158_Reserved4 "IICBVC_50ms_Group158_Reserved4";
BA_ "SysSignalName" SG_ 368 ICBVC_50ms_Group158_Reserved4 "ICBVC_50ms_Group158_Reserved4";
BA_ "CompuMethodName" SG_ 368 ICBVC_50ms_Group158_Reserved5 "ICBVC_50ms_Group158_Reserved5";
BA_ "GenSigStartValue" SG_ 368 ICBVC_50ms_Group158_Reserved5 255;
BA_ "ISignalName" SG_ 368 ICBVC_50ms_Group158_Reserved5 "IICBVC_50ms_Group158_Reserved5";
BA_ "SysSignalName" SG_ 368 ICBVC_50ms_Group158_Reserved5 "ICBVC_50ms_Group158_Reserved5";
BA_ "CompuMethodName" SG_ 368 ICBVC_50ms_Group158_Reserved6 "ICBVC_50ms_Group158_Reserved6";
BA_ "GenSigStartValue" SG_ 368 ICBVC_50ms_Group158_Reserved6 255;
BA_ "ISignalName" SG_ 368 ICBVC_50ms_Group158_Reserved6 "IICBVC_50ms_Group158_Reserved6";
BA_ "SysSignalName" SG_ 368 ICBVC_50ms_Group158_Reserved6 "ICBVC_50ms_Group158_Reserved6";
BA_ "CompuMethodName" SG_ 368 ICBVC_50ms_Group158_Reserved7 "ICBVC_50ms_Group158_Reserved7";
BA_ "GenSigStartValue" SG_ 368 ICBVC_50ms_Group158_Reserved7 255;
BA_ "ISignalName" SG_ 368 ICBVC_50ms_Group158_Reserved7 "IICBVC_50ms_Group158_Reserved7";
BA_ "SysSignalName" SG_ 368 ICBVC_50ms_Group158_Reserved7 "ICBVC_50ms_Group158_Reserved7";
BA_ "CompuMethodName" SG_ 368 ICBVC_50ms_Group158_Reserved8 "ICBVC_50ms_Group158_Reserved8";
BA_ "GenSigStartValue" SG_ 368 ICBVC_50ms_Group158_Reserved8 255;
BA_ "ISignalName" SG_ 368 ICBVC_50ms_Group158_Reserved8 "IICBVC_50ms_Group158_Reserved8";
BA_ "SysSignalName" SG_ 368 ICBVC_50ms_Group158_Reserved8 "ICBVC_50ms_Group158_Reserved8";
BA_ "CompuMethodName" SG_ 368 ICBVC_50ms_Group158_Reserved9 "ICBVC_50ms_Group158_Reserved9";
BA_ "GenSigStartValue" SG_ 368 ICBVC_50ms_Group158_Reserved9 255;
BA_ "ISignalName" SG_ 368 ICBVC_50ms_Group158_Reserved9 "IICBVC_50ms_Group158_Reserved9";
BA_ "SysSignalName" SG_ 368 ICBVC_50ms_Group158_Reserved9 "ICBVC_50ms_Group158_Reserved9";
BA_ "CompuMethodName" SG_ 368 ICBVC_50ms_Group158_Reserved10 "ICBVC_50ms_Group158_Reserved10";
BA_ "GenSigStartValue" SG_ 368 ICBVC_50ms_Group158_Reserved10 255;
BA_ "ISignalName" SG_ 368 ICBVC_50ms_Group158_Reserved10 "IICBVC_50ms_Group158_Reserved10";
BA_ "SysSignalName" SG_ 368 ICBVC_50ms_Group158_Reserved10 "ICBVC_50ms_Group158_Reserved10";
BA_ "CompuMethodName" SG_ 368 ICBVC_50ms_Group158_Reserved11 "ICBVC_50ms_Group158_Reserved11";
BA_ "GenSigStartValue" SG_ 368 ICBVC_50ms_Group158_Reserved11 255;
BA_ "ISignalName" SG_ 368 ICBVC_50ms_Group158_Reserved11 "IICBVC_50ms_Group158_Reserved11";
BA_ "SysSignalName" SG_ 368 ICBVC_50ms_Group158_Reserved11 "ICBVC_50ms_Group158_Reserved11";
BA_ "CompuMethodName" SG_ 368 ICBVC_50ms_Group158_Reserved12 "ICBVC_50ms_Group158_Reserved12";
BA_ "GenSigStartValue" SG_ 368 ICBVC_50ms_Group158_Reserved12 255;
BA_ "ISignalName" SG_ 368 ICBVC_50ms_Group158_Reserved12 "IICBVC_50ms_Group158_Reserved12";
BA_ "SysSignalName" SG_ 368 ICBVC_50ms_Group158_Reserved12 "ICBVC_50ms_Group158_Reserved12";
BA_ "CompuMethodName" SG_ 368 ICBVC_50ms_Group158_Reserved13 "ICBVC_50ms_Group158_Reserved13";
BA_ "GenSigStartValue" SG_ 368 ICBVC_50ms_Group158_Reserved13 255;
BA_ "ISignalName" SG_ 368 ICBVC_50ms_Group158_Reserved13 "IICBVC_50ms_Group158_Reserved13";
BA_ "SysSignalName" SG_ 368 ICBVC_50ms_Group158_Reserved13 "ICBVC_50ms_Group158_Reserved13";
BA_ "CompuMethodName" SG_ 1389 IdentityChlg "IdentityChlg";
BA_ "ISignalName" SG_ 1389 IdentityChlg "IIdentityChlg";
BA_ "LongName" SG_ 1389 IdentityChlg "Identification Challenge";
BA_ "SysSignalName" SG_ 1389 IdentityChlg "IdentityChlg";
BA_ "CompuMethodName" SG_ 1111 ICCPCBTemp1 "ICCPCBTemp1";
BA_ "GenSigStartValue" SG_ 1111 ICCPCBTemp1 255;
BA_ "ISignalName" SG_ 1111 ICCPCBTemp1 "IICCPCBTemp1";
BA_ "LongName" SG_ 1111 ICCPCBTemp1 "ICC PCB Temperature 1";
BA_ "SysSignalName" SG_ 1111 ICCPCBTemp1 "ICCPCBTemp1";
BA_ "CompuMethodName" SG_ 1111 ICCPCBTemp2 "ICCPCBTemp2";
BA_ "GenSigStartValue" SG_ 1111 ICCPCBTemp2 255;
BA_ "ISignalName" SG_ 1111 ICCPCBTemp2 "IICCPCBTemp2";
BA_ "LongName" SG_ 1111 ICCPCBTemp2 "ICC PCB Temperature 2";
BA_ "SysSignalName" SG_ 1111 ICCPCBTemp2 "ICCPCBTemp2";
BA_ "CompuMethodName" SG_ 1111 ICCPCBTemp3 "ICCPCBTemp3";
BA_ "GenSigStartValue" SG_ 1111 ICCPCBTemp3 255;
BA_ "ISignalName" SG_ 1111 ICCPCBTemp3 "IICCPCBTemp3";
BA_ "LongName" SG_ 1111 ICCPCBTemp3 "ICC PCB Temperature 3";
BA_ "SysSignalName" SG_ 1111 ICCPCBTemp3 "ICCPCBTemp3";
BA_ "CompuMethodName" SG_ 1111 ICCPCBTemp4 "ICCPCBTemp4";
BA_ "GenSigStartValue" SG_ 1111 ICCPCBTemp4 255;
BA_ "ISignalName" SG_ 1111 ICCPCBTemp4 "IICCPCBTemp4";
BA_ "LongName" SG_ 1111 ICCPCBTemp4 "ICC PCB Temperature 4";
BA_ "SysSignalName" SG_ 1111 ICCPCBTemp4 "ICCPCBTemp4";
BA_ "CompuMethodName" SG_ 1111 ICCPCBTemp5 "ICCPCBTemp5";
BA_ "GenSigStartValue" SG_ 1111 ICCPCBTemp5 255;
BA_ "ISignalName" SG_ 1111 ICCPCBTemp5 "IICCPCBTemp5";
BA_ "LongName" SG_ 1111 ICCPCBTemp5 "ICC PCB Temperature 5";
BA_ "SysSignalName" SG_ 1111 ICCPCBTemp5 "ICCPCBTemp5";
BA_ "CompuMethodName" SG_ 1111 ICCThermalCoolingLvl "ICCThermalCoolingLvl";
BA_ "GenSigStartValue" SG_ 1111 ICCThermalCoolingLvl 1;
BA_ "ISignalName" SG_ 1111 ICCThermalCoolingLvl "IICCThermalCoolingLvl";
BA_ "LongName" SG_ 1111 ICCThermalCoolingLvl "ICC Thermal Cooling Level";
BA_ "SysSignalName" SG_ 1111 ICCThermalCoolingLvl "ICCThermalCoolingLvl";
BA_ "CompuMethodName" SG_ 1111 FICMV2XEnEnbReq "FICMV2XEnEnbReq";
BA_ "ISignalName" SG_ 1111 FICMV2XEnEnbReq "IFICMV2XEnEnbReq";
BA_ "LongName" SG_ 1111 FICMV2XEnEnbReq "Front Infotainment Control Module V2x Engine Enable Request";
BA_ "SysSignalName" SG_ 1111 FICMV2XEnEnbReq "FICMV2XEnEnbReq";
BA_ "CompuMethodName" SG_ 1111 ElecPwrDistbnScene "ElecPwrDistbnScene";
BA_ "ISignalName" SG_ 1111 ElecPwrDistbnScene "IElecPwrDistbnScene";
BA_ "LongName" SG_ 1111 ElecPwrDistbnScene "Electric Power Distribution Scene";
BA_ "SysSignalName" SG_ 1111 ElecPwrDistbnScene "ElecPwrDistbnScene";
BA_ "CompuMethodName" SG_ 1111 AltngChrgCrntReq "AltngChrgCrntReq";
BA_ "GenSigStartValue" SG_ 1111 AltngChrgCrntReq 32;
BA_ "ISignalName" SG_ 1111 AltngChrgCrntReq "IAltngChrgCrntReq";
BA_ "LongName" SG_ 1111 AltngChrgCrntReq "Alternating Charge Current Request";
BA_ "SysSignalName" SG_ 1111 AltngChrgCrntReq "AltngChrgCrntReq";
BA_ "CompuMethodName" SG_ 1111 DschrgTrgtSOCVal "DschrgTrgtSOCVal";
BA_ "ISignalName" SG_ 1111 DschrgTrgtSOCVal "IDschrgTrgtSOCVal";
BA_ "LongName" SG_ 1111 DschrgTrgtSOCVal "DisCharge Target State Of Charge Value";
BA_ "SysSignalName" SG_ 1111 DschrgTrgtSOCVal "DschrgTrgtSOCVal";
BA_ "CompuMethodName" SG_ 527 IMM_50ms_Group02_CRC "IMM_50ms_Group02_CRC";
BA_ "ISignalName" SG_ 527 IMM_50ms_Group02_CRC "IIMM_50ms_Group02_CRC";
BA_ "LongName" SG_ 527 IMM_50ms_Group02_CRC "Driver Monitor System Audio Warning Display Command_IMM";
BA_ "SysSignalName" SG_ 527 IMM_50ms_Group02_CRC "IMM_50ms_Group02_CRC";
BA_ "CompuMethodName" SG_ 527 IMM_50ms_Group02_RC "IMM_50ms_Group02_RC";
BA_ "ISignalName" SG_ 527 IMM_50ms_Group02_RC "IIMM_50ms_Group02_RC";
BA_ "LongName" SG_ 527 IMM_50ms_Group02_RC "Driver Monitor System Audible Request_IMM";
BA_ "SysSignalName" SG_ 527 IMM_50ms_Group02_RC "IMM_50ms_Group02_RC";
BA_ "CompuMethodName" SG_ 527 IMM_50ms_Group02_Reserved1 "IMM_50ms_Group02_Reserved1";
BA_ "GenSigStartValue" SG_ 527 IMM_50ms_Group02_Reserved1 15;
BA_ "ISignalName" SG_ 527 IMM_50ms_Group02_Reserved1 "IIMM_50ms_Group02_Reserved1";
BA_ "SysSignalName" SG_ 527 IMM_50ms_Group02_Reserved1 "IMM_50ms_Group02_Reserved1";
BA_ "CompuMethodName" SG_ 527 DrvrDstcnStsINST_IMM "DrvrDstcnStsINST_IMM";
BA_ "ISignalName" SG_ 527 DrvrDstcnStsINST_IMM "IDrvrDstcnStsINST_IMM";
BA_ "LongName" SG_ 527 DrvrDstcnStsINST_IMM "Driver Distraction Status Instantaneous_IMM";
BA_ "SysSignalName" SG_ 527 DrvrDstcnStsINST_IMM "DrvrDstcnStsINST_IMM";
BA_ "CompuMethodName" SG_ 527 ILBRReq_IMM "ILBRReq_IMM";
BA_ "ISignalName" SG_ 527 ILBRReq_IMM "IILBRReq_IMM";
BA_ "LongName" SG_ 527 ILBRReq_IMM "Item Left Behind Reminder_IMM";
BA_ "SysSignalName" SG_ 527 ILBRReq_IMM "ILBRReq_IMM";
BA_ "CompuMethodName" SG_ 527 DrvrAbnormBehvor_IMM "DrvrAbnormBehvor_IMM";
BA_ "ISignalName" SG_ 527 DrvrAbnormBehvor_IMM "IDrvrAbnormBehvor_IMM";
BA_ "LongName" SG_ 527 DrvrAbnormBehvor_IMM "Driver Abnormal Behaviour_IMM";
BA_ "SysSignalName" SG_ 527 DrvrAbnormBehvor_IMM "DrvrAbnormBehvor_IMM";
BA_ "CompuMethodName" SG_ 527 DMSSts_IMM "DMSSts_IMM";
BA_ "ISignalName" SG_ 527 DMSSts_IMM "IDMSSts_IMM";
BA_ "LongName" SG_ 527 DMSSts_IMM "Driver Monitor System Status_IMM";
BA_ "SysSignalName" SG_ 527 DMSSts_IMM "DMSSts_IMM";
BA_ "CompuMethodName" SG_ 527 IMM_50ms_Group02_Reserved2 "IMM_50ms_Group02_Reserved2";
BA_ "GenSigStartValue" SG_ 527 IMM_50ms_Group02_Reserved2 3;
BA_ "ISignalName" SG_ 527 IMM_50ms_Group02_Reserved2 "IIMM_50ms_Group02_Reserved2";
BA_ "SysSignalName" SG_ 527 IMM_50ms_Group02_Reserved2 "IMM_50ms_Group02_Reserved2";
BA_ "CompuMethodName" SG_ 527 SpfngDet_IMM "SpfngDet_IMM";
BA_ "ISignalName" SG_ 527 SpfngDet_IMM "ISpfngDet_IMM";
BA_ "LongName" SG_ 527 SpfngDet_IMM "Spoofing Detected_IMM";
BA_ "SysSignalName" SG_ 527 SpfngDet_IMM "SpfngDet_IMM";
BA_ "CompuMethodName" SG_ 527 DrvrDstcnSts_IMM "DrvrDstcnSts_IMM";
BA_ "ISignalName" SG_ 527 DrvrDstcnSts_IMM "IDrvrDstcnSts_IMM";
BA_ "LongName" SG_ 527 DrvrDstcnSts_IMM "Driver Distraction Status_IMM";
BA_ "SysSignalName" SG_ 527 DrvrDstcnSts_IMM "DrvrDstcnSts_IMM";
BA_ "CompuMethodName" SG_ 527 OMSSts_IMM "OMSSts_IMM";
BA_ "ISignalName" SG_ 527 OMSSts_IMM "IOMSSts_IMM";
BA_ "LongName" SG_ 527 OMSSts_IMM "Occupant Monitor System Status_IMM";
BA_ "SysSignalName" SG_ 527 OMSSts_IMM "OMSSts_IMM";
BA_ "CompuMethodName" SG_ 527 DrvrFtgLvlINST_IMM "DrvrFtgLvlINST_IMM";
BA_ "ISignalName" SG_ 527 DrvrFtgLvlINST_IMM "IDrvrFtgLvlINST_IMM";
BA_ "LongName" SG_ 527 DrvrFtgLvlINST_IMM "Driver Fatigue Level Instantaneous_IMM";
BA_ "SysSignalName" SG_ 527 DrvrFtgLvlINST_IMM "DrvrFtgLvlINST_IMM";
BA_ "CompuMethodName" SG_ 527 IMM_50ms_Group02_Reserved3 "IMM_50ms_Group02_Reserved3";
BA_ "GenSigStartValue" SG_ 527 IMM_50ms_Group02_Reserved3 7;
BA_ "ISignalName" SG_ 527 IMM_50ms_Group02_Reserved3 "IIMM_50ms_Group02_Reserved3";
BA_ "SysSignalName" SG_ 527 IMM_50ms_Group02_Reserved3 "IMM_50ms_Group02_Reserved3";
BA_ "CompuMethodName" SG_ 527 DrvrFtgLvl_IMM "DrvrFtgLvl_IMM";
BA_ "ISignalName" SG_ 527 DrvrFtgLvl_IMM "IDrvrFtgLvl_IMM";
BA_ "LongName" SG_ 527 DrvrFtgLvl_IMM "Driver Fatigue Level_IMM";
BA_ "SysSignalName" SG_ 527 DrvrFtgLvl_IMM "DrvrFtgLvl_IMM";
BA_ "CompuMethodName" SG_ 527 DrvrPrst_IMM "DrvrPrst_IMM";
BA_ "ISignalName" SG_ 527 DrvrPrst_IMM "IDrvrPrst_IMM";
BA_ "LongName" SG_ 527 DrvrPrst_IMM "Driver Present_IMM";
BA_ "SysSignalName" SG_ 527 DrvrPrst_IMM "DrvrPrst_IMM";
BA_ "CompuMethodName" SG_ 527 DrvrGazeRgn_IMM "DrvrGazeRgn_IMM";
BA_ "ISignalName" SG_ 527 DrvrGazeRgn_IMM "IDrvrGazeRgn_IMM";
BA_ "LongName" SG_ 527 DrvrGazeRgn_IMM "Driver Gaze Region_IMM";
BA_ "SysSignalName" SG_ 527 DrvrGazeRgn_IMM "DrvrGazeRgn_IMM";
BA_ "CompuMethodName" SG_ 527 IMM_50ms_Group02_Reserved4 "IMM_50ms_Group02_Reserved4";
BA_ "GenSigStartValue" SG_ 527 IMM_50ms_Group02_Reserved4 255;
BA_ "ISignalName" SG_ 527 IMM_50ms_Group02_Reserved4 "IIMM_50ms_Group02_Reserved4";
BA_ "SysSignalName" SG_ 527 IMM_50ms_Group02_Reserved4 "IMM_50ms_Group02_Reserved4";
BA_ "CompuMethodName" SG_ 527 EyeOpenStatus_IMM "EyeOpenStatus_IMM";
BA_ "ISignalName" SG_ 527 EyeOpenStatus_IMM "IEyeOpenStatus_IMM";
BA_ "LongName" SG_ 527 EyeOpenStatus_IMM "Eye Open Status_IMM";
BA_ "SysSignalName" SG_ 527 EyeOpenStatus_IMM "EyeOpenStatus_IMM";
BA_ "CompuMethodName" SG_ 527 IMM_50ms_Group02_Reserved5 "IMM_50ms_Group02_Reserved5";
BA_ "GenSigStartValue" SG_ 527 IMM_50ms_Group02_Reserved5 63;
BA_ "ISignalName" SG_ 527 IMM_50ms_Group02_Reserved5 "IIMM_50ms_Group02_Reserved5";
BA_ "SysSignalName" SG_ 527 IMM_50ms_Group02_Reserved5 "IMM_50ms_Group02_Reserved5";
BA_ "CompuMethodName" SG_ 527 IMM_50ms_Group02_Reserved6 "IMM_50ms_Group02_Reserved6";
BA_ "GenSigStartValue" SG_ 527 IMM_50ms_Group02_Reserved6 1;
BA_ "ISignalName" SG_ 527 IMM_50ms_Group02_Reserved6 "IIMM_50ms_Group02_Reserved6";
BA_ "SysSignalName" SG_ 527 IMM_50ms_Group02_Reserved6 "IMM_50ms_Group02_Reserved6";
BA_ "CompuMethodName" SG_ 527 RightEyeOccludeStatus_IMM "RightEyeOccludeStatus_IMM";
BA_ "ISignalName" SG_ 527 RightEyeOccludeStatus_IMM "IRightEyeOccludeStatus_IMM";
BA_ "LongName" SG_ 527 RightEyeOccludeStatus_IMM "Right Eye Occlude Status_IMM";
BA_ "SysSignalName" SG_ 527 RightEyeOccludeStatus_IMM "RightEyeOccludeStatus_IMM";
BA_ "CompuMethodName" SG_ 527 LeftEyeOccludeStatus_IMM "LeftEyeOccludeStatus_IMM";
BA_ "ISignalName" SG_ 527 LeftEyeOccludeStatus_IMM "ILeftEyeOccludeStatus_IMM";
BA_ "LongName" SG_ 527 LeftEyeOccludeStatus_IMM "Left Eye Occlude Status_IMM";
BA_ "SysSignalName" SG_ 527 LeftEyeOccludeStatus_IMM "LeftEyeOccludeStatus_IMM";
BA_ "CompuMethodName" SG_ 527 EyeOnRoad_IMM "EyeOnRoad_IMM";
BA_ "ISignalName" SG_ 527 EyeOnRoad_IMM "IEyeOnRoad_IMM";
BA_ "LongName" SG_ 527 EyeOnRoad_IMM "Eye On Road_IMM";
BA_ "SysSignalName" SG_ 527 EyeOnRoad_IMM "EyeOnRoad_IMM";
BA_ "CompuMethodName" SG_ 527 DrvrFtgConf_IMM "DrvrFtgConf_IMM";
BA_ "ISignalName" SG_ 527 DrvrFtgConf_IMM "IDrvrFtgConf_IMM";
BA_ "LongName" SG_ 527 DrvrFtgConf_IMM "Driver Fatigue Confidence_IMM";
BA_ "SysSignalName" SG_ 527 DrvrFtgConf_IMM "DrvrFtgConf_IMM";
BA_ "CompuMethodName" SG_ 527 DrvrDstcnConf_IMM "DrvrDstcnConf_IMM";
BA_ "ISignalName" SG_ 527 DrvrDstcnConf_IMM "IDrvrDstcnConf_IMM";
BA_ "LongName" SG_ 527 DrvrDstcnConf_IMM "Driver Distraction Confidence_IMM";
BA_ "SysSignalName" SG_ 527 DrvrDstcnConf_IMM "DrvrDstcnConf_IMM";
BA_ "CompuMethodName" SG_ 527 DrvrAbnormConf_IMM "DrvrAbnormConf_IMM";
BA_ "ISignalName" SG_ 527 DrvrAbnormConf_IMM "IDrvrAbnormConf_IMM";
BA_ "LongName" SG_ 527 DrvrAbnormConf_IMM "Driver Abnormal Confidence_IMM";
BA_ "SysSignalName" SG_ 527 DrvrAbnormConf_IMM "DrvrAbnormConf_IMM";
BA_ "CompuMethodName" SG_ 527 EyeGazepitch_IMM "EyeGazepitch_IMM";
BA_ "ISignalName" SG_ 527 EyeGazepitch_IMM "IEyeGazepitch_IMM";
BA_ "LongName" SG_ 527 EyeGazepitch_IMM "Eye Gaze pitch_IMM";
BA_ "SysSignalName" SG_ 527 EyeGazepitch_IMM "EyeGazepitch_IMM";
BA_ "CompuMethodName" SG_ 527 EyeGazeyaw_IMM "EyeGazeyaw_IMM";
BA_ "ISignalName" SG_ 527 EyeGazeyaw_IMM "IEyeGazeyaw_IMM";
BA_ "LongName" SG_ 527 EyeGazeyaw_IMM "Eye Gaze yaw_IMM";
BA_ "SysSignalName" SG_ 527 EyeGazeyaw_IMM "EyeGazeyaw_IMM";
BA_ "CompuMethodName" SG_ 527 EyeOpenDegree_IMM "EyeOpenDegree_IMM";
BA_ "ISignalName" SG_ 527 EyeOpenDegree_IMM "IEyeOpenDegree_IMM";
BA_ "LongName" SG_ 527 EyeOpenDegree_IMM "Eye Open Degree_IMM";
BA_ "SysSignalName" SG_ 527 EyeOpenDegree_IMM "EyeOpenDegree_IMM";
BA_ "CompuMethodName" SG_ 527 IMM_50ms_Group02_Reserved143 "IMM_50ms_Group02_Reserved143";
BA_ "GenSigStartValue" SG_ 527 IMM_50ms_Group02_Reserved143 255;
BA_ "ISignalName" SG_ 527 IMM_50ms_Group02_Reserved143 "IIMM_50ms_Group02_Reserved143";
BA_ "SysSignalName" SG_ 527 IMM_50ms_Group02_Reserved143 "IMM_50ms_Group02_Reserved143";
BA_ "CompuMethodName" SG_ 527 IMM_50ms_Group02_Reserved151 "IMM_50ms_Group02_Reserved151";
BA_ "GenSigStartValue" SG_ 527 IMM_50ms_Group02_Reserved151 255;
BA_ "ISignalName" SG_ 527 IMM_50ms_Group02_Reserved151 "IIMM_50ms_Group02_Reserved151";
BA_ "SysSignalName" SG_ 527 IMM_50ms_Group02_Reserved151 "IMM_50ms_Group02_Reserved151";
BA_ "CompuMethodName" SG_ 527 IMM_50ms_Group02_Reserved159 "IMM_50ms_Group02_Reserved159";
BA_ "GenSigStartValue" SG_ 527 IMM_50ms_Group02_Reserved159 255;
BA_ "ISignalName" SG_ 527 IMM_50ms_Group02_Reserved159 "IIMM_50ms_Group02_Reserved159";
BA_ "SysSignalName" SG_ 527 IMM_50ms_Group02_Reserved159 "IMM_50ms_Group02_Reserved159";
BA_ "CompuMethodName" SG_ 527 IMM_50ms_Group02_Reserved7 "IMM_50ms_Group02_Reserved7";
BA_ "GenSigStartValue" SG_ 527 IMM_50ms_Group02_Reserved7 15;
BA_ "ISignalName" SG_ 527 IMM_50ms_Group02_Reserved7 "IIMM_50ms_Group02_Reserved7";
BA_ "SysSignalName" SG_ 527 IMM_50ms_Group02_Reserved7 "IMM_50ms_Group02_Reserved7";
BA_ "CompuMethodName" SG_ 527 MouthOccludeStatus_IMM "MouthOccludeStatus_IMM";
BA_ "ISignalName" SG_ 527 MouthOccludeStatus_IMM "IMouthOccludeStatus_IMM";
BA_ "LongName" SG_ 527 MouthOccludeStatus_IMM "Mouth Occlude Status_IMM";
BA_ "SysSignalName" SG_ 527 MouthOccludeStatus_IMM "MouthOccludeStatus_IMM";
BA_ "CompuMethodName" SG_ 527 YawnStatus_IMM "YawnStatus_IMM";
BA_ "ISignalName" SG_ 527 YawnStatus_IMM "IYawnStatus_IMM";
BA_ "LongName" SG_ 527 YawnStatus_IMM "Yawn Status_IMM";
BA_ "SysSignalName" SG_ 527 YawnStatus_IMM "YawnStatus_IMM";
BA_ "CompuMethodName" SG_ 527 IMM_50ms_Group02_Reserved8 "IMM_50ms_Group02_Reserved8";
BA_ "GenSigStartValue" SG_ 527 IMM_50ms_Group02_Reserved8 255;
BA_ "ISignalName" SG_ 527 IMM_50ms_Group02_Reserved8 "IIMM_50ms_Group02_Reserved8";
BA_ "SysSignalName" SG_ 527 IMM_50ms_Group02_Reserved8 "IMM_50ms_Group02_Reserved8";
BA_ "CompuMethodName" SG_ 527 IMM_50ms_Group02_Reserved9 "IMM_50ms_Group02_Reserved9";
BA_ "GenSigStartValue" SG_ 527 IMM_50ms_Group02_Reserved9 255;
BA_ "ISignalName" SG_ 527 IMM_50ms_Group02_Reserved9 "IIMM_50ms_Group02_Reserved9";
BA_ "SysSignalName" SG_ 527 IMM_50ms_Group02_Reserved9 "IMM_50ms_Group02_Reserved9";
BA_ "CompuMethodName" SG_ 527 IMM_50ms_Group02_Reserved10 "IMM_50ms_Group02_Reserved10";
BA_ "GenSigStartValue" SG_ 527 IMM_50ms_Group02_Reserved10 255;
BA_ "ISignalName" SG_ 527 IMM_50ms_Group02_Reserved10 "IIMM_50ms_Group02_Reserved10";
BA_ "SysSignalName" SG_ 527 IMM_50ms_Group02_Reserved10 "IMM_50ms_Group02_Reserved10";
BA_ "CompuMethodName" SG_ 657 DMSCameraFps_IMM "DMSCameraFps_IMM";
BA_ "ISignalName" SG_ 657 DMSCameraFps_IMM "IDMSCameraFps_IMM";
BA_ "LongName" SG_ 657 DMSCameraFps_IMM "DMS Camera Frames per second_IMM";
BA_ "SysSignalName" SG_ 657 DMSCameraFps_IMM "DMSCameraFps_IMM";
BA_ "CompuMethodName" SG_ 1237 IMM_NM_BSMtoRMS_BKPCANFD "IMM_NM_BSMtoRMS_BKPCANFD";
BA_ "ISignalName" SG_ 1237 IMM_NM_BSMtoRMS_BKPCANFD "IIMM_NM_BSMtoRMS_BKPCANFD";
BA_ "LongName" SG_ 1237 IMM_NM_BSMtoRMS_BKPCANFD "IMM_NM_BSMtoRMS_BKPCANFD";
BA_ "SysSignalName" SG_ 1237 IMM_NM_BSMtoRMS_BKPCANFD "IMM_NM_BSMtoRMS_BKPCANFD";
BA_ "CompuMethodName" SG_ 1237 IMM_NM_PBSMtoRMS_BKPCANFD "IMM_NM_PBSMtoRMS_BKPCANFD";
BA_ "ISignalName" SG_ 1237 IMM_NM_PBSMtoRMS_BKPCANFD "IIMM_NM_PBSMtoRMS_BKPCANFD";
BA_ "LongName" SG_ 1237 IMM_NM_PBSMtoRMS_BKPCANFD "IMM_NM_PBSMtoRMS_BKPCANFD";
BA_ "SysSignalName" SG_ 1237 IMM_NM_PBSMtoRMS_BKPCANFD "IMM_NM_PBSMtoRMS_BKPCANFD";
BA_ "CompuMethodName" SG_ 1237 IMM_NM_RMStoNOS_BKPCANFD "IMM_NM_RMStoNOS_BKPCANFD";
BA_ "ISignalName" SG_ 1237 IMM_NM_RMStoNOS_BKPCANFD "IIMM_NM_RMStoNOS_BKPCANFD";
BA_ "LongName" SG_ 1237 IMM_NM_RMStoNOS_BKPCANFD "IMM_NM_RMStoNOS_BKPCANFD";
BA_ "SysSignalName" SG_ 1237 IMM_NM_RMStoNOS_BKPCANFD "IMM_NM_RMStoNOS_BKPCANFD";
BA_ "CompuMethodName" SG_ 1237 IMM_NM_RSStoNOS_BKPCANFD "IMM_NM_RSStoNOS_BKPCANFD";
BA_ "ISignalName" SG_ 1237 IMM_NM_RSStoNOS_BKPCANFD "IIMM_NM_RSStoNOS_BKPCANFD";
BA_ "LongName" SG_ 1237 IMM_NM_RSStoNOS_BKPCANFD "IMM_NM_RSStoNOS_BKPCANFD";
BA_ "SysSignalName" SG_ 1237 IMM_NM_RSStoNOS_BKPCANFD "IMM_NM_RSStoNOS_BKPCANFD";
BA_ "CompuMethodName" SG_ 1237 IMM_NM_RSStoRMS_BKPCANFD "IMM_NM_RSStoRMS_BKPCANFD";
BA_ "ISignalName" SG_ 1237 IMM_NM_RSStoRMS_BKPCANFD "IIMM_NM_RSStoRMS_BKPCANFD";
BA_ "LongName" SG_ 1237 IMM_NM_RSStoRMS_BKPCANFD "IMM_NM_RSStoRMS_BKPCANFD";
BA_ "SysSignalName" SG_ 1237 IMM_NM_RSStoRMS_BKPCANFD "IMM_NM_RSStoRMS_BKPCANFD";
BA_ "CompuMethodName" SG_ 1237 IMM_NM_NOStoRMS_BKPCANFD "IMM_NM_NOStoRMS_BKPCANFD";
BA_ "ISignalName" SG_ 1237 IMM_NM_NOStoRMS_BKPCANFD "IIMM_NM_NOStoRMS_BKPCANFD";
BA_ "LongName" SG_ 1237 IMM_NM_NOStoRMS_BKPCANFD "IMM_NM_NOStoRMS_BKPCANFD";
BA_ "SysSignalName" SG_ 1237 IMM_NM_NOStoRMS_BKPCANFD "IMM_NM_NOStoRMS_BKPCANFD";
BA_ "CompuMethodName" SG_ 1237 IMM_NM_NOSSta_BKPCANFD "IMM_NM_NOSSta_BKPCANFD";
BA_ "ISignalName" SG_ 1237 IMM_NM_NOSSta_BKPCANFD "IIMM_NM_NOSSta_BKPCANFD";
BA_ "LongName" SG_ 1237 IMM_NM_NOSSta_BKPCANFD "IMM_NM_NOSSta_BKPCANFD";
BA_ "SysSignalName" SG_ 1237 IMM_NM_NOSSta_BKPCANFD "IMM_NM_NOSSta_BKPCANFD";
BA_ "CompuMethodName" SG_ 1237 IMM_NM_RMSSta_BKPCANFD "IMM_NM_RMSSta_BKPCANFD";
BA_ "ISignalName" SG_ 1237 IMM_NM_RMSSta_BKPCANFD "IIMM_NM_RMSSta_BKPCANFD";
BA_ "LongName" SG_ 1237 IMM_NM_RMSSta_BKPCANFD "IMM_NM_RMSSta_BKPCANFD";
BA_ "SysSignalName" SG_ 1237 IMM_NM_RMSSta_BKPCANFD "IMM_NM_RMSSta_BKPCANFD";
BA_ "CompuMethodName" SG_ 1237 IMM_NWI_BKPCANFD "IMM_NWI_BKPCANFD";
BA_ "ISignalName" SG_ 1237 IMM_NWI_BKPCANFD "IIMM_NWI_BKPCANFD";
BA_ "LongName" SG_ 1237 IMM_NWI_BKPCANFD "IMM BKPCANFD Network_Wakeup_Indication";
BA_ "SysSignalName" SG_ 1237 IMM_NWI_BKPCANFD "IMM_NWI_BKPCANFD";
BA_ "CompuMethodName" SG_ 1237 IMM_NOI_BKPCANFD "IMM_NOI_BKPCANFD";
BA_ "ISignalName" SG_ 1237 IMM_NOI_BKPCANFD "IIMM_NOI_BKPCANFD";
BA_ "LongName" SG_ 1237 IMM_NOI_BKPCANFD "IMM BKPCANFD Network Operation Indication";
BA_ "SysSignalName" SG_ 1237 IMM_NOI_BKPCANFD "IMM_NOI_BKPCANFD";
BA_ "CompuMethodName" SG_ 1237 IMM_NKI_BKPCANFD "IMM_NKI_BKPCANFD";
BA_ "ISignalName" SG_ 1237 IMM_NKI_BKPCANFD "IIMM_NKI_BKPCANFD";
BA_ "LongName" SG_ 1237 IMM_NKI_BKPCANFD "IMM BKPCANFD Network Keep Indication";
BA_ "SysSignalName" SG_ 1237 IMM_NKI_BKPCANFD "IMM_NKI_BKPCANFD";
BA_ "CompuMethodName" SG_ 1767 EvtPotclSigIPD1 "EvtPotclSigIPD1";
BA_ "ISignalName" SG_ 1767 EvtPotclSigIPD1 "IEvtPotclSigIPD1";
BA_ "LongName" SG_ 1767 EvtPotclSigIPD1 "Event_Protocol_Signal_IPD_1";
BA_ "SysSignalName" SG_ 1767 EvtPotclSigIPD1 "EvtPotclSigIPD1";
BA_ "CompuMethodName" SG_ 1767 EvtPotclSigIPD2 "EvtPotclSigIPD2";
BA_ "ISignalName" SG_ 1767 EvtPotclSigIPD2 "IEvtPotclSigIPD2";
BA_ "LongName" SG_ 1767 EvtPotclSigIPD2 "Event_Protocol_Signal_IPD_2";
BA_ "SysSignalName" SG_ 1767 EvtPotclSigIPD2 "EvtPotclSigIPD2";
BA_ "CompuMethodName" SG_ 1767 EvtPotclSigIPD3 "EvtPotclSigIPD3";
BA_ "ISignalName" SG_ 1767 EvtPotclSigIPD3 "IEvtPotclSigIPD3";
BA_ "LongName" SG_ 1767 EvtPotclSigIPD3 "Event_Protocol_Signal_IPD_3";
BA_ "SysSignalName" SG_ 1767 EvtPotclSigIPD3 "EvtPotclSigIPD3";
BA_ "CompuMethodName" SG_ 1767 EvtPotclSigIPD4 "EvtPotclSigIPD4";
BA_ "ISignalName" SG_ 1767 EvtPotclSigIPD4 "IEvtPotclSigIPD4";
BA_ "LongName" SG_ 1767 EvtPotclSigIPD4 "Event_Protocol_Signal_IPD_4";
BA_ "SysSignalName" SG_ 1767 EvtPotclSigIPD4 "EvtPotclSigIPD4";
BA_ "CompuMethodName" SG_ 1767 EvtPotclSigIPD5 "EvtPotclSigIPD5";
BA_ "ISignalName" SG_ 1767 EvtPotclSigIPD5 "IEvtPotclSigIPD5";
BA_ "LongName" SG_ 1767 EvtPotclSigIPD5 "Event_Protocol_Signal_IPD_5";
BA_ "SysSignalName" SG_ 1767 EvtPotclSigIPD5 "EvtPotclSigIPD5";
BA_ "CompuMethodName" SG_ 1767 EvtPotclSigIPD6 "EvtPotclSigIPD6";
BA_ "ISignalName" SG_ 1767 EvtPotclSigIPD6 "IEvtPotclSigIPD6";
BA_ "LongName" SG_ 1767 EvtPotclSigIPD6 "Event_Protocol_Signal_IPD_6";
BA_ "SysSignalName" SG_ 1767 EvtPotclSigIPD6 "EvtPotclSigIPD6";
BA_ "CompuMethodName" SG_ 1767 EvtPotclSigIPD7 "EvtPotclSigIPD7";
BA_ "ISignalName" SG_ 1767 EvtPotclSigIPD7 "IEvtPotclSigIPD7";
BA_ "LongName" SG_ 1767 EvtPotclSigIPD7 "Event_Protocol_Signal_IPD_7";
BA_ "SysSignalName" SG_ 1767 EvtPotclSigIPD7 "EvtPotclSigIPD7";
BA_ "CompuMethodName" SG_ 1767 EvtPotclSigIPD8 "EvtPotclSigIPD8";
BA_ "ISignalName" SG_ 1767 EvtPotclSigIPD8 "IEvtPotclSigIPD8";
BA_ "LongName" SG_ 1767 EvtPotclSigIPD8 "Event_Protocol_Signal_IPD_8";
BA_ "SysSignalName" SG_ 1767 EvtPotclSigIPD8 "EvtPotclSigIPD8";
VAL_ 591 DrvrFtgLvl 0 "DrvrFtgLvl_0_Unknown" 1 "DrvrFtgLvl_1_No_Drowsiness" 2 "DrvrFtgLvl_2_Low_level_Drowsiness" 3 "DrvrFtgLvl_3_Middle_level_Drowsiness" 4 "DrvrFtgLvl_4_High_level_Drowsiness" 5 "DrvrFtgLvl_5_Reserve" 6 "DrvrFtgLvl_6_Reserve" 7 "DrvrFtgLvl_7_Reserve";
VAL_ 591 ICMEyeOnRoad 0 "ICMEyeOnRoad_0_Unavailable_0x1EqualsICMEyeOnRoad_1_Eyes_On_Road_0x2EqualsICMEyeOnRoad_2_Eyes_Off_Road_driving_task_related_region_0x3EqualsICMEyeOnRoad_3_Eyes_Off_Road_non_driving_task_related_region_0x4EqualsICMEyeOnRoad_4_Reserve_0x5EqualsICMEyeOnRoad_5_Reserve_0x6EqualsICMEyeOnRoad_6_Reserve_0x7EqualsICMEyeOnRoad_7_Reserve";
VAL_ 591 DrvrDstrctnSts 0 "DrvrDstrctnSts_0_Unknown" 1 "DrvrDstrctnSts_1_NoDistraction" 2 "DrvrDstrctnSts_2_LowLevelDistraction" 3 "DrvrDstrctnSts_3_MiddleLevelDistraction" 4 "DrvrDstrctnSts_4_HighLevelDistraction" 5 "DrvrDstrctnSts_5_ShortTiemDistraction" 6 "DrvrDstrctnSts_6_LongTimeDistraction" 7 "DrvrDstrctnSts_7_Reserved";
VAL_ 591 ICMDrvrDstcnSts 0 "ICMDrvrDstcnSts_0_Unknown_0x1EqualsICMDrvrDstcnSts_1_No_distraction_0x2EqualsICMDrvrDstcnSts_2_Low_level_distraction_0x3EqualsICMDrvrDstcnSts_3_Middle_level_distraction_0x4EqualsICMDrvrDstcnSts_4_High_level_distraction_0x5EqualsICMDrvrDstcnSts_5_Reserve_0x6EqualsICMDrvrDstcnSts_6_Reserve_0x7EqualsICMDrvrDstcnSts_7_Reserve";
VAL_ 591 ICMDrvrPrst 0 "ICMDrvrPrst_0_Unknown_0x1EqualsICMDrvrPrst_1_Driver_Not_Presence_0x2EqualsICMDrvrPrst_2_Driver_Presence_0x3EqualsICMDrvrPrst_3_Reserve_0x4EqualsICMDrvrPrst_4_Reserve_0x5EqualsICMDrvrPrst_5_Reserve_0x6EqualsICMDrvrPrst_6_Reserve_0x7EqualsICMDrvrPrst_7_Reserve";
VAL_ 591 ICMDrvrFtgLvl 0 "ICMDrvrFtgLvl_0_Unknown_0x1EqualsICMDrvrFtgLvl_1_No_Drowsiness_0x2EqualsICMDrvrFtgLvl_2_Low_level_Drowsiness_0x3EqualsICMDrvrFtgLvl_3_Middle_level_Drowsiness_0x4EqualsICMDrvrFtgLvl_4_High_level_Drowsiness_0x5EqualsICMDrvrFtgLvl_5_Unresponsive_Driver_0x6EqualsICMDrvrFtgLvl_6_Reserved_0x7EqualsICMDrvrFtgLvl_7_Reserved";
VAL_ 728 AIParkngReqICB 1 "AIParkngReqICB_1_Start_Parking_in" 2 "AIParkngReqICB_2_Start_Parking_out" 3 "AIParkngReqICB_3_Pause" 4 "AIParkngReqICB_4_Continue" 5 "AIParkngReqICB_5_Cancel" 6 "AIParkngReqICB_6_Back_XEquals1" 7 "AIParkngReqICB_7_Left_Parking_out" 8 "AIParkngReqICB_8_Right_Parking_out" 9 "AIParkngReqICB_9_Fast_Parking" 10 "AIParkngReqICB_10_Line_out_System_Start" 11 "AIParkngReqICB_11_Line_back_System_Start" 12 "AIParkngReqICB_12_Call_to_Position_X" 13 "AIParkngReqICB_13_StartParkingScanningManualDriving_XEquals1" 14 "AIParkngReqICB_14_Remote_turn_left_XEquals8" 15 "AIParkngReqICB_15_Remote_turn_right_XEquals8" 16 "AIParkngReqICB_16_RememberBuildMap" 17 "AIParkngReqICB_17_Remember_Park_In" 18 "AIParkngReqICB_18_Remember_Summon" 19 "AIParkngReqICB_19_Start_Remember_Parking" 20 "AIParkngReqICB_20_Keep_Going_Forword" 21 "AIParkngReqICB_21_Keep_Going_Back" 22 "AIParkngReqICB_22_Start_AVP_in" 23 "AIParkngReqICB_23_Start_AVP_out" 24 "AIParkngReqICB_24_Back_Left_Parking_out" 25 "AIParkngReqICB_25_Back_Right_Parking_out" 32 "AIParkngReqICB_32_choose_left_direction_XEquals1" 33 "AIParkngReqICB_33_choose_right_direction_XEquals1" 34 "AIParkngReqICB_34_ReverseParkingInRecordingParking_XEquals1" 35 "AIParkngReqICB_35_MinorAdjEntry_XEquals1" 36 "AIParkngReqICB_36_MinorAdjActive_XEquals1" 37 "AIParkngReqICB_37_ReverseParkingEntry_XEquals1" 38 "MinorAdjActive_Left_XEquals1_2_P11L_M2_P11LX1_S11L_M1_P12L_427PP01_P11L_M3_EP33L_S11L_M2_S12L_M1" 39 "MinorAdjActive_Right_XEquals1_2_P11L_M2_P11LX1_S11L_M1_P12L_427PP01_P11L_M3_EP33_S11L_M2_S12L_M1" 40 "FixMinorAdj_XEquals1_2_P11L_M2_P11LX1_S11L_M1_P12L_427PP01_P11L_M3_EP33L_S11L_M2_S12L_M1" 41 "AIParkngReqICB_41_Trun_around_Left" 42 "AIParkngReqICB_42_RPAIN_Confirming" 45 "AIParkngReqICB_45_NarrowRoadForwardActive" 46 "AIParkngReqICB_46_NarrowRoadForwardEntry" 48 "AIParkngReqICB_48_Trun_around_Right" 49 "AIParkngReqICB_49_Choose_left_turn_round" 50 "AIParkngReqICB_50_Choose_right_turn_round" 51 "AIParkngReqICB_51_choose_right_back_direction" 52 "AIParkngReqICB_52_choose_left_back_direction" 53 "AIParkngReqICB_53_reserved" 54 "AIParkngReqICB_54_reserved" 55 "AIParkngReqICB_55_reserved" 56 "AIParkngReqICB_56_reserved" 57 "AIParkngReqICB_57_reserved" 58 "AIParkngReqICB_58_reserved" 59 "AIParkngReqICB_59_reserved" 60 "AIParkngReqICB_60_reserved" 61 "AIParkngReqICB_61_reserved" 62 "AIParkngReqICB_62_reserved" 63 "AIParkngReqICB_63_reserved" 64 "AIParkngReqICB_64_reserved" 65 "AIParkngReqICB_65_reserved" 66 "AIParkngReqICB_66_reserved" 67 "AIParkngReqICB_67_reserved" 68 "AIParkngReqICB_68_reserved" 69 "AIParkngReqICB_69_reserved" 70 "AIParkngReqICB_70_reserved" 71 "AIParkngReqICB_71_reserved" 72 "AIParkngReqICB_72_reserved" 73 "AIParkngReqICB_73_reserved" 74 "AIParkngReqICB_74_reserved" 75 "AIParkngReqICB_75_reserved" 76 "AIParkngReqICB_76_reserved" 77 "AIParkngReqICB_77_reserved" 78 "AIParkngReqICB_78_reserved" 79 "AIParkngReqICB_79_reserved" 80 "AIParkngReqICB_80_reserved" 81 "AIParkngReqICB_81_reserved" 82 "AIParkngReqICB_82_reserved" 83 "AIParkngReqICB_83_reserved" 84 "AIParkngReqICB_84_reserved" 85 "AIParkngReqICB_85_reserved" 86 "AIParkngReqICB_86_reserved" 87 "AIParkngReqICB_87_reserved" 88 "AIParkngReqICB_88_reserved" 89 "AIParkngReqICB_89_reserved" 90 "AIParkngReqICB_90_reserved" 91 "AIParkngReqICB_91_reserved" 92 "AIParkngReqICB_92_reserved" 93 "AIParkngReqICB_93_reserved" 94 "AIParkngReqICB_94_reserved" 95 "AIParkngReqICB_95_reserved" 96 "AIParkngReqICB_96_reserved" 97 "AIParkngReqICB_97_reserved" 98 "AIParkngReqICB_98_reserved" 99 "AIParkngReqICB_99_reserved" 100 "AIParkngReqICB_100_reserved" 101 "AIParkngReqICB_101_reserved" 102 "AIParkngReqICB_102_reserved" 103 "AIParkngReqICB_103_reserved" 104 "AIParkngReqICB_104_reserved" 105 "AIParkngReqICB_105_reserved" 106 "AIParkngReqICB_106_reserved" 107 "AIParkngReqICB_107_reserved" 108 "AIParkngReqICB_108_reserved" 109 "AIParkngReqICB_109_reserved" 110 "AIParkngReqICB_110_reserved" 111 "AIParkngReqICB_111_reserved" 112 "AIParkngReqICB_112_reserved" 113 "AIParkngReqICB_113_reserved" 114 "AIParkngReqICB_114_reserved" 115 "AIParkngReqICB_115_reserved" 116 "AIParkngReqICB_116_reserved" 117 "AIParkngReqICB_117_reserved" 118 "AIParkngReqICB_118_reserved" 119 "AIParkngReqICB_119_reserved" 120 "AIParkngReqICB_120_reserved" 121 "AIParkngReqICB_121_reserved" 122 "AIParkngReqICB_122_reserved" 123 "AIParkngReqICB_123_reserved" 124 "AIParkngReqICB_124_reserved" 125 "AIParkngReqICB_125_reserved" 126 "AIParkngReqICB_126_reserved" 127 "AIParkngReqICB_127_reserved" 128 "AIParkngReqICB_128_reserved" 129 "AIParkngReqICB_129_reserved" 130 "AIParkngReqICB_130_reserved" 131 "AIParkngReqICB_131_reserved" 132 "AIParkngReqICB_132_reserved" 133 "AIParkngReqICB_133_reserved" 134 "AIParkngReqICB_134_reserved" 135 "AIParkngReqICB_135_reserved" 136 "AIParkngReqICB_136_reserved" 137 "AIParkngReqICB_137_reserved" 138 "AIParkngReqICB_138_reserved" 139 "AIParkngReqICB_139_reserved" 140 "AIParkngReqICB_140_reserved" 141 "AIParkngReqICB_141_reserved" 142 "AIParkngReqICB_142_reserved" 143 "AIParkngReqICB_143_reserved" 144 "AIParkngReqICB_144_reserved" 145 "AIParkngReqICB_145_reserved" 146 "AIParkngReqICB_146_reserved" 147 "AIParkngReqICB_147_reserved" 148 "AIParkngReqICB_148_reserved" 149 "AIParkngReqICB_149_reserved" 150 "AIParkngReqICB_150_reserved" 151 "AIParkngReqICB_151_reserved" 152 "AIParkngReqICB_152_reserved" 153 "AIParkngReqICB_153_reserved" 154 "AIParkngReqICB_154_reserved" 155 "AIParkngReqICB_155_reserved" 156 "AIParkngReqICB_156_reserved" 157 "AIParkngReqICB_157_reserved" 158 "AIParkngReqICB_158_reserved" 159 "AIParkngReqICB_159_reserved" 160 "AIParkngReqICB_160_reserved" 161 "AIParkngReqICB_161_reserved" 162 "AIParkngReqICB_162_reserved" 163 "AIParkngReqICB_163_reserved" 164 "AIParkngReqICB_164_reserved" 165 "AIParkngReqICB_165_reserved" 166 "AIParkngReqICB_166_reserved" 167 "AIParkngReqICB_167_reserved" 168 "AIParkngReqICB_168_reserved" 169 "AIParkngReqICB_169_reserved" 170 "AIParkngReqICB_170_reserved" 171 "AIParkngReqICB_171_reserved" 172 "AIParkngReqICB_172_reserved" 173 "AIParkngReqICB_173_reserved" 174 "AIParkngReqICB_174_reserved" 175 "AIParkngReqICB_175_reserved" 176 "AIParkngReqICB_176_reserved" 177 "AIParkngReqICB_177_reserved" 178 "AIParkngReqICB_178_reserved" 179 "AIParkngReqICB_179_reserved" 180 "AIParkngReqICB_180_reserved" 181 "AIParkngReqICB_181_reserved" 182 "AIParkngReqICB_182_reserved" 183 "AIParkngReqICB_183_reserved" 184 "AIParkngReqICB_184_reserved" 185 "AIParkngReqICB_185_reserved" 186 "AIParkngReqICB_186_reserved" 187 "AIParkngReqICB_187_reserved" 188 "AIParkngReqICB_188_reserved" 189 "AIParkngReqICB_189_reserved" 190 "AIParkngReqICB_190_reserved" 191 "AIParkngReqICB_191_reserved" 192 "AIParkngReqICB_192_reserved" 193 "AIParkngReqICB_193_reserved" 194 "AIParkngReqICB_194_reserved" 195 "AIParkngReqICB_195_reserved" 196 "AIParkngReqICB_196_reserved" 197 "AIParkngReqICB_197_reserved" 198 "AIParkngReqICB_198_reserved" 199 "AIParkngReqICB_199_reserved" 200 "AIParkngReqICB_200_reserved" 201 "AIParkngReqICB_201_reserved" 202 "AIParkngReqICB_202_reserved" 203 "AIParkngReqICB_203_reserved" 204 "AIParkngReqICB_204_reserved" 205 "AIParkngReqICB_205_reserved" 206 "AIParkngReqICB_206_reserved" 207 "AIParkngReqICB_207_reserved" 208 "AIParkngReqICB_208_reserved" 209 "AIParkngReqICB_209_reserved" 210 "AIParkngReqICB_210_reserved" 211 "AIParkngReqICB_211_reserved" 212 "AIParkngReqICB_212_reserved" 213 "AIParkngReqICB_213_reserved" 214 "AIParkngReqICB_214_reserved" 215 "AIParkngReqICB_215_reserved" 216 "AIParkngReqICB_216_reserved" 217 "AIParkngReqICB_217_reserved" 218 "AIParkngReqICB_218_reserved" 219 "AIParkngReqICB_219_reserved" 220 "AIParkngReqICB_220_reserved" 221 "AIParkngReqICB_221_reserved" 222 "AIParkngReqICB_222_reserved" 223 "AIParkngReqICB_223_reserved" 224 "AIParkngReqICB_224_reserved" 225 "AIParkngReqICB_225_reserved" 226 "AIParkngReqICB_226_reserved" 227 "AIParkngReqICB_227_reserved" 228 "AIParkngReqICB_228_reserved" 229 "AIParkngReqICB_229_reserved" 230 "AIParkngReqICB_230_reserved" 231 "AIParkngReqICB_231_reserved" 232 "AIParkngReqICB_232_reserved" 233 "AIParkngReqICB_233_reserved" 234 "AIParkngReqICB_234_reserved" 235 "AIParkngReqICB_235_reserved" 236 "AIParkngReqICB_236_reserved" 237 "AIParkngReqICB_237_reserved" 238 "AIParkngReqICB_238_reserved" 239 "AIParkngReqICB_239_reserved" 240 "AIParkngReqICB_240_reserved" 241 "AIParkngReqICB_241_reserved" 242 "AIParkngReqICB_242_reserved" 243 "AIParkngReqICB_243_reserved" 244 "AIParkngReqICB_244_reserved" 245 "AIParkngReqICB_245_reserved" 246 "AIParkngReqICB_246_reserved" 247 "AIParkngReqICB_247_reserved" 248 "AIParkngReqICB_248_reserved" 249 "AIParkngReqICB_249_reserved" 250 "AIParkngReqICB_250_reserved" 251 "AIParkngReqICB_251_reserved" 252 "AIParkngReqICB_252_reserved" 253 "AIParkngReqICB_253_reserved" 254 "AIParkngReqICB_254_reserved" 255 "AIParkngReqICB_255_reserved";
VAL_ 790 FOTAStatusValid 0 "FOTAStatusValid_0_invalid" 1 "FOTAStatusValid_1_valid";
VAL_ 790 FOTAStatus 0 "FOTAStatus_0_NoFOTA" 1 "FOTAStatus_1_FOTA" 2 "FOTAStatus_2_FOTAFinish" 3 "FOTAStatus_3_PreFOTA" 4 "FOTAStatus_4_Download";
VAL_ 790 FOTATarget 0 "FOTATarget_0_NoFOTA" 1 "FOTATarget_1_HVUnavailableGroup" 2 "FOTATarget_2_HMIUnavailableGroup" 3 "FOTATarget_3_LockUnavailableGroup" 4 "FOTATarget_4_Download" 5 "FOTATarget_5_NomalGroup" 6 "FOTATarget_6_HV_LockUnavailableGroup";
VAL_ 790 FOTATargetValid 0 "FOTATargetValid_0_invalid" 1 "FOTATargetValid_1_valid";
VAL_ 1008 OtsdAirTemCrValV 0 "OtsdAirTemCrValV_0_Valid" 1 "OtsdAirTemCrValV_1_Invalid";
VAL_ 1008 OtsdAirTemCrValMsk 0 "OtsdAirTemCrValMsk_0_Dont_Use_Data" 1 "OtsdAirTemCrValMsk_1_Use_Data";
VAL_ 1008 OtsdAirTemVDA 0 "OtsdAirTemVDA_0__Virtual_Device_Unavailable" 1 "OtsdAirTemVDA_1__Virtual_Device_Available";
VAL_ 922 AVMDspReq 0 "AVMDspReq_0_NoRequest" 1 "AVMDspReq_1_open" 2 "AVMDspReq_2_close" 3 "AVMDspReq_3_reserve";
VAL_ 922 HDCReq 0 "HDCReq_0_Norequest" 1 "HDCReq_1_ActiveHDC" 2 "HDCReq_2_DeactiveHDC" 3 "HDCReq_3_PressedHDCButton";
VAL_ 922 EmmsnTestMdFICMV 0 "EmmsnTestMdFICMV_0_valid" 1 "EmmsnTestMdFICMV_1_invalid";
VAL_ 922 FICMPwrDMdReq 0 "FICMPwrDMdReq_0_Auto" 1 "FICMPwrDMdReq_1_EVFirst" 2 "FICMPwrDMdReq_2_HEVFirst" 3 "FICMPwrDMdReq_3_Reserved";
VAL_ 922 FICMPwrDMdReqV 0 "FICMPwrDMdReqV_0_Valid" 1 "FICMPwrDMdReqV_1_Invalid";
VAL_ 922 EmmsnTestMdFICM 0 "EmmsnTestMdFICM_0_False" 1 "EmmsnTestMdFICM_1_True";
VAL_ 922 FICMPwrDMdReqV_AIHEV 0 "FICMPwrDMdReqV_0_Valid" 1 "FICMPwrDMdReqV_1_Invalid";
VAL_ 922 SusDmpngCtrlCustSetngReq 0 "SusDmpngCtrlCustSetngReq_0_NoRequest" 1 "SusDmpngCtrlCustSetngReq_1_Comfort_Mode" 2 "SusDmpngCtrlCustSetngReq_2_Normal_Mode" 3 "SusDmpngCtrlCustSetngReq_3_Sport_Mode" 4 "SusDmpngCtrlCustSetngReq_4_advanced_Mode" 5 "SusDmpngCtrlCustSetngReq_5_Reserved" 6 "SusDmpngCtrlCustSetngReq_6_Reserved" 7 "SusDmpngCtrlCustSetngReq_7_Reserved" 8 "SusDmpngCtrlCustSetngReq_8_Reserved" 9 "SusDmpngCtrlCustSetngReq_9_Reserved" 10 "SusDmpngCtrlCustSetngReq_10_Reserved" 11 "SusDmpngCtrlCustSetngReq_11_Reserved" 12 "SusDmpngCtrlCustSetngReq_12_Reserved" 13 "SusDmpngCtrlCustSetngReq_13_Reserved" 14 "SusDmpngCtrlCustSetngReq_14_Reserved" 15 "SusDmpngCtrlCustSetngReq_15_Reserved";
VAL_ 922 TrgtSOCReqFICMV 0 "TrgtSOCReqFICMV_0_valid" 1 "TrgtSOCReqFICMV_1_invalid";
VAL_ 922 FICMPwrDMdReq_AIHEV 0 "FICMPwrDMdReq_0_ForceEV" 1 "FICMPwrDMdReq_1_EVFirst" 2 "FICMPwrDMdReq_2_HEV" 3 "FICMPwrDMdReq_3_BatteryHold" 4 "FICMPwrDMdReq_4_AIHEV" 5 "FICMPwrDMdReq_5_Reserved" 6 "FICMPwrDMdReq_6_Reserved" 7 "FICMPwrDMdReq_7_Reserved";
VAL_ 795 DCDCVolStpt 254 "DCDCVolStpt_254_Init" 255 "DCDCVolStpt_255_Invalid";
VAL_ 795 SLIFUpdtIndReq 0 "SLIFUpdtIndReq_0_NoRequest" 1 "SLIFUpdtIndReq_1_Off" 2 "SLIFUpdtIndReq_2_On" 3 "SLIFUpdtIndReq_3_reserve";
VAL_ 795 SprSportSubItemReqV 0 "SprSportSubItemReqV_0_Valid" 1 "SprSportSubItemReqV_1_Invalid";
VAL_ 795 SprSportSubItemReq 0 "SprSportSubItemReq_0_Default" 1 "SprSportSubItemReq_1_AstonMartin" 2 "SprSportSubItemReq_2_Lamborghini" 3 "SprSportSubItemReq_3_Ferrari";
VAL_ 907 VehDrvngMd 0 "VehDrvngMd_0_No_Driving_Mode" 1 "VehDrvngMd_1_Super_ECO" 2 "VehDrvngMd_2_ECO" 3 "VehDrvngMd_3_Normal" 4 "VehDrvngMd_4_Sport" 5 "VehDrvngMd_5_OffRoad" 6 "VehDrvngMd_6_Snow" 7 "VehDrvngMd_7_Customization_Mode" 8 "VehDrvngMd_8_Trace" 9 "VehDrvngMd_9_Uncarsickness" 10 "VehDrvngMd_10_Reserved" 11 "VehDrvngMd_11_Reserved" 12 "VehDrvngMd_12_Sand";
VAL_ 907 VehLdShedLvl 0 "VehLdShedLvl_0_No_Power_Risk" 1 "VehLdShedLvl_1_Low_Power_Risk" 2 "VehLdShedLvl_2_Middle_Power_Risk" 3 "VehLdShedLvl_3_High_Power_Risk" 4 "VehLdShedLvl_4_Power_management_direct_current_converter_PMDC_broken" 5 "VehLdShedLvl_5_Warning";
VAL_ 907 VehOdoV 0 "VehOdoV_0_Valid" 1 "VehOdoV_1_Invalid";
VAL_ 907 FrtPsngAirbagSwStsReqV_Sfty 0 "FrtPsngAirbagSwStsReqV_Sfty_0_False" 1 "FrtPsngAirbagSwStsReqV_Sfty_1_True";
VAL_ 907 FrtPsngAirbagSwStsReq_Sfty 0 "FrtPsngAirbagSwStsReq_Sfty_0_PassengerAirbagOff" 1 "FrtPsngAirbagSwStsReq_Sfty_1_PassengerAirbagOn";
VAL_ 1345 VehTiPblshMth 0 "VehTiPblshMth_0_Unknown" 1 "VehTiPblshMth_1_January" 2 "VehTiPblshMth_2_February" 3 "VehTiPblshMth_3_March" 4 "VehTiPblshMth_4_April" 5 "VehTiPblshMth_5_May" 6 "VehTiPblshMth_6_June" 7 "VehTiPblshMth_7_July" 8 "VehTiPblshMth_8_August" 9 "VehTiPblshMth_9_September" 10 "VehTiPblshMth_10_October" 11 "VehTiPblshMth_11_November" 12 "VehTiPblshMth_12_December";
VAL_ 1345 TimeDspFmt 0 "TimeDspFmt_12_hour_mode" 1 "TimeDspFmt_24_hour_mode";
VAL_ 1151 TrlrMdSts 0 "TrlrMdSts_0_Inactive" 1 "TrlrMdSts_1_Active";
VAL_ 1151 OdoPriyPrcsV 0 "OdoPriyPrcsV_0_Valid" 1 "OdoPriyPrcsV_1_Invalid";
VAL_ 1151 EPTNotReadyReq 0 "EPTNotReadyReq_0_No_Request" 1 "EPTNotReadyReq_1_Request";
VAL_ 1151 ClstrDspdAirbagWrnng 0 "ClstrDspdAirbagWrnng_0_No_Warning" 1 "ClstrDspdAirbagWrnng_1_Warning";
VAL_ 361 NFCAMAvlbly 0 "NFCAMAvlbly_0_False" 1 "NFCAMAvlbly_1_True";
VAL_ 361 SASAvlbly 0 "SASAvlbly_0_False" 1 "SASAvlbly_1_True";
VAL_ 361 SDMAvlbly 0 "SDMAvlbly_0_False" 1 "SDMAvlbly_1_True";
VAL_ 361 RHZCUAvlbly 0 "RHZCUAvlbly_0_False" 1 "RHZCUAvlbly_1_True";
VAL_ 361 LHZCUAvlbly 0 "LHZCUAvlbly_0_False" 1 "LHZCUAvlbly_1_True";
VAL_ 361 TC_ExtdAvlbly 0 "TC_ExtdAvlbly_0_False" 1 "TC_ExtdAvlbly_1_True";
VAL_ 361 IBS_SFAvlbly 0 "IBS_SFAvlbly_0_False" 1 "IBS_SFAvlbly_1_True";
VAL_ 361 EPSAvlbly 0 "EPSAvlbly_0_False" 1 "EPSAvlbly_1_True";
VAL_ 361 TC_PTAvlbly 0 "TC_PTAvlbly_0_False" 1 "TC_PTAvlbly_1_True";
VAL_ 361 PICU_PTAvlbly 0 "PICU_PTAvlbly_0_False" 1 "PICU_PTAvlbly_1_True";
VAL_ 361 LVBM_PTAvlbly 0 "LVBMAvlbly_0_False" 1 "LVBMAvlbly_1_True";
VAL_ 361 PEU_PTAvlbly 0 "PEU_PTAvlbly_0_False" 1 "PEU_PTAvlbly_1_True";
VAL_ 361 PEU_ERAvlbly 0 "PEU_ERAvlbly_0_False" 1 "PEU_ERAvlbly_1_True";
VAL_ 361 PICU_ExtdAvlbly 0 "PICU_PTAvlbly_0_False" 1 "PICU_PTAvlbly_1_True";
VAL_ 361 LHRDAAvlbly 0 "LHRDAAvlbly_0_False" 1 "LHRDAAvlbly_1_True";
VAL_ 361 IPD_PTAvlbly 0 "IPD_PTAvlbly_0_False" 1 "IPD_PTAvlbly_1_True";
VAL_ 361 RHMPWCAvlbly 0 "RHMPWCAvlbly_0_False" 1 "RHMPWCAvlbly_1_True";
VAL_ 361 ESS_PTAvlbly 0 "ESSAvlbly_0_False" 1 "ESSAvlbly_1_True";
VAL_ 361 CCU_ExtdAvlbly 0 "CCUAvlbly_0_False" 1 "CCUAvlbly_1_True";
VAL_ 361 ESS_ExtdAvlbly 0 "ESSAvlbly_0_False" 1 "ESSAvlbly_1_True";
VAL_ 361 CCU_PTAvlbly 0 "CCUAvlbly_0_False" 1 "CCUAvlbly_1_True";
VAL_ 361 IAMAvlbly 0 "IAMAvlbly_0_False" 1 "IAMAvlbly_1_True";
VAL_ 361 EAC_Avlbly 0 "EAC_Avlbly_0_False" 1 "EAC_Avlbly_1_True";
VAL_ 361 PEU_SFAvlbly 0 "PEU_SFAvlbly_0_False" 1 "PEU_SFAvlbly_1_True";
VAL_ 361 PEU_ExtdAvlbly 0 "PEUAvlbly_0_False" 1 "PEUAvlbly_1_True";
VAL_ 361 TDMAvlbly 0 "TDMAvlbly_0_False" 1 "TDMAvlbly_1_True";
VAL_ 361 IPD_SFAvlbly 0 "IPD_SFAvlbly_0_False" 1 "IPD_SFAvlbly_1_True";
VAL_ 361 SAC_ExtdAvlbly 0 "SACAvlbly_0_False" 1 "SACAvlbly_1_True";
VAL_ 361 SAC_PTAvlbly 0 "SACAvlbly_0_False" 1 "SACAvlbly_1_True";
VAL_ 361 CCEOPAvlbly 0 "CCUAvlbly_0_False" 1 "CCUAvlbly_1_True";
VAL_ 361 RZCU_BKBCANFDAvlbly 0 "RZCU_BKBCANFDAvlbly_0_False" 1 "RZCU_BKBCANFDAvlbly_1_True";
VAL_ 361 IPD_BKPCANFDAvlbly 0 "ICBAD_BKPCANFDAvlbly_0_False" 1 "ICBAD_BKPCANFDAvlbly_1_True";
VAL_ 361 IPD_CHCANFDAvlbly 0 "IPD_CHCANFDAvlbly_0_False" 1 "IPD_CHCANFDAvlbly_1_True";
VAL_ 361 IBS_CHAvlbly 0 "IBSAvlbly_0_False" 1 "IBSAvlbly_1_True";
VAL_ 361 FDRAvlbly 0 "FDRAvlbly_0_False" 1 "FDRAvlbly_1_True";
VAL_ 361 RHRDAAvlbly 0 "RHRDAAvlbly_0_False" 1 "RHRDAAvlbly_1_True";
VAL_ 361 FVCMAvlbly 0 "FDRAvlbly_0_False" 1 "FDRAvlbly_1_True";
VAL_ 361 TPMSAvlbly 0 "TPMSAvlbly_0_False" 1 "TPMSAvlbly_1_True";
VAL_ 497 AMRPrtensonReq 0 "AMRPrtensonReq_0_NoRequest" 1 "AMRPrtensonReq_1_Level1Request" 2 "AMRPrtensonReq_2_Level2Request" 3 "AMRPrtensonReq_3_Level3Request" 4 "AMRPrtensonReq_4_Level4Request" 5 "AMRPrtensonReq_5_ShakeWarningRequest";
VAL_ 497 SysVolMdV 0 "SysVolMdV_0_Valid" 1 "SysVolMdV_1_Invalid";
VAL_ 497 VehMd 0 "VehMd_0_NORMAL" 1 "VehMd_1_CRASH" 2 "VehMd_2_FACTORY" 3 "VehMd_3_TRANSPORT" 4 "VehMd_4_DYNO" 5 "VehMd_5_EXHIBITION" 6 "VehMd_6_Reserved" 7 "VehMd_7_Reserved" 8 "VehMd_8_Engineering" 9 "VehMd_9_Service";
VAL_ 497 SysVolV 0 "SysVolV_0_Valid" 1 "SysVolV_1_Invalid";
VAL_ 497 SysPwrMdV 0 "SysPwrMdV_0_Valid" 1 "SysPwrMdV_1_Invalid";
VAL_ 497 VehMdV 0 "VehMdV_0_Invalid" 1 "VehMdV_1_Valid";
VAL_ 497 UsgMdV 0 "UsgMdV_0_Invalid" 1 "UsgMdV_1_Valid";
VAL_ 497 UsgMd 0 "UsgMd_0_Sleep" 1 "UsgMd_1_Standby" 2 "UsgMd_2_Comfortable" 3 "UsgMd_3_Driving" 4 "UsgMd_4_AIParking" 5 "UsgMd_5_AIPilot" 6 "UsgMd_6_XOTA";
VAL_ 497 PwrMdMstrRunCrkA 0 "PwrMdMstrRunCrkA_0_Inactive" 1 "PwrMdMstrRunCrkA_1_Active";
VAL_ 497 SysPwrMd 0 "SysPwrMd_0_Off" 1 "SysPwrMd_1_Accessory" 2 "SysPwrMd_2_Run" 3 "SysPwrMd_3_Crank_Request";
VAL_ 497 PwrMdMstrAccryA 0 "PwrMdMstrAccryA_0_Inactive" 1 "PwrMdMstrAccryA_1_Active";
VAL_ 497 SysOpnlMd 0 "SysOpnlMd_0_Normal_Mode" 1 "SysOpnlMd_1_Manufacturing_Mode" 2 "SysOpnlMd_2_Transit_Mode" 3 "SysOpnlMd_3_Show_Room" 4 "SysOpnlMd_4_Storage_Mode" 5 "SysOpnlMd_5_Diagnosic_or_Reprogramming" 6 "SysOpnlMd_6_DYNO_Mode" 7 "SysOpnlMd_7_CRASH_Mode" 8 "SysOpnlMd_8_Engineering" 9 "SysOpnlMd_9_Service";
VAL_ 497 BPMMstrAvlbly 0 "BPMMstrAvlbly_0_False" 1 "BPMMstrAvlbly_1_True";
VAL_ 497 SysVolMd 0 "SysVolMd_0_Normal" 1 "SysVolMd_1_Low_System_Voltage" 2 "SysVolMd_2_High_System_Voltage" 3 "SysVolMd_3_Illegal_System_Voltage";
VAL_ 60 TripCntResetReq 0 "TripCntResetReq_0_NoRequest" 1 "TripCntResetReq_1_EnableRequest";
VAL_ 60 ComKeyEnbReq 0 "ComKeyEnbReq_0_NoRequest" 1 "ComKeyEnbReq_1_EnableRequest";
VAL_ 815 EMCLPwrSts 0 "EMCLPwrSts_0_OFF" 1 "EMCLPwrSts_1_ON";
VAL_ 815 IMMPwrSts 0 "IMMPwrSts_0_OFF" 1 "IMMPwrSts_1_ON";
VAL_ 815 ESCLPwrSts 0 "ESCLPwrSts_0_OFF" 1 "ESCLPwrSts_1_ON";
VAL_ 815 BPEPSPwrSts 0 "BPEPSPwrSts_0_OFF" 1 "BPEPSPwrSts_1_ON";
VAL_ 815 ARHUDPwrSts 0 "ARHUDPwrSts_0_OFF" 1 "ARHUDPwrSts_1_ON";
VAL_ 815 LHAmbtLampPwrSts 0 "LHAmbtLampPwrSts_0_OFF" 1 "LHAmbtLampPwrSts_1_ON";
VAL_ 815 OHCPwrSts 0 "OHCPwrSts_0_OFF" 1 "OHCPwrSts_1_ON";
VAL_ 815 CnsoDspPwrSts 0 "CnsoDspPwrSts_0_OFF" 1 "CnsoDspPwrSts_1_ON";
VAL_ 815 FLVntngMotPwrSts 0 "FLVntngMotPwrSts_0_OFF" 1 "FLVntngMotPwrSts_1_ON";
VAL_ 815 FLSLMMPwrSts 0 "FLSLMMPwrSts_0_OFF" 1 "FLSLMMPwrSts_1_ON";
VAL_ 815 USBHubPwrSts 0 "USBHubPwrSts_0_OFF" 1 "USBHubPwrSts_1_ON";
VAL_ 815 DrvrDspPwrSts 0 "DrvrDspPwrSts_0_OFF" 1 "DrvrDspPwrSts_1_ON";
VAL_ 815 SWSPwrSts 0 "LHSWSPwrSts_0_OFF" 1 "LHSWSPwrSts_1_ON";
VAL_ 815 BrkSwPwrSts 0 "BrkSwPwrSts_0_OFF" 1 "BrkSwPwrSts_1_ON";
VAL_ 815 HODMPwrSts 0 "HODMPwrSts_0_OFF" 1 "HODMPwrSts_1_ON";
VAL_ 815 RLSSPwrSts 0 "RLSSPwrSts_0_OFF" 1 "RLSSPwrSts_1_ON";
VAL_ 815 ETCMPwrSts 0 "ETCMPwrSts_0_OFF" 1 "ETCMPwrSts_1_ON";
VAL_ 815 LHSWPwrSts 0 "LHSWPwrSts_0_OFF" 1 "LHSWPwrSts_1_ON";
VAL_ 815 NFCAMPwrSts 0 "NFCAMPwrSts_0_OFF" 1 "NFCAMPwrSts_1_ON";
VAL_ 815 NFCSMPwrSts 0 "NFCSMPwrSts_0_OFF" 1 "NFCSMPwrSts_1_ON";
VAL_ 815 SACPwrSts 0 "SACPwrSts_0_OFF" 1 "SACPwrSts_1_ON";
VAL_ 815 CnsoUSBPwrSts 0 "CnsoUSBPwrSts_0_OFF" 1 "CnsoUSBPwrSts_1_ON";
VAL_ 815 RrPDCPwrSts 0 "RrPDCPwrSts_0_OFF" 1 "RrPDCPwrSts_1_ON";
VAL_ 815 FrtPDCPwrSts 0 "FrtPDCPwrSts_0_OFF" 1 "FrtPDCPwrSts_1_ON";
VAL_ 815 FVCMPwrSts 0 "FVCMPwrSts_0_OFF" 1 "FVCMPwrSts_1_ON";
VAL_ 815 TPMSPwrSts 0 "TPMSPwrSts_0_OFF" 1 "TPMSPwrSts_1_ON";
VAL_ 815 AIBOTPwrSts 0 "AIBOTPwrSts_0_OFF" 1 "AIBOTPwrSts_1_ON";
VAL_ 815 IterMirPwrSts 0 "IterMirPwrSts_0_OFF" 1 "IterMirPwrSts_1_ON";
VAL_ 815 IMSPwrSts 0 "IMSPwrSts_0_OFF" 1 "IMSPwrSts_1_ON";
VAL_ 815 CPDPwrSts 0 "CPDPwrSts_0_OFF" 1 "CPDPwrSts_1_ON";
VAL_ 815 DABMPwrSts 0 "DABMPwrSts_0_OFF" 1 "DABMPwrSts_1_ON";
VAL_ 913 RHSwPwrSts 0 "RHSwPwrSts_0_OFF" 1 "RHSwPwrSts_1_ON";
VAL_ 913 RHAmbtLampPwrSts 0 "RHAmbtLampPwrSts_0_OFF" 1 "RHAmbtLampPwrSts_1_ON";
VAL_ 913 CnsoUSB1PwrSts 0 "CnsoUSB1PwrSts_0_OFF" 1 "CnsoUSB1PwrSts_1_ON";
VAL_ 913 AirVentMotPwrSts 0 "AirVentMotPwrSts_0_OFF" 1 "AirVentMotPwrSts_1_ON";
VAL_ 913 CFPwrSts 0 "CFPwrSts_0_OFF" 1 "CFPwrSts_1_ON";
VAL_ 913 FRVntngMotPwrSts 0 "FRVntngMotPwrSts_0_OFF" 1 "FRVntngMotPwrSts_1_ON";
VAL_ 913 FRSLMMPwrSts 0 "FRSLMMPwrSts_0_OFF" 1 "FRSLMMPwrSts_1_ON";
VAL_ 913 FrtPwrSktPwrSts 0 "FrtPwrSktPwrSts_0_OFF" 1 "FrtPwrSktPwrSts_1_ON";
VAL_ 913 FrtSDAPwrSts 0 "FrtSDAPwrSts_0_OFF" 1 "FrtSDAPwrSts_1_ON";
VAL_ 913 FLiDARPwrSts 0 "FLiDARPwrSts_0_OFF" 1 "FLiDARPwrSts_1_ON";
VAL_ 913 IAMPwrSts 0 "IAMPwrSts_0_OFF" 1 "IAMPwrSts_1_ON";
VAL_ 913 SDMPwrSts 0 "SDMPwrSts_0_OFF" 1 "SDMPwrSts_1_ON";
VAL_ 913 FDRPwrSts 0 "FDRPwrSts_0_OFF" 1 "FDRPwrSts_1_ON";
VAL_ 902 IPDPowerFailSwReq 0 "IPDPowerFailSwReq_0_NoRequest" 1 "IPDPowerFailSwReq_1_off" 2 "IPDPowerFailSwReq_2_on" 3 "IPDPowerFailSwReq_3_LowPwrMd";
VAL_ 902 RACtlReq 0 "RACtlReq_0_NoRequest" 1 "RACtlReq_1_Entry" 2 "RACtlReq_2_Start" 3 "RACtlReq_3_Pause" 4 "RACtlReq_4_Continue" 5 "RACtlReq_5_Exit" 6 "RACtlReq_6_Reserved6" 7 "RACtlReq_7_Reserved7";
VAL_ 902 ShwrmComprEnbReq 0 "ShwrmComprEnbReq__0_Disable_Request" 1 "ShwrmComprEnbReq__1_Enable_Request";
VAL_ 902 SrfOpenSts 0 "SrfOpenSts_0_Fully_Close" 1 "SrfOpenSts_1_Tilt_Open_not_fully" 2 "SrfOpenSts_2_Fully_Tilt_Open" 3 "SrfOpenSts_3_Slide_Open_not_fully" 4 "SrfOpenSts_4_Fully_Open" 5 "SrfOpenSts_5_is_moving" 6 "SrfOpenSts_6_Unknown";
VAL_ 902 RainClsWndAppMsg 0 "RainClsWndAppMsg_0_unknown_default" 1 "RainClsWndAppMsg_1_Close_due_to_rainy_successful" 2 "RainClsWndAppMsg_2_Close_due_to_rainy_failed" 3 "RainClsWndAppMsg_3_Close_due_to_ventilation_timeover_successful" 4 "RainClsWndAppMsg_4_Close_due_to_ventilation_timeover_failed" 5 "RainClsWndAppMsg_5_Rainy_detection_activate_fail" 6 "RainClsWndAppMsg_6_reserved" 7 "RainClsWndAppMsg_7_reserved";
VAL_ 955 ClstrDspdVehSpd_mph 255 "ClstrDspdVehSpd_255_Speed_Signal_Missing_Error_of_SCS";
VAL_ 955 RrSsdPosCtrl 127 "FrSsdPosCtrl_127_Stop" 255 "FrSsdPosCtrl_255_Invaild";
VAL_ 955 ACCTJAMdSwReq 0 "ACCTJAMdSwReq_0_NoRequest" 1 "ACCTJAMdSwReq_1_ACC" 2 "ACCTJAMdSwReq_2_TJA" 3 "ACCTJAMdSwReq_3_SHWA" 4 "ACCTJAMdSwReq_4_Off" 5 "ACCTJAMdSwReq_5_Reserved" 6 "ACCTJAMdSwReq_6_Reserved" 7 "ACCTJAMdSwReq_7_Reserved";
VAL_ 955 FICMACLTemReq 0 "FICMACLTemReq_0_Lo" 30 "FICMACLTemReq_30_High" 31 "FICMACLTemReq_31_Reserved";
VAL_ 955 ACCStsSwReq 0 "ACCStsSwReq_0_NoRequest" 1 "ACCStsSwReq_1_Off" 2 "ACCStsSwReq_2_On" 3 "ACCStsSwReq_3_Reserve";
VAL_ 955 ACCSpdLimtSwReq 0 "ACCSpdLimtSwReq_0_NoRequest" 1 "ACCSpdLimtSwReq_1_manual" 2 "ACCSpdLimtSwReq_2_Auto" 3 "ACCSpdLimtSwReq_3_OFF";
VAL_ 955 ACCCurveSpdSwReq 0 "ACCCurveSpdSwReq_0_NoRequest" 1 "ACCCurveSpdSwReq_1_Off" 2 "ACCCurveSpdSwReq_2_On" 3 "ACCCurveSpdSwReq_3_Reserve";
VAL_ 955 ACCConfmSwReq 0 "ACCConfmSwReq_0_NoRequest" 1 "ACCConfmSwReq_1_NoConfirm" 2 "ACCConfmSwReq_2_Confirm" 3 "ACCConfmSwReq_3_Reserve";
VAL_ 955 ACUserCustEcoSetngReqV 0 "ACUserCustEcoSetngReqV_0_Valid" 1 "ACUserCustEcoSetngReqV_1_Invalid";
VAL_ 955 ACUserCustEcoSetngReq 0 "ACUserCustEcoSetngReq_0_Unavailable" 1 "ACUserCustEcoSetngReq_1_Economy_Mode" 2 "ACUserCustEcoSetngReq_2_Normal_Mode" 3 "ACUserCustEcoSetngReq_3_Reserved";
VAL_ 955 ACUserCustAutoMdBlwrReqV 0 "ACUserCustAutoMdBlwrReqV_0_Valid" 1 "ACUserCustAutoMdBlwrReqV_1_Invalid";
VAL_ 955 ACUserCustAutoMdBlwrReq 0 "ACUserCustAutoMdBlwrReq_0_High_level" 1 "ACUserCustAutoMdBlwrReq_1_Middle_level" 2 "ACUserCustAutoMdBlwrReq_2_Low_level" 3 "ACUserCustAutoMdBlwrReq_3_Reserved";
VAL_ 955 ACUserCustAftRunOnOffReqV 0 "ACUserCustAftRunOnOffReqV_0_Vaild" 1 "ACUserCustAftRunOnOffReqV_1_Invaild";
VAL_ 955 ACUserCustAftRunOnOffR 0 "ACUserCustAftRunOnOffR_0_Off" 1 "ACUserCustAftRunOnOffR_1_On";
VAL_ 955 FICMACFrtBlwrSpdDecSwR 0 "FICMACFrtBlwrSpdDecSwR_0_No_request" 1 "FICMACFrtBlwrSpdDecSwR_1_Short_press" 2 "FICMACFrtBlwrSpdDecSwR_2_Long_press";
VAL_ 955 FICMACAutoSwReq 0 "FICMACAutoSwReq_0_No_request" 1 "FICMACAutoSwReq_1_Short_press" 2 "FICMACAutoSwReq_2_Long_press";
VAL_ 955 ADAudioSWReq 0 "ADAudioSWReq_0_NoRequest" 1 "ADAudioSWReq_1_Off" 2 "ADAudioSWReq_2_Concise" 3 "ADAudioSWReq_3_Standard";
VAL_ 955 FICMACLTemDecSwReq 0 "FICMACLTemDecSwReq_0_No_request" 1 "FICMACLTemDecSwReq_1_Short_press" 2 "FICMACLTemDecSwReq_2_Long_press";
VAL_ 955 FICMACFrtBlwrSpdIncSwR 0 "FICMACFrtBlwrSpdIncSwR_0_No_request" 1 "FICMACFrtBlwrSpdIncSwR_1_Short_press" 2 "FICMACFrtBlwrSpdIncSwR_2_Long_press";
VAL_ 955 FICMACFrtBlwrLvlReq 0 "FICMACFrtBlwrLvlReq_0_Blower_Off" 1 "FICMACFrtBlwrLvlReq_1_Blower_level_1" 2 "FICMACFrtBlwrLvlReq_2_Blower_level_2" 3 "FICMACFrtBlwrLvlReq_3_Blower_level_3" 4 "FICMACFrtBlwrLvlReq_4_Blower_level_4" 5 "FICMACFrtBlwrLvlReq_5_Blower_level_5" 6 "FICMACFrtBlwrLvlReq_6_Blower_level_6" 7 "FICMACFrtBlwrLvlReq_7_Blower_level_7" 8 "FICMACFrtBlwrLvlReq_8_Blower_level_8" 9 "FICMACFrtBlwrLvlReq_9_Blower_level_9" 10 "FICMACFrtBlwrLvlReq_10_Blower_level_10" 11 "FICMACFrtBlwrLvlReq_11_Blower_level_11" 12 "FICMACFrtBlwrLvlReq_12_Blower_level_12" 13 "FICMACFrtBlwrLvlReq_13_Blower_level_13" 14 "FICMACFrtBlwrLvlReq_14_Blower_level_14" 15 "FICMACFrtBlwrLvlReq_15_Blower_level_15";
VAL_ 955 FICMACOnOffSwReq 0 "FICMACOnOffSwReq_0_No_request" 1 "FICMACOnOffSwReq_1_Short_press" 2 "FICMACOnOffSwReq_2_Long_press";
VAL_ 955 FICMACLTemIncSwReq 0 "FICMACLTemIncSwReq_0_No_request" 1 "FICMACLTemIncSwReq_1_Short_press" 2 "FICMACLTemIncSwReq_2_Long_press";
VAL_ 955 FICMACLAirMdReqV 0 "FICMACLAirMdReqV_0_Valid" 1 "FICMACLAirMdReqV_1_Invalid";
VAL_ 955 FICMACLAirMdReq 0 "FICMACLAirMdReq_0_face" 1 "FICMACLAirMdReq_1_face_foot" 2 "FICMACLAirMdReq_2_foot" 3 "FICMACLAirMdReq_3_foot_defrost" 4 "FICMACLAirMdReq_4_defrost" 5 "FICMACLAirMdReq_5_face_foot_defrost" 6 "FICMACLAirMdReq_6_face_defrost" 7 "FICMACLAirMdReq_7_No_Command_air_distribute_mode";
VAL_ 955 FICMComprOnOffSwReq 0 "FICMComprOnOffSwReq_0_No_request" 1 "FICMComprOnOffSwReq_1_Short_press" 2 "FICMComprOnOffSwReq_2_Long_press";
VAL_ 955 FICMACSemiAutoSwReq 0 "FICMACSemiAutoSwReq_0_Norequest" 1 "FICMACSemiAutoSwReq_1_Shortpress" 2 "FICMACSemiAutoSwReq_2_Longpress" 3 "FICMACSemiAutoSwReq_3_Reserved";
VAL_ 955 FICMACRcctnSwReq 0 "FICMACRcctnSwReq_0_No_request" 1 "FICMACRcctnSwReq_1_Short_press" 2 "FICMACRcctnSwReq_2_Long_press";
VAL_ 955 FICMACRcctnMdReq 0 "FICMACRcctnMdReq_0_Recirculation" 1 "FICMACRcctnMdReq_1_Fresh" 2 "FICMACRcctnMdReq_2_Auto_recirculation" 3 "FICMACRcctnMdReq_3_Initial";
VAL_ 955 FICMHtdRrWndSwReq 0 "FICMHtdRrWndSwReq_0_No_request" 1 "FICMHtdRrWndSwReq_1_Short_press" 2 "FICMHtdRrWndSwReq_2_Long_press";
VAL_ 955 FICMDfstOnSwReq 0 "FICMDfstOnSwReq_0_No_request" 1 "FICMDfstOnSwReq_1_Short_press" 2 "FICMDfstOnSwReq_2_Long_press";
VAL_ 955 FICMACLTemV 0 "FICMACLTemV_0_Valid" 1 "FICMACLTemV_1_Invalid";
VAL_ 955 TLRMdSwReq 0 "TLRMdSwReq_0_NoRequest" 1 "TLRMdSwReq_1_TLR_on" 2 "TLRMdSwReq_2_TLR_off" 3 "TLRMdSwReq_3_TLR_alert_on" 4 "TLRMdSwReq_4_TLR_alert_off" 5 "TLRMdSwReq_5_Reserved" 6 "TLRMdSwReq_6_Reserved";
VAL_ 955 TSRSwReq 0 "TSRSwReq_0_no_request" 1 "TSRSwReq_1_Off" 2 "TSRSwReq_2_On";
VAL_ 955 NonDirectDMSSwReq 0 "NonDirectDMSSwReq_0_NoRequest" 1 "NonDirectDMSSwReq_1_off" 2 "NonDirectDMSSwReq_2_on" 3 "NonDirectDMSSwReq_3_reserved";
VAL_ 955 SpdLmtOfstSetNumReq 0 "SpdLmtOfstSetNumReq_0_NoRequest" 1 "SpdLmtOfstSetNumReq_1_0_km_h" 2 "SpdLmtOfstSetNumReq_2_5_km_h" 3 "SpdLmtOfstSetNumReq_3_10_km_h" 4 "SpdLmtOfstSetNumReq_4_15_km_h" 5 "SpdLmtOfstSetNumReq_5_20_km_h" 6 "SpdLmtOfstSetNumReq_6__5_km_h" 7 "SpdLmtOfstSetNumReq_7__10_km_h" 8 "SpdLmtOfstSetNumReq_8__15_km_h" 9 "SpdLmtOfstSetNumReq_9__20_km_h" 10 "SpdLmtOfstSetNumReq_10_reserved" 11 "SpdLmtOfstSetNumReq_11_reserved" 12 "SpdLmtOfstSetNumReq_12_reserved" 13 "SpdLmtOfstSetNumReq_13_reserved" 14 "SpdLmtOfstSetNumReq_14_reserved";
VAL_ 955 ILCSwReq 0 "ILCSwReq_0_NoRequest" 1 "ILCSwReq_1_off" 2 "ILCSwReq_2_on" 3 "ILCSwReq_3_reserved";
VAL_ 955 ASSInhBtnA 0 "ASSInhBtnA_0_False" 1 "ASSInhBtnA_1_True";
VAL_ 955 ClstrElecCsumpUnit 0 "ClstrElecCsumpUnit_0_invalid" 1 "ClstrElecCsumpUnit_1_kWh_100km" 2 "ClstrElecCsumpUnit_2_km_kWh" 3 "ClstrElecCsumpUnit_3_miles_kWh" 4 "ClstrElecCsumpUnit_4_reserved" 5 "ClstrElecCsumpUnit_5_reserved" 6 "ClstrElecCsumpUnit_6_reserved" 7 "ClstrElecCsumpUnit_7_reserved";
VAL_ 955 SpdLmtOfstSetPercReq 0 "SpdLmtOfstSetPercReq_0_NoRequest" 1 "SpdLmtOfstSetPercReq_1_0" 2 "SpdLmtOfstSetPercReq_2_5" 3 "SpdLmtOfstSetPercReq_3_10" 4 "SpdLmtOfstSetPercReq_4_20" 5 "SpdLmtOfstSetPercReq_5__5" 6 "SpdLmtOfstSetPercReq_6__10" 7 "SpdLmtOfstSetPercReq_7__20";
VAL_ 955 EBSBatSOFVol2Sts 0 "EBSBatSOFVol2Sts_0_deviation_800mv" 1 "deviation_1_400mv" 2 "deviation_2_400mv" 3 "EBSBatSOFVol2Sts_3_illogical_Value";
VAL_ 955 ASSStsFICM 0 "ASSStsFICM_0_Off" 1 "ASSStsFICM_1_on";
VAL_ 955 EBSBatSOFVol1Sts 0 "deviation_0_800mv" 1 "deviation_1_400mv" 2 "deviation_2_400mv" 3 "EBSBatSOFVol1Sts_3_illogical_Value";
VAL_ 955 GenrExctnDutyCyc 30 "GenrExctnDutyCyc_30__100percent" 31 "GenrExctnDutyCyc_31__Invalid";
VAL_ 955 IACCPreSpdLimtSwReq 0 "IACCPreSpdLimtSwReq_0_NoRequest" 1 "IACCPreSpdLimtSwReq_1_Off" 2 "IACCPreSpdLimtSwReq_2_On" 3 "IACCPreSpdLimtSwReq_3_Reserve";
VAL_ 955 PMDCIlgclIdficn 0 "PMDCIlgclIdficn_0_False" 1 "PMDCIlgclIdficn_1_True";
VAL_ 955 EBSBatIncnstncyFlag 0 "EBSBatIncnstncyFlag_0_False" 1 "EBSBatIncnstncyFlag_1_True";
VAL_ 955 ASSStsFICMV 0 "ASSStsFICMV_0_Valid" 1 "ASSStsFICMV_1_Invalid";
VAL_ 955 PMDCIlgclCal 0 "PMDCIlgclCal_0_False" 1 "PMDCIlgclCal_1_True";
VAL_ 955 IdleBstLvl 0 "IdleBstLvl_0_ET_No_Boost_Requsted" 1 "IdleBstLvl_1_ET_Boost_level1" 2 "IdleBstLvl_2_ET_Boost_level2" 3 "IdleBstLvl_3_ET_Boost_level3";
VAL_ 955 ExtnlTstrDet 0 "ExtnlTstrDet_0_False" 1 "ExtnlTstrDet_1_True";
VAL_ 955 TiltSnsrSetngReq 0 "TiltSnsrSetngReq_0_No_Request" 1 "TiltSnsrSetngReq_1_Enabled" 2 "TiltSnsrSetngReq_2_Disabled" 3 "TiltSnsrSetngReq_3_Reserved";
VAL_ 955 RrSsdAppCtrl 0 "FrSsdAppCtrl_0_No_Request" 1 "FrSsdAppCtrl_1_Auto_Open" 2 "FrSsdAppCtrl_2_Auto_Close" 3 "FrSsdAppCtrl_3_Stop";
VAL_ 955 IACCOvTSuppresSwReq 0 "IACCOvTSuppresSwReq_0_no_request" 1 "IACCOvTSuppresSwReq_1_Off" 2 "IACCOvTSuppresSwReq_2_Left" 3 "IACCOvTSuppresSwReq_3_Right" 4 "IACCOvTSuppresSwReq_4_Auto" 5 "IACCOvTSuppresSwReq_5_Reserve" 6 "IACCOvTSuppresSwReq_6_Reserve" 7 "IACCOvTSuppresSwReq_7_Reserve";
VAL_ 955 DMSHapticWrnngReq 0 "DMSHapticWrnngReq_0_Norequest" 1 "DMSHapticWrnngReq_1_Off" 2 "DMSHapticWrnngReq_2_On" 3 "DMSHapticWrnngReq_3_reserved";
VAL_ 955 DMSAdoWrnngReq 0 "DMSAdoWrnngReq_0_Norequest" 1 "DMSAdoWrnngReq_1_Off" 2 "DMSAdoWrnngReq_2_On" 3 "DMSAdoWrnngReq_3_reserved";
VAL_ 955 VolmcSnsrSetngReq 0 "VolmcSnsrSetngReq_0_No_Request" 1 "VolmcSnsrSetngReq_1_Enabled" 2 "VolmcSnsrSetngReq_2_Disabled" 3 "VolmcSnsrSetngReq_3_Reserved";
VAL_ 955 DMSDstrctnHptWrnngReq 0 "DMSDstrctnHptWrnngReq_0_Norequest" 1 "DMSDstrctnHptWrnngReq_1_Off" 2 "DMSDstrctnHptWrnngReq_2_On" 3 "DMSDstrctnHptWrnngReq_3_reserved";
VAL_ 955 DMSDstrctnAdoWrnngReq 0 "DMSDstrctnAdoWrnngReq_0_Norequest" 1 "DMSDstrctnAdoWrnngReq_1_Off" 2 "DMSDstrctnAdoWrnngReq_2_On" 3 "DMSDstrctnAdoWrnngReq_3_reserved";
VAL_ 955 DMSDstrctnSwReq 0 "DMSDstrctnSwReq_0_Norequest" 1 "DMSDstrctnSwReq_1_Off" 2 "DMSDstrctnSwReq_2_On" 3 "DMSDstrctnSwReq_3_reserved";
VAL_ 955 DMSSwReq 0 "DMSSwReq_0_Norequest" 1 "DMSSwReq_1_Off" 2 "DMSSwReq_2_On" 3 "DMSSwReq_3_reserved";
VAL_ 955 FICMInnrDschrgReq 0 "FICMInnrDschrgReq_0_Disable" 1 "FICMInnrDschrgReq_1_Enable";
VAL_ 955 OMSSwReq 0 "OMSSwReq_0_Norequest" 1 "OMSSwReq_1_Off" 2 "OMSSwReq_2_On" 3 "OMSSwReq_3_reserved";
VAL_ 955 TrgtSOCReqAIV 0 "TrgtSOCReqAIV_0_Valid" 1 "TrgtSOCReqAIV_1_Invalid";
VAL_ 955 OMSBabyCareReq 0 "OMSBabyCareReq_0_Norequest" 1 "OMSBabyCareReq_1_Off" 2 "OMSBabyCareReq_2_On" 3 "OMSBabyCareReq_3_reserved";
VAL_ 955 OmsGesDetSwReq 0 "OmsGesDetSwReq_0_Norequest" 1 "OmsGesDetSwReq_1_Off" 2 "OmsGesDetSwReq_2_On" 3 "OmsGesDetSwReq_3_reserved";
VAL_ 955 OmsIlbRemSwReq 0 "OmsIlbRemSwReq_0_Norequest" 1 "OmsIlbRemSwReq_1_Off" 2 "OmsIlbRemSwReq_2_On" 3 "OmsIlbRemSwReq_3_reserved";
VAL_ 955 AIParkngSSPLotSw 0 "AIParkngSSPLotSw_0_no_reqest" 1 "AIParkngSSPLotSw_1_Off" 2 "AIParkngSSPLotSw_2_On";
VAL_ 955 TakeKeyOutRmndrPersSetReq 0 "TakeKeyOutRmndrPersSetReq_0_no_request" 1 "TakeKeyOutRmndrPersSetReq_1_disable" 2 "TakeKeyOutRmndrPersSetReq_2_enable" 3 "TakeKeyOutRmndrPersSetReq_3_reserve";
VAL_ 955 CmftUnlckPersSetReq 0 "CmftUnlckPersSetReq_0_no_request" 1 "CmftUnlckPersSetReq_1_disable" 2 "CmftUnlckPersSetReq_2_enable" 3 "CmftUnlckPersSetReq_3_reserve";
VAL_ 955 CmftLckPersSetReq 0 "CmftLckPersSetReq_0_no_request" 1 "CmftLckPersSetReq_1_disable" 2 "CmftLckPersSetReq_2_enable" 3 "CmftLckPersSetReq_3_reserve";
VAL_ 746 FCTSysSelReq 0 "FCTSysSelReq_0_no_request" 1 "FCTSysSelReq_1_driver_switch_FCTA_off_request" 2 "FCTSysSelReq_2_driver_switch_FCTA_on_request" 3 "FCTSysSelReq_3_driver_switch_FCTB__FCTA__on_request";
VAL_ 368 CCSpdDecAndIncVcCmd 0 "CCSpdDecAndIncVcCmd_0_NoRequest" 1 "CCSpdDecAndIncVcCmd_1_SpeedDecrease" 2 "CCSpdDecAndIncVcCmd_2_SpeedIncrease" 3 "CCSpdDecAndIncVcCmd_3_reserved";
VAL_ 368 CCDisDecAndIncVcCmd 0 "CCDisDecAndIncVcCmd_0_NoRequest" 1 "CCDisDecAndIncVcCmd_1_DistanceDecrease" 2 "CCDisDecAndIncVcCmd_2_DistanceIncrease" 3 "CCDisDecAndIncVcCmd_3_reserved";
VAL_ 368 CCSwStsSetSwA 0 "CCSwStsSetSwA_0_False" 1 "CCSwStsSetSwA_1_True";
VAL_ 368 CCSwStsCCASwA 0 "CCSwStsCCASwA_0_False" 1 "CCSwStsCCASwA_1_True";
VAL_ 368 CCSpdVcCmdSwReq 0 "CCSpdVcCmdSwReq_0_NoRequest" 1 "CCSpdVcCmdSwReq_1_off" 2 "CCSpdVcCmdSwReq_2_on" 3 "CCSpdVcCmdSwReq_3_reserved";
VAL_ 368 CCDisAdjtVcCmd 0 "CCDisAdjtVcCmd_0_NoRequest" 1 "CCDisAdjtVcCmd_1_Distance1" 2 "CCDisAdjtVcCmd_2_Distance2" 3 "CCDisAdjtVcCmd_3_Distance3" 4 "CCDisAdjtVcCmd_4_Distance4" 5 "CCDisAdjtVcCmd_5_Distance5";
VAL_ 1111 ICCPCBTemp1 255 "ICCPCBTemp1_255_Invalid_Value";
VAL_ 1111 ICCPCBTemp2 255 "ICCPCBTemp2_255_Invalid_Value";
VAL_ 1111 ICCPCBTemp3 255 "ICCPCBTemp3_255_Invalid_Value";
VAL_ 1111 ICCPCBTemp4 255 "ICCPCBTemp4_255_Invalid_Value";
VAL_ 1111 ICCPCBTemp5 255 "ICCPCBTemp5_255_Invalid_Value";
VAL_ 1111 ICCThermalCoolingLvl 0 "ICCThermalCoolingLvl_0_abnormal" 1 "ICCThermalCoolingLvl_1_Thermal_Cooling_level_1" 2 "ICCThermalCoolingLvl_2_Thermal_Cooling_level_2" 3 "ICCThermalCoolingLvl_3_Thermal_Cooling_level_3" 4 "ICCThermalCoolingLvl_4_Thermal_Cooling_level_4" 5 "ICCThermalCoolingLvl_5_reserved" 6 "ICCThermalCoolingLvl_6_reserved" 7 "ICCThermalCoolingLvl_7_reserved" 8 "ICCThermalCoolingLvl_8_reserved" 9 "ICCThermalCoolingLvl_9_reserved" 10 "ICCThermalCoolingLvl_10_reserved" 11 "ICCThermalCoolingLvl_11_reserved" 12 "ICCThermalCoolingLvl_12_reserved" 13 "ICCThermalCoolingLvl_13_reserved" 14 "ICCThermalCoolingLvl_14_reserved" 15 "ICCThermalCoolingLvl_15_reserved";
VAL_ 1111 FICMV2XEnEnbReq 0 "FICMV2XEnEnbReq_0_Default" 1 "FICMV2XEnEnbReq_1_Enable" 2 "FICMV2XEnEnbReq_2_Disable";
VAL_ 527 DrvrDstcnStsINST_IMM 0 "DrvrDstcnStsINST_IMM_0_Unknown" 1 "DrvrDstcnStsINST_IMM_1_Nodistraction" 2 "DrvrDstcnStsINST_IMM_2_Lowleveldistraction" 3 "DrvrDstcnStsINST_IMM_3_Middleleveldistraction" 4 "DrvrDstcnStsINST_IMM_4_Highleveldistraction";
VAL_ 527 ILBRReq_IMM 0 "ILBRReq_IMM_0_Unknown" 1 "ILBRReq_IMM_1_NoItemLeft" 2 "ILBRReq_IMM_2_BagLeft" 3 "ILBRReq_IMM_3_PCLeft" 4 "ILBRReq_IMM_4_PhoneLeft" 5 "ILBRReq_IMM_5_Reserved";
VAL_ 527 DrvrAbnormBehvor_IMM 0 "DrvrAbnormBehvor_IMM_0_Unknown" 1 "DrvrAbnormBehvor_IMM_1_Noabnormalbehaviour" 2 "DrvrAbnormBehvor_IMM_2_Telephonecalls" 3 "DrvrAbnormBehvor_IMM_3_Smoking" 4 "DrvrAbnormBehvor_IMM_4_Drinking" 5 "DrvrAbnormBehvor_IMM_5_Eating" 6 "DrvrAbnormBehvor_IMM_6_resevered" 7 "DrvrAbnormBehvor_IMM_7_resevered" 8 "DrvrAbnormBehvor_IMM_8_resevered";
VAL_ 527 DMSSts_IMM 0 "DMSSts_IMM_0_Off" 1 "DMSSts_IMM_1_Standby" 2 "DMSSts_IMM_2_Active" 3 "DMSSts_IMM_3_Camera_Blocked" 4 "DMSSts_IMM_4_System_temporary_unavailable" 5 "DMSSts_IMM_5_Service_required" 6 "DMSSts_IMM_6_InitializatiOn" 7 "DMSSts_IMM_7_Performance_Degradation" 8 "DMSSts_IMM_8_resevered" 9 "DMSSts_IMM_9_resevered" 10 "DMSSts_IMM_10_resevered" 11 "DMSSts_IMM_11_resevered" 12 "DMSSts_IMM_12_resevered" 13 "DMSSts_IMM_13_resevered" 14 "DMSSts_IMM_14_resevered" 15 "DMSSts_IMM_15_resevered";
VAL_ 527 SpfngDet_IMM 0 "SpfngDet_IMM_0_Unknown" 1 "SpfngDet_IMM_1_NotDetected" 2 "SpfngDet_IMM_2_Detected" 3 "SpfngDet_IMM_3_Reserve";
VAL_ 527 DrvrDstcnSts_IMM 0 "DrvrDstcnSts_IMM_0_Unknown" 1 "DrvrDstcnSts_IMM_1_Nodistraction" 2 "DrvrDstcnSts_IMM_2_Lowleveldistraction" 3 "DrvrDstcnSts_IMM_3_Middleleveldistraction" 4 "DrvrDstcnSts_IMM_4_Highleveldistraction" 5 "DrvrDstcnSts_IMM_5_resevered" 6 "DrvrDstcnSts_IMM_6_resevered" 7 "DrvrDstcnSts_IMM_7_resevered";
VAL_ 527 OMSSts_IMM 0 "OMSSts_IMM_0_Off" 1 "OMSSts_IMM_1_Standby" 2 "OMSSts_IMM_2_Active" 3 "OMSSts_IMM_3_Camera_Blocked" 4 "OMSSts_IMM_4_System_temporary_unavailable" 5 "OMSSts_IMM_5_Service_required" 6 "OMSSts_IMM_6_InitializatiOn" 7 "OMSSts_IMM_7_Performance_Degradation";
VAL_ 527 DrvrFtgLvlINST_IMM 0 "DrvrFtgLvlINST_IMM_0_Unknown" 1 "DrvrFtgLvlINST_IMM_1_NoDrowsiness" 2 "DrvrFtgLvlINST_IMM_2_LowlevelDrowsiness" 3 "DrvrFtgLvlINST_IMM_3_MiddlelevelDrowsiness" 4 "DrvrFtgLvlINST_IMM_4_HighlevelDrowsiness" 5 "DrvrFtgLvlINST_IMM_5_Unresponsive";
VAL_ 527 DrvrFtgLvl_IMM 0 "DrvrFtgLvl_IMM_0_Unknown" 1 "DrvrFtgLvl_IMM_1_NoDrowsiness" 2 "DrvrFtgLvl_IMM_2_LowlevelDrowsiness" 3 "DrvrFtgLvl_IMM_3_MiddlelevelDrowsiness" 4 "DrvrFtgLvl_IMM_4_HighlevelDrowsiness" 5 "DrvrFtgLvl_IMM_5_Unresponsive" 6 "DrvrFtgLvl_IMM_6_resevered" 7 "DrvrFtgLvl_IMM_7_resevered" 8 "DrvrFtgLvl_IMM_8_resevered";
VAL_ 527 DrvrPrst_IMM 0 "DrvrPrst_IMM_0_Unknown" 1 "DrvrPrst_IMM_1_DriverNotPresence" 2 "DrvrPrst_IMM_2_DriverPresence";
VAL_ 527 DrvrGazeRgn_IMM 0 "DrvrGazeRgn_IMM_0_init_Unknown" 1 "DrvrGazeRgn_IMM_1_DriverSideofWindscreen" 2 "DrvrGazeRgn_IMM_2_CopilotSideofWindscreen" 3 "DrvrGazeRgn_IMM_3_LeftRearViewMirror" 4 "DrvrGazeRgn_IMM_4_RightRearViewMirror" 5 "DrvrGazeRgn_IMM_5_LeftSideWindow" 6 "DrvrGazeRgn_IMM_6_RightSideWindow" 7 "DrvrGazeRgn_IMM_7_CentralRearViewMirror" 8 "DrvrGazeRgn_IMM_8_CentraldriversInstrumentCluster_speedgauge" 9 "DrvrGazeRgn_IMM_9_Headupdisplay" 10 "DrvrGazeRgn_IMM_10_NavigationDisplay" 11 "DrvrGazeRgn_IMM_11_MiddleInstrumentCluster_AorC_radio" 12 "DrvrGazeRgn_IMM_12_SteeringWheel" 13 "DrvrGazeRgn_IMM_13_LeftSeatFootArea" 14 "DrvrGazeRgn_IMM_14_RightSeatFootAreaandWorkbench" 15 "DrvrGazeRgn_IMM_15_LeftSidedoorarea" 16 "DrvrGazeRgn_IMM_16_RightSidedoorarea";
VAL_ 527 EyeOpenStatus_IMM 0 "EyeOpenStatus_IMM_0_eyeOpen" 1 "EyeOpenStatus_IMM_1_eyeClose" 2 "EyeOpenStatus_IMM_2_eyeoneopen_oneclose" 3 "EyeOpenStatus_IMM_3_invalid";
VAL_ 527 RightEyeOccludeStatus_IMM 0 "RightEyeOccludeStatus_IMM_0_noOcclude" 1 "RightEyeOccludeStatus_IMM_1_Occlude" 2 "RightEyeOccludeStatus_IMM_2_reserved" 3 "RightEyeOccludeStatus_IMM_3_reserved";
VAL_ 527 LeftEyeOccludeStatus_IMM 0 "LeftEyeOccludeStatus_IMM_0_noOcclude" 1 "LeftEyeOccludeStatus_IMM_1_Occlude" 2 "LeftEyeOccludeStatus_IMM_2_reserved" 3 "LeftEyeOccludeStatus_IMM_3_reserved";
VAL_ 527 EyeOnRoad_IMM 0 "EyeOnRoad_IMM_0_Unavailable" 1 "EyeOnRoad_IMM_1_EyesOnRoad" 2 "EyeOnRoad_IMM_2_EyesOffRoad_drivingtaskrelatedregion" 3 "EyeOnRoad_IMM_3_EyesOffRoad_non_drivingtaskrelatedregion";
VAL_ 527 MouthOccludeStatus_IMM 0 "MouthOccludeStatus_IMM_0_nomouthOcclude" 1 "MouthOccludeStatus_IMM_1_mouthOcclude" 2 "MouthOccludeStatus_IMM_2_reserved" 3 "MouthOccludeStatus_IMM_3_reserved";
VAL_ 527 YawnStatus_IMM 0 "YawnStatus_IMM_0_noyawn" 1 "YawnStatus_IMM_1_yawn" 2 "YawnStatus_IMM_2_reserved" 3 "YawnStatus_IMM_3_reserved";
VAL_ 1237 IMM_NM_BSMtoRMS_BKPCANFD 0 "IMM_NM_BSMtoRMS_BKPCANFD_0_False" 1 "IMM_NM_BSMtoRMS_BKPCANFD_1_True";
VAL_ 1237 IMM_NM_PBSMtoRMS_BKPCANFD 0 "IMM_NM_PBSMtoRMS_BKPCANFD_0_False" 1 "IMM_NM_PBSMtoRMS_BKPCANFD_1_True";
VAL_ 1237 IMM_NM_RMStoNOS_BKPCANFD 0 "IMM_NM_RMStoNOS_BKPCANFD_0_False" 1 "IMM_NM_RMStoNOS_BKPCANFD_1_True";
VAL_ 1237 IMM_NM_RSStoNOS_BKPCANFD 0 "IMM_NM_RSStoNOS_BKPCANFD_0_False" 1 "IMM_NM_RSStoNOS_BKPCANFD_1_True";
VAL_ 1237 IMM_NM_RSStoRMS_BKPCANFD 0 "IMM_NM_RSStoRMS_BKPCANFD_0_False" 1 "IMM_NM_RSStoRMS_BKPCANFD_1_True";
VAL_ 1237 IMM_NM_NOStoRMS_BKPCANFD 0 "IMM_NM_NOStoRMS_BKPCANFD_0_False" 1 "IMM_NM_NOStoRMS_BKPCANFD_1_True";
VAL_ 1237 IMM_NM_NOSSta_BKPCANFD 0 "IMM_NM_NOSSta_BKPCANFD_0_False" 1 "IMM_NM_NOSSta_BKPCANFD_1_True";
VAL_ 1237 IMM_NM_RMSSta_BKPCANFD 0 "IMM_NM_RMSSta_BKPCANFD_0_False" 1 "IMM_NM_RMSSta_BKPCANFD_1_True";
VAL_ 1237 IMM_NWI_BKPCANFD 0 "IMM_NWI_BKPCANFD_0_NoWakeNetworkSource";
VAL_ 1237 IMM_NOI_BKPCANFD 0 "IMM_NOI_BKPCANFD_0_NoRequest" 65535 "IMM_NOI_BKPCANFD_65535_AllNetworkOperationActive";
VAL_ 1237 IMM_NKI_BKPCANFD 0 "IMM_NKI_BKPCANFD_0_NoRequest" 1 "IMM_NKI_BKPCANFD_1_PowerModeIsNonOFF" 2 "IMM_NKI_BKPCANFD_2_ForgetRemind";
SIG_GROUP_ 907 IICBVC_100ms_Group80 1 : FrtPsngAirbagSwStsReqV_Sfty FrtPsngAirbagSwStsReq_Sfty ICBVC_100ms_Group80_CRC ICBVC_100ms_Group80_RC ICBVC_100ms_Group80_Reserved1 ICBVC_100ms_Group80_Reserved2 ICBVC_100ms_Group80_Reserved3 VehDrvngMd VehLdShedLvl VehOdo VehOdoV;
SIG_GROUP_ 1151 IICBVC_200ms_Group79 1 : ClstrDspdAirbagWrnng EPTNotReadyReq ICBVC_200ms_Group79_CRC ICBVC_200ms_Group79_RC ICBVC_200ms_Group79_Reserved1 ICBVC_200ms_Group79_Reserved2 OdoPriyPrcs OdoPriyPrcsV TrlrMdSts;
SIG_GROUP_ 497 IICBVC_20ms_Group03 1 : AMRPrtensonReq BPMMstrAvlbly ICBVC_20ms_Group03_CRC ICBVC_20ms_Group03_RC ICBVC_20ms_Group03_Reserved1 ICBVC_20ms_Group03_Reserved2 ICBVC_20ms_Group03_Reserved3 ICBVC_20ms_Group03_Reserved4 PwrMdMstrAccryA PwrMdMstrRunCrkA SysOpnlMd SysPwrMd SysPwrMdV SysVol SysVolMd SysVolMdV SysVolV UsgMd UsgMdV VehMd VehMdV;
SIG_GROUP_ 368 IICBVC_50ms_Group158 1 : CCDisAdjtVcCmd CCDisDecAndIncVcCmd CCSpdDecAndIncVcCmd CCSpdVcCmd CCSpdVcCmdSwReq CCSwStsCCASwA CCSwStsSetSwA ICBVC_50ms_Group158_CRC ICBVC_50ms_Group158_RC ICBVC_50ms_Group158_Reserved1 ICBVC_50ms_Group158_Reserved10 ICBVC_50ms_Group158_Reserved11 ICBVC_50ms_Group158_Reserved12 ICBVC_50ms_Group158_Reserved13 ICBVC_50ms_Group158_Reserved2 ICBVC_50ms_Group158_Reserved3 ICBVC_50ms_Group158_Reserved4 ICBVC_50ms_Group158_Reserved5 ICBVC_50ms_Group158_Reserved6 ICBVC_50ms_Group158_Reserved7 ICBVC_50ms_Group158_Reserved8 ICBVC_50ms_Group158_Reserved9;
SIG_GROUP_ 527 IIMM_50ms_Group02 1 : DMSSts_IMM DrvrAbnormBehvor_IMM DrvrAbnormConf_IMM DrvrDstcnConf_IMM DrvrDstcnStsINST_IMM DrvrDstcnSts_IMM DrvrFtgConf_IMM DrvrFtgLvlINST_IMM DrvrFtgLvl_IMM DrvrGazeRgn_IMM DrvrPrst_IMM EyeGazepitch_IMM EyeGazeyaw_IMM EyeOnRoad_IMM EyeOpenDegree_IMM EyeOpenStatus_IMM ILBRReq_IMM IMM_50ms_Group02_CRC IMM_50ms_Group02_RC IMM_50ms_Group02_Reserved1 IMM_50ms_Group02_Reserved10 IMM_50ms_Group02_Reserved143 IMM_50ms_Group02_Reserved151 IMM_50ms_Group02_Reserved159 IMM_50ms_Group02_Reserved2 IMM_50ms_Group02_Reserved3 IMM_50ms_Group02_Reserved4 IMM_50ms_Group02_Reserved5 IMM_50ms_Group02_Reserved6 IMM_50ms_Group02_Reserved7 IMM_50ms_Group02_Reserved8 IMM_50ms_Group02_Reserved9 LeftEyeOccludeStatus_IMM MouthOccludeStatus_IMM OMSSts_IMM RightEyeOccludeStatus_IMM SpfngDet_IMM YawnStatus_IMM;
